VERSION ""

NS_ :

BS_:

BU_: Shelf7 Shelf6 Shelf5 Shelf4 Shelf3 DebugLaptop RackController Shelf2 Shelf1
VAL_TABLE_ ShelfThermal_FanState_Table 3 "Fan Locked Rotor" 2 "Fan Speed Slow" 1 "Fan Unplugged" 0 "Fan Nominal" ;
VAL_TABLE_ ModuleMultiplexor_Table 31 "Module 7, Max" 30 "Module 7, Avg" 29 "Module 7, Min" 27 "Module 6, Max" 26 "Module 6, Avg" 25 "Module 6, Min" 23 "Module 5, Max" 22 "Module 5, Avg" 21 "Module 5, Min" 19 "Module 4, Max" 18 "Module 4, Avg" 17 "Module 4, Min" 15 "Module 3, Max" 14 "Module 3, Avg" 13 "Module 3, Min" 11 "Module 2, Max" 10 "Module 2, Avg" 9 "Module 2, Min" 7 "Module 1, Max" 6 "Module 1, Avg" 5 "Module 1, Min" ;

BO_ 3221225472 VECTOR__INDEPENDENT_SIG_MSG: 0 Vector__XXX
 SG_ RackElectrical_24VPower : 0|8@1+ (1,0) [0|255] "W" Vector__XXX
 SG_ RackThermal_AvgCellTemp : 0|8@1+ (0.5,-40) [-40|87.5] "degC" Vector__XXX
 SG_ RackThermal_MinCellTemp : 0|8@1+ (0.5,-40) [-40|87.5] "degC" Vector__XXX
 SG_ RackThermal_MaxCellTemp : 0|8@1+ (0.5,-40) [-40|87.5] "degC" Vector__XXX
 SG_ RackThermal_AmbientTemp : 0|8@1+ (0.5,-40) [-40|87.5] "degC" Vector__XXX
 SG_ RackElectrical_StateOfCharge : 0|8@1+ (0.5,0) [0|100] "%" Vector__XXX
 SG_ RackElectrical_Current : 0|12@1+ (0.05,-102.4) [-100|100] "A" Vector__XXX
 SG_ RackElectrical_BusVoltage : 0|16@1+ (0.02,0) [0|830] "V" Vector__XXX
 SG_ RackElectrical_BatteryVoltage : 0|16@1+ (0.02,0) [0|830] "V" Vector__XXX
 SG_ SetBalanceFet_S1M3C18 : 0|1@1+ (1,0) [0|0] "" Vector__XXX
 SG_ SetBalanceFet_S1M3C17 : 0|1@1+ (1,0) [0|0] "" Vector__XXX
 SG_ SetBalanceFet_S1M3C16 : 0|1@1+ (1,0) [0|0] "" Vector__XXX
 SG_ SetBalanceFet_S1M3C15 : 0|1@1+ (1,0) [0|0] "" Vector__XXX
 SG_ SetBalanceFet_S1M3C14 : 0|1@1+ (1,0) [0|0] "" Vector__XXX
 SG_ SetBalanceFet_S1M3C13 : 0|1@1+ (1,0) [0|0] "" Vector__XXX
 SG_ SetBalanceFet_S1M3C12 : 0|1@1+ (1,0) [0|0] "" Vector__XXX
 SG_ SetBalanceFet_S1M3C11 : 0|1@1+ (1,0) [0|0] "" Vector__XXX
 SG_ SetBalanceFet_S1M3C10 : 0|1@1+ (1,0) [0|0] "" Vector__XXX
 SG_ SetBalanceFet_S1M3C09 : 0|1@1+ (1,0) [0|0] "" Vector__XXX
 SG_ SetBalanceFet_S1M3C08 : 0|1@1+ (1,0) [0|0] "" Vector__XXX
 SG_ SetBalanceFet_S1M3C07 : 0|1@1+ (1,0) [0|0] "" Vector__XXX
 SG_ SetBalanceFet_S1M3C06 : 0|1@1+ (1,0) [0|0] "" Vector__XXX
 SG_ SetBalanceFet_S1M3C05 : 0|1@1+ (1,0) [0|0] "" Vector__XXX
 SG_ SetBalanceFet_S1M3C04 : 0|1@1+ (1,0) [0|0] "" Vector__XXX
 SG_ SetBalanceFet_S1M3C03 : 0|1@1+ (1,0) [0|0] "" Vector__XXX
 SG_ SetBalanceFet_S1M3C02 : 0|1@1+ (1,0) [0|0] "" Vector__XXX
 SG_ SetBalanceFet_S1M3C01 : 0|1@1+ (1,0) [0|0] "" Vector__XXX
 SG_ SetBalanceFet_S1M2C18 : 0|1@1+ (1,0) [0|0] "" Vector__XXX
 SG_ SetBalanceFet_S1M2C17 : 0|1@1+ (1,0) [0|0] "" Vector__XXX
 SG_ SetBalanceFet_S1M2C16 : 0|1@1+ (1,0) [0|0] "" Vector__XXX
 SG_ SetBalanceFet_S1M2C15 : 0|1@1+ (1,0) [0|0] "" Vector__XXX
 SG_ SetBalanceFet_S1M2C14 : 0|1@1+ (1,0) [0|0] "" Vector__XXX
 SG_ SetBalanceFet_S1M2C13 : 0|1@1+ (1,0) [0|0] "" Vector__XXX
 SG_ SetBalanceFet_S1M2C12 : 0|1@1+ (1,0) [0|0] "" Vector__XXX
 SG_ SetBalanceFet_S1M2C11 : 0|1@1+ (1,0) [0|0] "" Vector__XXX
 SG_ SetBalanceFet_S1M2C10 : 0|1@1+ (1,0) [0|0] "" Vector__XXX
 SG_ SetBalanceFet_S1M2C09 : 0|1@1+ (1,0) [0|0] "" Vector__XXX
 SG_ SetBalanceFet_S1M2C08 : 0|1@1+ (1,0) [0|0] "" Vector__XXX
 SG_ SetBalanceFet_S1M2C07 : 0|1@1+ (1,0) [0|0] "" Vector__XXX
 SG_ SetBalanceFet_S1M2C06 : 0|1@1+ (1,0) [0|0] "" Vector__XXX
 SG_ SetBalanceFet_S1M2C05 : 0|1@1+ (1,0) [0|0] "" Vector__XXX
 SG_ SetBalanceFet_S1M2C04 : 0|1@1+ (1,0) [0|0] "" Vector__XXX
 SG_ SetBalanceFet_S1M2C03 : 0|1@1+ (1,0) [0|0] "" Vector__XXX
 SG_ SetBalanceFet_S1M2C02 : 0|1@1+ (1,0) [0|0] "" Vector__XXX
 SG_ SetBalanceFet_S1M2C01 : 0|1@1+ (1,0) [0|0] "" Vector__XXX
 SG_ SetBalanceFet_S1M1C18 : 0|1@1+ (1,0) [0|0] "" Vector__XXX
 SG_ SetBalanceFet_S1M1C17 : 0|1@1+ (1,0) [0|0] "" Vector__XXX
 SG_ SetBalanceFet_S1M1C16 : 0|1@1+ (1,0) [0|0] "" Vector__XXX
 SG_ SetBalanceFet_S1M1C15 : 0|1@1+ (1,0) [0|0] "" Vector__XXX
 SG_ SetBalanceFet_S1M1C14 : 0|1@1+ (1,0) [0|0] "" Vector__XXX
 SG_ SetBalanceFet_S1M1C13 : 0|1@1+ (1,0) [0|0] "" Vector__XXX
 SG_ SetBalanceFet_S1M1C12 : 0|1@1+ (1,0) [0|0] "" Vector__XXX
 SG_ SetBalanceFet_S1M1C11 : 0|1@1+ (1,0) [0|0] "" Vector__XXX
 SG_ SetBalanceFet_S1M1C10 : 0|1@1+ (1,0) [0|0] "" Vector__XXX
 SG_ SetBalanceFet_S1M1C09 : 0|1@1+ (1,0) [0|0] "" Vector__XXX
 SG_ SetBalanceFet_S1M1C08 : 0|1@1+ (1,0) [0|0] "" Vector__XXX
 SG_ SetBalanceFet_S1M1C07 : 0|1@1+ (1,0) [0|0] "" Vector__XXX
 SG_ SetBalanceFet_S1M1C06 : 0|1@1+ (1,0) [0|0] "" Vector__XXX
 SG_ SetBalanceFet_S1M1C05 : 0|1@1+ (1,0) [0|0] "" Vector__XXX
 SG_ SetBalanceFet_S1M1C04 : 0|1@1+ (1,0) [0|0] "" Vector__XXX
 SG_ SetBalanceFet_S1M1C03 : 0|1@1+ (1,0) [0|0] "" Vector__XXX
 SG_ SetBalanceFet_S1M1C02 : 0|1@1+ (1,0) [0|0] "" Vector__XXX
 SG_ SetBalanceFet_S1M1C01 : 0|1@1+ (1,0) [0|0] "" Vector__XXX
 SG_ BalanceModuleMultiplexor : 0|6@1+ (1,0) [0|0] "" Vector__XXX
 SG_ SetpointLimit_WhichShelves : 0|8@1+ (1,0) [0|255] "" Vector__XXX
 SG_ SetpointLimit_UndervoltageLevel : 0|13@1+ (0.000610426077402027,0) [0|5] "V" Vector__XXX
 SG_ SetpointLimit_OvervoltageLevel : 0|13@1+ (0.000610426077402027,0) [0|5] "V" Vector__XXX
 SG_ SetpointLimit_Overtemp : 0|8@1+ (0.5,-40) [-40|87.5] "degC" Vector__XXX
 SG_ SetpointLimit_24VPowerLimit : 0|8@1+ (0.25,0) [0|63.75] "W" Vector__XXX
 SG_ ShelfParamMultiplexor_S1 : 0|1@1+ (1,0) [0|1] "" Vector__XXX
 SG_ ShelfParam_TopBalanceVolt_S1 : 0|13@1+ (0.000610426077402027,0) [0|5] "V" Vector__XXX
 SG_ ShelfParam_TargetBalanceVolt_S1 : 0|13@1+ (0.000610426077402027,0) [0|5] "V" Vector__XXX
 SG_ ShelfParam_DeltaBalanceVolt_S1 : 0|11@1+ (0.000610426077402027,0) [0|1.24954218044195] "V" Vector__XXX
 SG_ ShelfParam_BottomBalanceVolt_S1 : 0|13@1+ (0.000610426077402027,0) [0|5] "V" Vector__XXX
 SG_ ShelfParam_BalanceTurnOnVolt_S1 : 0|13@1+ (0.000610426077402027,0) [0|5] "V" Vector__XXX
 SG_ ShelfParam_BalanceTurnOffVolt_S1 : 0|13@1+ (0.000610426077402027,0) [0|5] "V" Vector__XXX
 SG_ SetpointThermal_MinTurnOn : 0|8@1+ (0.5,0) [0|0] "%" Vector__XXX
 SG_ SetpointThermal_LoopGain : 0|8@1+ (1,0) [0|0] "" Vector__XXX
 SG_ SetpointThermal_WhichShelves : 0|8@1+ (1,0) [0|255] "" Vector__XXX
 SG_ SetpointThermal_MinCell : 0|8@1+ (0.5,-40) [-40|87.5] "degC" Vector__XXX
 SG_ SetpointThermal_MaxChip : 0|8@1+ (0.5,-40) [-40|87.5] "degC" Vector__XXX
 SG_ SetpointThermal_MaxCell : 0|8@1+ (0.5,-40) [-40|87.5] "degC" Vector__XXX
 SG_ SetpointThermal_Delta_Shelf : 0|8@1+ (0.1,0) [0|25.5] "degC" Vector__XXX
 SG_ SetpointThermal_Delta_Module : 0|8@1+ (0.1,0) [0|25.5] "degC" Vector__XXX
 SG_ SetpointElec_External_WhichShelv : 0|8@1+ (1,0) [0|255] "" Vector__XXX
 SG_ SetpointElec_External_TargetBala : 0|13@1+ (0.000610426077402027,0) [0|5] "V" Vector__XXX
 SG_ SetpointElec_External_DeltaBalan : 0|11@1+ (0.000610426077402027,0) [0|1.24954218044195] "V" Vector__XXX
 SG_ SetpointElec_External_BottomBala : 0|13@1+ (0.000610426077402027,0) [0|5] "V" Vector__XXX
 SG_ ShelfThermal_LoopGain_S1 : 0|8@1+ (1,0) [0|0] "" Vector__XXX
 SG_ ShelfThermal_FanStateSummary_S1 : 0|2@1+ (1,0) [0|3] "" Vector__XXX
 SG_ ShelfThermal_FanSpeedAvg_S1 : 0|9@1+ (10,0) [0|5110] "RPM" Vector__XXX
 SG_ ShelfThermal_FanCommandAvg_S1 : 0|7@1+ (1,0) [0|100] "%" Vector__XXX
 SG_ ShelfThermal_FanState_S1FR : 0|2@1+ (1,0) [0|3] "" Vector__XXX
 SG_ ShelfThermal_FanState_S1FM : 0|2@1+ (1,0) [0|3] "" Vector__XXX
 SG_ ShelfThermal_FanState_S1FL : 0|2@1+ (1,0) [0|3] "" Vector__XXX
 SG_ ShelfThermalMultiplexor_S1 : 0|2@1+ (1,0) [0|3] "" Vector__XXX
 SG_ ShelfThermal_FanCommand_S1FR : 0|7@1+ (1,0) [0|100] "%" Vector__XXX
 SG_ ShelfThermal_FanCommand_S1FM : 0|7@1+ (1,0) [0|100] "%" Vector__XXX
 SG_ ShelfThermal_ActualTempDelta_S1 : 0|6@1+ (0.5,0) [0|31.5] "degC" Vector__XXX
 SG_ ShelfThermal_ActuallTempMax_S1 : 0|8@1+ (0.5,-40) [-40|87.5] "degC" Vector__XXX
 SG_ ShelfThermal_TargetTempMax_S1 : 0|8@1+ (0.5,-40) [-40|87.5] "degC" Vector__XXX
 SG_ ShelfThermal_TargetTempDelta_S1 : 0|6@1+ (0.5,0) [0|31.5] "degC" Vector__XXX
 SG_ ShelfThermal_FanSpeed_S1FR : 0|9@1+ (10,0) [0|5110] "RPM" Vector__XXX
 SG_ ShelfThermal_FanSpeed_S1FM : 0|9@1+ (10,0) [0|5110] "RPM" Vector__XXX
 SG_ ShelfThermal_FanSpeed_S1FL : 0|9@1+ (10,0) [0|5110] "RPM" Vector__XXX
 SG_ ShelfThermal_FanCommand_S1FL : 0|7@1+ (1,0) [0|100] "%" Vector__XXX
 SG_ ShelfThermal_AmbientTemp_S1 : 0|8@1+ (0.5,-40) [-40|87.5] "degC" Vector__XXX
 SG_ ChipSummaryVoltage_Min_S1 : 0|12@1+ (0.00732511292882432,0) [0|16] "V" Vector__XXX
 SG_ ChipSummaryVoltage_Max_S1 : 0|12@1+ (0.00732511292882432,0) [0|16] "V" Vector__XXX
 SG_ ChipSummaryVoltage_Avg_S1 : 0|12@1+ (0.00732511292882432,0) [0|16] "V" Vector__XXX
 SG_ ChipSummaryTemp_Min_S1 : 0|8@1+ (0.5,-40) [-40|87.5] "degC" Vector__XXX
 SG_ ChipSummaryTemp_Max_S1 : 0|8@1+ (0.5,-40) [-40|87.5] "degC" Vector__XXX
 SG_ ChipSummaryTemp_Avg_S1 : 0|8@1+ (0.5,-40) [-40|87.5] "degC" Vector__XXX
 SG_ ChipSummaryNumberOfChips : 0|4@1+ (1,0) [0|14] "" Vector__XXX
 SG_ ChipSummaryMultiplexor : 0|2@1+ (1,0) [0|3] "" Vector__XXX
 SG_ ChipSummaryFault_Watchdog_S1 : 0|1@1+ (1,0) [0|0] "" Vector__XXX
 SG_ ChipSummaryFault_VssOpen_S1 : 0|1@1+ (1,0) [0|0] "" Vector__XXX
 SG_ ChipSummaryFault_Vreg_S1 : 0|1@1+ (1,0) [0|0] "" Vector__XXX
 SG_ ChipSummaryFault_Vref_S1 : 0|1@1+ (1,0) [0|0] "" Vector__XXX
 SG_ ChipSummaryFault_VbatOpen_S1 : 0|1@1+ (1,0) [0|0] "" Vector__XXX
 SG_ ChipSummaryFault_UnderVolt_S1 : 0|1@1+ (1,0) [0|0] "" Vector__XXX
 SG_ ChipSummaryFault_OverVolt_S1 : 0|1@1+ (1,0) [0|0] "" Vector__XXX
 SG_ ChipSummaryFault_OverTemp_S1 : 0|1@1+ (1,0) [0|0] "" Vector__XXX
 SG_ ChipSummaryFault_Oscillator_S1 : 0|1@1+ (1,0) [0|0] "" Vector__XXX
 SG_ ChipSummaryFault_OpenWire_S1 : 0|1@1+ (1,0) [0|0] "" Vector__XXX
 SG_ ChipSummaryFault_Mux_S1 : 0|1@1+ (1,0) [0|0] "" Vector__XXX
 SG_ ChipSummaryFault_Checksum_S1 : 0|1@1+ (1,0) [0|0] "" Vector__XXX
 SG_ ChipSummaryCommSpeed : 0|2@1+ (1,0) [0|3] "" Vector__XXX
 SG_ ChipVoltage_S1M1Low : 0|12@1+ (0.00732511292882432,0) [0|16] "V" Vector__XXX
 SG_ ChipVoltage_S1M1High : 0|12@1+ (0.00732511292882432,0) [0|16] "V" Vector__XXX
 SG_ ChipVoltage_S1M2Low : 0|12@1+ (0.00732511292882432,0) [0|16] "V" Vector__XXX
 SG_ ChipVoltage_S1M2High : 0|12@1+ (0.00732511292882432,0) [0|16] "V" Vector__XXX
 SG_ ChipVoltage_S1M3Low : 0|12@1+ (0.00732511292882432,0) [0|16] "V" Vector__XXX
 SG_ ChipVoltage_S1M3High : 0|12@1+ (0.00732511292882432,0) [0|16] "V" Vector__XXX
 SG_ ChipVoltage_S1M4Low : 0|12@1+ (0.00732511292882432,0) [0|16] "V" Vector__XXX
 SG_ ChipVoltage_S1M4High : 0|12@1+ (0.00732511292882432,0) [0|16] "V" Vector__XXX
 SG_ ChipVoltage_S1M5Low : 0|12@1+ (0.00732511292882432,0) [0|16] "V" Vector__XXX
 SG_ ChipVoltage_S1M5High : 0|12@1+ (0.00732511292882432,0) [0|16] "V" Vector__XXX
 SG_ ChipTemp_S1M1Low : 0|8@1+ (0.5,-40) [-40|87.5] "degC" Vector__XXX
 SG_ ChipTemp_S1M1High : 0|8@1+ (0.5,-40) [-40|87.5] "degC" Vector__XXX
 SG_ ChipTemp_S1M2Low : 0|8@1+ (0.5,-40) [-40|87.5] "degC" Vector__XXX
 SG_ ChipTemp_S1M2High : 0|8@1+ (0.5,-40) [-40|87.5] "degC" Vector__XXX
 SG_ ChipTemp_S1M3Low : 0|8@1+ (0.5,-40) [-40|87.5] "degC" Vector__XXX
 SG_ ChipTemp_S1M3High : 0|8@1+ (0.5,-40) [-40|87.5] "degC" Vector__XXX
 SG_ ChipTemp_S1M4Low : 0|8@1+ (0.5,-40) [-40|87.5] "degC" Vector__XXX
 SG_ ChipTemp_S1M4High : 0|8@1+ (0.5,-40) [-40|87.5] "degC" Vector__XXX
 SG_ ChipTemp_S1M5Low : 0|8@1+ (0.5,-40) [-40|87.5] "degC" Vector__XXX
 SG_ ChipTemp_S1M5High : 0|8@1+ (0.5,-40) [-40|87.5] "degC" Vector__XXX
 SG_ ChipSerialNumber_S1M1Low : 0|28@1+ (1,0) [0|0] "" Vector__XXX
 SG_ ChipSerialNumber_S1M1High : 0|28@1+ (1,0) [0|0] "" Vector__XXX
 SG_ ChipSerialNumber_S1M2Low : 0|28@1+ (1,0) [0|0] "" Vector__XXX
 SG_ ChipSerialNumber_S1M2High : 0|28@1+ (1,0) [0|0] "" Vector__XXX
 SG_ ChipSerialNumber_S1M3Low : 0|28@1+ (1,0) [0|0] "" Vector__XXX
 SG_ ChipSerialNumber_S1M3High : 0|28@1+ (1,0) [0|0] "" Vector__XXX
 SG_ ChipSerialNumber_S1M4Low : 0|28@1+ (1,0) [0|0] "" Vector__XXX
 SG_ ChipSerialNumber_S1M4High : 0|28@1+ (1,0) [0|0] "" Vector__XXX
 SG_ ChipSerialNumber_S1M5Low : 0|28@1+ (1,0) [0|0] "" Vector__XXX
 SG_ ChipSerialNumber_S1M5High : 0|28@1+ (1,0) [0|0] "" Vector__XXX
 SG_ ChipFault_Watchdog_S1M1Low : 0|1@1+ (1,0) [0|0] "" Vector__XXX
 SG_ ChipFault_Watchdog_S1M1High : 0|1@1+ (1,0) [0|0] "" Vector__XXX
 SG_ ChipFault_Watchdog_S1M2Low : 0|1@1+ (1,0) [0|0] "" Vector__XXX
 SG_ ChipFault_Watchdog_S1M2High : 0|1@1+ (1,0) [0|0] "" Vector__XXX
 SG_ ChipFault_Watchdog_S1M3Low : 0|1@1+ (1,0) [0|0] "" Vector__XXX
 SG_ ChipFault_Watchdog_S1M3High : 0|1@1+ (1,0) [0|0] "" Vector__XXX
 SG_ ChipFault_Watchdog_S1M4Low : 0|1@1+ (1,0) [0|0] "" Vector__XXX
 SG_ ChipFault_Watchdog_S1M4High : 0|1@1+ (1,0) [0|0] "" Vector__XXX
 SG_ ChipFault_Watchdog_S1M5Low : 0|1@1+ (1,0) [0|0] "" Vector__XXX
 SG_ ChipFault_Watchdog_S1M5High : 0|1@1+ (1,0) [0|0] "" Vector__XXX
 SG_ ChipFault_VssOpen_S1M1Low : 0|1@1+ (1,0) [0|0] "" Vector__XXX
 SG_ ChipFault_VssOpen_S1M1High : 0|1@1+ (1,0) [0|0] "" Vector__XXX
 SG_ ChipFault_VssOpen_S1M2Low : 0|1@1+ (1,0) [0|0] "" Vector__XXX
 SG_ ChipFault_VssOpen_S1M2High : 0|1@1+ (1,0) [0|0] "" Vector__XXX
 SG_ ChipFault_VssOpen_S1M3Low : 0|1@1+ (1,0) [0|0] "" Vector__XXX
 SG_ ChipFault_VssOpen_S1M3High : 0|1@1+ (1,0) [0|0] "" Vector__XXX
 SG_ ChipFault_VssOpen_S1M4Low : 0|1@1+ (1,0) [0|0] "" Vector__XXX
 SG_ ChipFault_VssOpen_S1M41High : 0|1@1+ (1,0) [0|0] "" Vector__XXX
 SG_ ChipFault_VssOpen_S1M5Low : 0|1@1+ (1,0) [0|0] "" Vector__XXX
 SG_ ChipFault_VssOpen_S1M5High : 0|1@1+ (1,0) [0|0] "" Vector__XXX
 SG_ ChipFault_Vreg_S1M1Low : 0|1@1+ (1,0) [0|0] "" Vector__XXX
 SG_ ChipFault_Vreg_S1M1High : 0|1@1+ (1,0) [0|0] "" Vector__XXX
 SG_ ChipFault_Vreg_S1M2Low : 0|1@1+ (1,0) [0|0] "" Vector__XXX
 SG_ ChipFault_Vreg_S1M2High : 0|1@1+ (1,0) [0|0] "" Vector__XXX
 SG_ ChipFault_Vreg_S1M3Low : 0|1@1+ (1,0) [0|0] "" Vector__XXX
 SG_ ChipFault_Vreg_S1M3High : 0|1@1+ (1,0) [0|0] "" Vector__XXX
 SG_ ChipFault_Vreg_S1M4Low : 0|1@1+ (1,0) [0|0] "" Vector__XXX
 SG_ ChipFault_Vreg_S1M4High : 0|1@1+ (1,0) [0|0] "" Vector__XXX
 SG_ ChipFault_Vreg_S1M5Low : 0|1@1+ (1,0) [0|0] "" Vector__XXX
 SG_ ChipFault_Vreg_S1M5High : 0|1@1+ (1,0) [0|0] "" Vector__XXX
 SG_ ChipFault_Vref_S1M1Low : 0|1@1+ (1,0) [0|0] "" Vector__XXX
 SG_ ChipFault_Vref_S1M1High : 0|1@1+ (1,0) [0|0] "" Vector__XXX
 SG_ ChipFault_VbatOpen_S1M1Low : 0|1@1+ (1,0) [0|0] "" Vector__XXX
 SG_ ChipFault_VbatOpen_S1M1High : 0|1@1+ (1,0) [0|0] "" Vector__XXX
 SG_ ChipFault_VbatOpen_S1M2Low : 0|1@1+ (1,0) [0|0] "" Vector__XXX
 SG_ ChipFault_VbatOpen_S1M2High : 0|1@1+ (1,0) [0|0] "" Vector__XXX
 SG_ ChipFault_VbatOpen_S1M3Low : 0|1@1+ (1,0) [0|0] "" Vector__XXX
 SG_ ChipFault_VbatOpen_S1M3High : 0|1@1+ (1,0) [0|0] "" Vector__XXX
 SG_ ChipFault_VbatOpen_S1M4Low : 0|1@1+ (1,0) [0|0] "" Vector__XXX
 SG_ ChipFault_VbatOpen_S1M4High : 0|1@1+ (1,0) [0|0] "" Vector__XXX
 SG_ ChipFault_VbatOpen_S1M5Low : 0|1@1+ (1,0) [0|0] "" Vector__XXX
 SG_ ChipFault_VbatOpen_S1M5High : 0|1@1+ (1,0) [0|0] "" Vector__XXX
 SG_ ChipFault_UnderVolt_S1M1Low : 0|1@1+ (1,0) [0|0] "" Vector__XXX
 SG_ ChipFault_UnderVolt_S1M1High : 0|1@1+ (1,0) [0|0] "" Vector__XXX
 SG_ ChipFault_UnderVolt_S1M2Low : 0|1@1+ (1,0) [0|0] "" Vector__XXX
 SG_ ChipFault_UnderVolt_S1M2High : 0|1@1+ (1,0) [0|0] "" Vector__XXX
 SG_ ChipFault_UnderVolt_S1M3Low : 0|1@1+ (1,0) [0|0] "" Vector__XXX
 SG_ ChipFault_UnderVolt_S1M3High : 0|1@1+ (1,0) [0|0] "" Vector__XXX
 SG_ ChipFault_UnderVolt_S1M4Low : 0|1@1+ (1,0) [0|0] "" Vector__XXX
 SG_ ChipFault_UnderVolt_S1M4High : 0|1@1+ (1,0) [0|0] "" Vector__XXX
 SG_ ChipFault_UnderVolt_S1M5Low : 0|1@1+ (1,0) [0|0] "" Vector__XXX
 SG_ ChipFault_UnderVolt_S1M5High : 0|1@1+ (1,0) [0|0] "" Vector__XXX
 SG_ ChipFault_OverVolt_S1M1Low : 0|1@1+ (1,0) [0|0] "" Vector__XXX
 SG_ ChipFault_OverVolt_S1M1High : 0|1@1+ (1,0) [0|0] "" Vector__XXX
 SG_ ChipFault_OverVolt_S1M2Low : 0|1@1+ (1,0) [0|0] "" Vector__XXX
 SG_ ChipFault_OverVolt_S1M2High : 0|1@1+ (1,0) [0|0] "" Vector__XXX
 SG_ ChipFault_OverVolt_S1M3Low : 0|1@1+ (1,0) [0|0] "" Vector__XXX
 SG_ ChipFault_OverVolt_S1M3High : 0|1@1+ (1,0) [0|0] "" Vector__XXX
 SG_ ChipFault_OverVolt_S1M4Low : 0|1@1+ (1,0) [0|0] "" Vector__XXX
 SG_ ChipFault_OverVolt_S1M4High : 0|1@1+ (1,0) [0|0] "" Vector__XXX
 SG_ ChipFault_OverVolt_S1M5Low : 0|1@1+ (1,0) [0|0] "" Vector__XXX
 SG_ ChipFault_OverVolt_S1M5High : 0|1@1+ (1,0) [0|0] "" Vector__XXX
 SG_ ChipFault_OverTemp_S1M1Low : 0|1@1+ (1,0) [0|0] "" Vector__XXX
 SG_ ChipFault_OverTemp_S1M1High : 0|1@1+ (1,0) [0|0] "" Vector__XXX
 SG_ ChipFault_Oscillator_S1M1Low : 0|1@1+ (1,0) [0|0] "" Vector__XXX
 SG_ ChipFault_Oscillator_S1M1High : 0|1@1+ (1,0) [0|0] "" Vector__XXX
 SG_ ChipFault_Oscillator_S1M2Low : 0|1@1+ (1,0) [0|0] "" Vector__XXX
 SG_ ChipFault_Oscillator_S1M2High : 0|1@1+ (1,0) [0|0] "" Vector__XXX
 SG_ ChipFault_Oscillator_S1M3Low : 0|1@1+ (1,0) [0|0] "" Vector__XXX
 SG_ ChipFault_Oscillator_S1M3High : 0|1@1+ (1,0) [0|0] "" Vector__XXX
 SG_ ChipFault_Oscillator_S1M4Low : 0|1@1+ (1,0) [0|0] "" Vector__XXX
 SG_ ChipFault_Oscillator_S1M4High : 0|1@1+ (1,0) [0|0] "" Vector__XXX
 SG_ ChipFault_Oscillator_S1M5Low : 0|1@1+ (1,0) [0|0] "" Vector__XXX
 SG_ ChipFault_Oscillator_S1M5High : 0|1@1+ (1,0) [0|0] "" Vector__XXX
 SG_ ChipFault_OpenWire_S1M1Low : 0|1@1+ (1,0) [0|0] "" Vector__XXX
 SG_ ChipFault_OpenWire_S1M1High : 0|1@1+ (1,0) [0|0] "" Vector__XXX
 SG_ ChipFault_OpenWire_S1M2Low : 0|1@1+ (1,0) [0|0] "" Vector__XXX
 SG_ ChipFault_OpenWire_S1M2High : 0|1@1+ (1,0) [0|0] "" Vector__XXX
 SG_ ChipFault_OpenWire_S1M3Low : 0|1@1+ (1,0) [0|0] "" Vector__XXX
 SG_ ChipFault_OpenWire_S1M3High : 0|1@1+ (1,0) [0|0] "" Vector__XXX
 SG_ ChipFault_OpenWire_S1M4Low : 0|1@1+ (1,0) [0|0] "" Vector__XXX
 SG_ ChipFault_OpenWire_S1M4High : 0|1@1+ (1,0) [0|0] "" Vector__XXX
 SG_ ChipFault_OpenWire_S1M5Low : 0|1@1+ (1,0) [0|0] "" Vector__XXX
 SG_ ChipFault_OpenWire_S1M5High : 0|1@1+ (1,0) [0|0] "" Vector__XXX
 SG_ ChipFault_Mux_S1M1Low : 0|1@1+ (1,0) [0|0] "" Vector__XXX
 SG_ ChipFault_Mux_S1M1High : 0|1@1+ (1,0) [0|0] "" Vector__XXX
 SG_ ChipFault_Mux_S1M2Low : 0|1@1+ (1,0) [0|0] "" Vector__XXX
 SG_ ChipFault_Mux_S1M2High : 0|1@1+ (1,0) [0|0] "" Vector__XXX
 SG_ ChipFault_Mux_S1M3Low : 0|1@1+ (1,0) [0|0] "" Vector__XXX
 SG_ ChipFault_Mux_S1M3High : 0|1@1+ (1,0) [0|0] "" Vector__XXX
 SG_ ChipFault_Mux_S1M4Low : 0|1@1+ (1,0) [0|0] "" Vector__XXX
 SG_ ChipFault_Mux_S1M4High : 0|1@1+ (1,0) [0|0] "" Vector__XXX
 SG_ ChipFault_Mux_S1M5Low : 0|1@1+ (1,0) [0|0] "" Vector__XXX
 SG_ ChipFault_Mux_S1M5High : 0|1@1+ (1,0) [0|0] "" Vector__XXX
 SG_ ChipFault_Checksum_S1M1Low : 0|1@1+ (1,0) [0|0] "" Vector__XXX
 SG_ ChipFault_Checksum_S1M1High : 0|1@1+ (1,0) [0|0] "" Vector__XXX
 SG_ ChipFault_Checksum_S1M2Low : 0|1@1+ (1,0) [0|0] "" Vector__XXX
 SG_ ChipFault_Checksum_S1M2High : 0|1@1+ (1,0) [0|0] "" Vector__XXX
 SG_ ChipFault_Checksum_S1M3Low : 0|1@1+ (1,0) [0|0] "" Vector__XXX
 SG_ ChipFault_Checksum_S1M3High : 0|1@1+ (1,0) [0|0] "" Vector__XXX
 SG_ ChipFault_Checksum_S1M4Low : 0|1@1+ (1,0) [0|0] "" Vector__XXX
 SG_ ChipFault_Checksum_S1M4High : 0|1@1+ (1,0) [0|0] "" Vector__XXX
 SG_ ChipFault_Checksum_S1M5Low : 0|1@1+ (1,0) [0|0] "" Vector__XXX
 SG_ ChipFault_Checksum_S1M5High : 0|1@1+ (1,0) [0|0] "" Vector__XXX
 SG_ ChipMultiplexor : 0|4@1+ (1,0) [0|14] "" Vector__XXX
 SG_ PEC_Shelf_Avg_Cell_Voltage : 0|13@1- (0.000610426077402027,0) [0|0] "v" Vector__XXX
 SG_ Debug2_Shelf1_M9 : 0|16@1+ (1,0) [0|0] "" Vector__XXX
 SG_ Debug2_Shelf1_M8 : 0|16@1+ (1,0) [0|0] "" Vector__XXX
 SG_ Debug2_Shelf1_M7 : 0|16@1+ (1,0) [0|0] "" Vector__XXX
 SG_ Debug2_Shelf1_M6 : 0|16@1+ (1,0) [0|0] "" Vector__XXX
 SG_ Debug2_Shelf1_M5 : 0|16@1+ (1,0) [0|0] "" Vector__XXX
 SG_ Debug2_Shelf1_M15 : 0|16@1+ (1,0) [0|0] "" Vector__XXX
 SG_ Debug2_Shelf1_M14 : 0|16@1+ (1,0) [0|0] "" Vector__XXX
 SG_ Debug2_Shelf1_M13 : 0|16@1+ (1,0) [0|0] "" Vector__XXX
 SG_ Debug2_Shelf1_M12 : 0|16@1+ (1,0) [0|0] "" Vector__XXX
 SG_ Debug2_Shelf1_M11 : 0|16@1+ (1,0) [0|0] "" Vector__XXX
 SG_ Debug2_Shelf1_M10 : 0|16@1+ (1,0) [0|0] "" Vector__XXX
 SG_ Debug2_Shelf1_M4 : 0|16@1+ (1,0) [0|0] "" Vector__XXX
 SG_ Debug2_Shelf1_M3 : 0|16@1+ (1,0) [0|0] "" Vector__XXX
 SG_ Debug2_Shelf1_M2 : 0|16@1+ (1,0) [0|0] "" Vector__XXX
 SG_ Debug2_Shelf1_Multiplexor : 0|5@1+ (1,0) [0|0] "" Vector__XXX
 SG_ Debug2_Shelf1_M1 : 0|16@1+ (1,0) [0|0] "" Vector__XXX

BO_ 903 Shelf_Summary_Shelf7: 8 Shelf7
 SG_ Shelf_IDJumpers_S1 : 52|4@1+ (1,0) [0|15] "" Vector__XXX
 SG_ Shelf_NumTempSensorsPerModule_S1 m2 : 35|3@1+ (1,0) [0|7] "" Vector__XXX
 SG_ Shelf_NumModulesPerShelf_S1 m2 : 16|3@1+ (1,0) [0|7] "" Vector__XXX
 SG_ Shelf_NumCellsPerModule_S1 m2 : 19|5@1+ (1,0) [0|18] "" Vector__XXX
 SG_ Shelf_NumCellsInTotal_S1 m2 : 56|7@1+ (1,0) [0|126] "" Vector__XXX
 SG_ Shelf_NumCellsInFault_S1 m1 : 56|7@1+ (1,0) [0|126] "" Vector__XXX
 SG_ Shelf_CellFault_UnderTemp_S1 m1 : 38|1@1+ (1,0) [0|0] "" Vector__XXX
 SG_ Shelf_CellFault_TempSensor_S1 m2 : 38|1@1+ (1,0) [0|0] "" Vector__XXX
 SG_ Shelf_CellFault_UnderVoltage_S1 m1 : 15|1@1+ (1,0) [0|0] "" Vector__XXX
 SG_ Shelf_CellFault_OverVoltage_S1 m3 : 15|1@1+ (1,0) [0|0] "" Vector__XXX
 SG_ Shelf_CellFault_OverTemp_S1 m3 : 38|1@1+ (1,0) [0|0] "" Vector__XXX
 SG_ Shelf_CellFault_OpenWire_S1 m2 : 15|1@1+ (1,0) [0|0] "" Vector__XXX
 SG_ Shelf_BalanceMode_Top_S1 m3 : 63|1@1+ (1,0) [0|0] "" Vector__XXX
 SG_ Shelf_BalanceMode_Target_S1 : 39|1@1+ (1,0) [0|0] "" Vector__XXX
 SG_ Shelf_BalanceMode_Delta_S1 m2 : 63|1@1+ (1,0) [0|0] "" Vector__XXX
 SG_ Shelf_BalanceMode_Bottom_S1 m1 : 63|1@1+ (1,0) [0|0] "" Vector__XXX
 SG_ Shelf_ShelfVoltageNow_S1 m2 : 40|12@1+ (0.1,0) [0|215] "V" Vector__XXX
 SG_ Shelf_ShelfVoltageMin_S1 m1 : 40|12@1+ (0.1,0) [0|215] "V" Vector__XXX
 SG_ Shelf_ShelfVoltageMax_S1 m3 : 40|12@1+ (0.1,0) [0|215] "V" Vector__XXX
 SG_ Shelf_NumCellsInBalance_S1 m3 : 56|7@1+ (1,0) [0|126] "" Vector__XXX
 SG_ Shelf_Multiplexor_S1 M : 0|2@1+ (1,0) [0|3] "" Vector__XXX
 SG_ Shelf_CellVoltageMinModule_S1 m1 : 16|3@1+ (1,0) [0|7] "" Vector__XXX
 SG_ Shelf_CellVoltageMinCell_S1 m1 : 19|5@1+ (1,0) [0|18] "" Vector__XXX
 SG_ Shelf_CellVoltageMin_S1 m1 : 2|13@1+ (0.000610426077402027,0) [0|5] "V" Vector__XXX
 SG_ Shelf_CellVoltageMaxModule_S1 m3 : 16|3@1+ (1,0) [0|7] "" Vector__XXX
 SG_ Shelf_CellVoltageMaxCell_S1 m3 : 19|5@1+ (1,0) [0|18] "" Vector__XXX
 SG_ Shelf_CellVoltageMax_S1 m3 : 2|13@1+ (0.000610426077402027,0) [0|5] "V" Vector__XXX
 SG_ Shelf_CellVoltageAvg_S1 m2 : 2|13@1+ (0.000610426077402027,0) [0|5] "V" Vector__XXX
 SG_ Shelf_CellTempMinModule_S1 m1 : 32|3@1+ (1,0) [0|7] "" Vector__XXX
 SG_ Shelf_CellTempMinSensor_S1 m1 : 35|3@1+ (1,0) [0|7] "" Vector__XXX
 SG_ Shelf_CellTempMin_S1 m1 : 24|8@1+ (0.5,-40) [-40|87.5] "degC" Vector__XXX
 SG_ Shelf_CellTempMaxModule_S1 m3 : 32|3@1+ (1,0) [0|7] "" Vector__XXX
 SG_ Shelf_CellTempMaxSensor_S1 m3 : 35|3@1+ (1,0) [0|7] "" Vector__XXX
 SG_ Shelf_CellTempMax_S1 m3 : 24|8@1+ (0.5,-40) [-40|87.5] "degC" Vector__XXX
 SG_ Shelf_CellTempAvg_S1 m2 : 24|8@1+ (0.5,-40) [-40|87.5] "degC" Vector__XXX

BO_ 902 Shelf_Summary_Shelf6: 8 Shelf6
 SG_ Shelf_IDJumpers_S1 : 52|4@1+ (1,0) [0|15] "" Vector__XXX
 SG_ Shelf_NumTempSensorsPerModule_S1 m2 : 35|3@1+ (1,0) [0|7] "" Vector__XXX
 SG_ Shelf_NumModulesPerShelf_S1 m2 : 16|3@1+ (1,0) [0|7] "" Vector__XXX
 SG_ Shelf_NumCellsPerModule_S1 m2 : 19|5@1+ (1,0) [0|18] "" Vector__XXX
 SG_ Shelf_NumCellsInTotal_S1 m2 : 56|7@1+ (1,0) [0|126] "" Vector__XXX
 SG_ Shelf_NumCellsInFault_S1 m1 : 56|7@1+ (1,0) [0|126] "" Vector__XXX
 SG_ Shelf_CellFault_UnderTemp_S1 m1 : 38|1@1+ (1,0) [0|0] "" Vector__XXX
 SG_ Shelf_CellFault_TempSensor_S1 m2 : 38|1@1+ (1,0) [0|0] "" Vector__XXX
 SG_ Shelf_CellFault_UnderVoltage_S1 m1 : 15|1@1+ (1,0) [0|0] "" Vector__XXX
 SG_ Shelf_CellFault_OverVoltage_S1 m3 : 15|1@1+ (1,0) [0|0] "" Vector__XXX
 SG_ Shelf_CellFault_OverTemp_S1 m3 : 38|1@1+ (1,0) [0|0] "" Vector__XXX
 SG_ Shelf_CellFault_OpenWire_S1 m2 : 15|1@1+ (1,0) [0|0] "" Vector__XXX
 SG_ Shelf_BalanceMode_Top_S1 m3 : 63|1@1+ (1,0) [0|0] "" Vector__XXX
 SG_ Shelf_BalanceMode_Target_S1 : 39|1@1+ (1,0) [0|0] "" Vector__XXX
 SG_ Shelf_BalanceMode_Delta_S1 m2 : 63|1@1+ (1,0) [0|0] "" Vector__XXX
 SG_ Shelf_BalanceMode_Bottom_S1 m1 : 63|1@1+ (1,0) [0|0] "" Vector__XXX
 SG_ Shelf_ShelfVoltageNow_S1 m2 : 40|12@1+ (0.1,0) [0|215] "V" Vector__XXX
 SG_ Shelf_ShelfVoltageMin_S1 m1 : 40|12@1+ (0.1,0) [0|215] "V" Vector__XXX
 SG_ Shelf_ShelfVoltageMax_S1 m3 : 40|12@1+ (0.1,0) [0|215] "V" Vector__XXX
 SG_ Shelf_NumCellsInBalance_S1 m3 : 56|7@1+ (1,0) [0|126] "" Vector__XXX
 SG_ Shelf_Multiplexor_S1 M : 0|2@1+ (1,0) [0|3] "" Vector__XXX
 SG_ Shelf_CellVoltageMinModule_S1 m1 : 16|3@1+ (1,0) [0|7] "" Vector__XXX
 SG_ Shelf_CellVoltageMinCell_S1 m1 : 19|5@1+ (1,0) [0|18] "" Vector__XXX
 SG_ Shelf_CellVoltageMin_S1 m1 : 2|13@1+ (0.000610426077402027,0) [0|5] "V" Vector__XXX
 SG_ Shelf_CellVoltageMaxModule_S1 m3 : 16|3@1+ (1,0) [0|7] "" Vector__XXX
 SG_ Shelf_CellVoltageMaxCell_S1 m3 : 19|5@1+ (1,0) [0|18] "" Vector__XXX
 SG_ Shelf_CellVoltageMax_S1 m3 : 2|13@1+ (0.000610426077402027,0) [0|5] "V" Vector__XXX
 SG_ Shelf_CellVoltageAvg_S1 m2 : 2|13@1+ (0.000610426077402027,0) [0|5] "V" Vector__XXX
 SG_ Shelf_CellTempMinModule_S1 m1 : 32|3@1+ (1,0) [0|7] "" Vector__XXX
 SG_ Shelf_CellTempMinSensor_S1 m1 : 35|3@1+ (1,0) [0|7] "" Vector__XXX
 SG_ Shelf_CellTempMin_S1 m1 : 24|8@1+ (0.5,-40) [-40|87.5] "degC" Vector__XXX
 SG_ Shelf_CellTempMaxModule_S1 m3 : 32|3@1+ (1,0) [0|7] "" Vector__XXX
 SG_ Shelf_CellTempMaxSensor_S1 m3 : 35|3@1+ (1,0) [0|7] "" Vector__XXX
 SG_ Shelf_CellTempMax_S1 m3 : 24|8@1+ (0.5,-40) [-40|87.5] "degC" Vector__XXX
 SG_ Shelf_CellTempAvg_S1 m2 : 24|8@1+ (0.5,-40) [-40|87.5] "degC" Vector__XXX

BO_ 901 Shelf_Summary_Shelf5: 8 Shelf5
 SG_ Shelf_IDJumpers_S1 : 52|4@1+ (1,0) [0|15] "" Vector__XXX
 SG_ Shelf_NumTempSensorsPerModule_S1 m2 : 35|3@1+ (1,0) [0|7] "" Vector__XXX
 SG_ Shelf_NumModulesPerShelf_S1 m2 : 16|3@1+ (1,0) [0|7] "" Vector__XXX
 SG_ Shelf_NumCellsPerModule_S1 m2 : 19|5@1+ (1,0) [0|18] "" Vector__XXX
 SG_ Shelf_NumCellsInTotal_S1 m2 : 56|7@1+ (1,0) [0|126] "" Vector__XXX
 SG_ Shelf_NumCellsInFault_S1 m1 : 56|7@1+ (1,0) [0|126] "" Vector__XXX
 SG_ Shelf_CellFault_UnderTemp_S1 m1 : 38|1@1+ (1,0) [0|0] "" Vector__XXX
 SG_ Shelf_CellFault_TempSensor_S1 m2 : 38|1@1+ (1,0) [0|0] "" Vector__XXX
 SG_ Shelf_CellFault_UnderVoltage_S1 m1 : 15|1@1+ (1,0) [0|0] "" Vector__XXX
 SG_ Shelf_CellFault_OverVoltage_S1 m3 : 15|1@1+ (1,0) [0|0] "" Vector__XXX
 SG_ Shelf_CellFault_OverTemp_S1 m3 : 38|1@1+ (1,0) [0|0] "" Vector__XXX
 SG_ Shelf_CellFault_OpenWire_S1 m2 : 15|1@1+ (1,0) [0|0] "" Vector__XXX
 SG_ Shelf_BalanceMode_Top_S1 m3 : 63|1@1+ (1,0) [0|0] "" Vector__XXX
 SG_ Shelf_BalanceMode_Target_S1 : 39|1@1+ (1,0) [0|0] "" Vector__XXX
 SG_ Shelf_BalanceMode_Delta_S1 m2 : 63|1@1+ (1,0) [0|0] "" Vector__XXX
 SG_ Shelf_BalanceMode_Bottom_S1 m1 : 63|1@1+ (1,0) [0|0] "" Vector__XXX
 SG_ Shelf_ShelfVoltageNow_S1 m2 : 40|12@1+ (0.1,0) [0|215] "V" Vector__XXX
 SG_ Shelf_ShelfVoltageMin_S1 m1 : 40|12@1+ (0.1,0) [0|215] "V" Vector__XXX
 SG_ Shelf_ShelfVoltageMax_S1 m3 : 40|12@1+ (0.1,0) [0|215] "V" Vector__XXX
 SG_ Shelf_NumCellsInBalance_S1 m3 : 56|7@1+ (1,0) [0|126] "" Vector__XXX
 SG_ Shelf_Multiplexor_S1 M : 0|2@1+ (1,0) [0|3] "" Vector__XXX
 SG_ Shelf_CellVoltageMinModule_S1 m1 : 16|3@1+ (1,0) [0|7] "" Vector__XXX
 SG_ Shelf_CellVoltageMinCell_S1 m1 : 19|5@1+ (1,0) [0|18] "" Vector__XXX
 SG_ Shelf_CellVoltageMin_S1 m1 : 2|13@1+ (0.000610426077402027,0) [0|5] "V" Vector__XXX
 SG_ Shelf_CellVoltageMaxModule_S1 m3 : 16|3@1+ (1,0) [0|7] "" Vector__XXX
 SG_ Shelf_CellVoltageMaxCell_S1 m3 : 19|5@1+ (1,0) [0|18] "" Vector__XXX
 SG_ Shelf_CellVoltageMax_S1 m3 : 2|13@1+ (0.000610426077402027,0) [0|5] "V" Vector__XXX
 SG_ Shelf_CellVoltageAvg_S1 m2 : 2|13@1+ (0.000610426077402027,0) [0|5] "V" Vector__XXX
 SG_ Shelf_CellTempMinModule_S1 m1 : 32|3@1+ (1,0) [0|7] "" Vector__XXX
 SG_ Shelf_CellTempMinSensor_S1 m1 : 35|3@1+ (1,0) [0|7] "" Vector__XXX
 SG_ Shelf_CellTempMin_S1 m1 : 24|8@1+ (0.5,-40) [-40|87.5] "degC" Vector__XXX
 SG_ Shelf_CellTempMaxModule_S1 m3 : 32|3@1+ (1,0) [0|7] "" Vector__XXX
 SG_ Shelf_CellTempMaxSensor_S1 m3 : 35|3@1+ (1,0) [0|7] "" Vector__XXX
 SG_ Shelf_CellTempMax_S1 m3 : 24|8@1+ (0.5,-40) [-40|87.5] "degC" Vector__XXX
 SG_ Shelf_CellTempAvg_S1 m2 : 24|8@1+ (0.5,-40) [-40|87.5] "degC" Vector__XXX

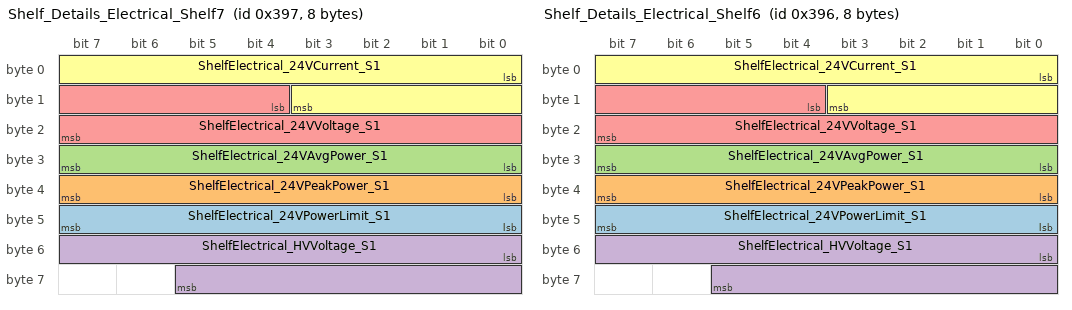
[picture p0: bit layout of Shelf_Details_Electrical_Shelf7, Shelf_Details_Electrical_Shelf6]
BO_ 919 Shelf_Details_Electrical_Shelf7: 8 Shelf7
 SG_ ShelfElectrical_24VPowerLimit_S1 : 40|8@1+ (0.25,0) [0|63.75] "W" Vector__XXX
 SG_ ShelfElectrical_24VPeakPower_S1 : 32|8@1+ (0.25,0) [0|63.75] "W" Vector__XXX
 SG_ ShelfElectrical_24VAvgPower_S1 : 24|8@1+ (0.25,0) [0|63.75] "W" Vector__XXX
 SG_ ShelfElectrical_HVVoltage_S1 : 48|14@1+ (0.02,0) [0|210] "V" Vector__XXX
 SG_ ShelfElectrical_24VVoltage_S1 : 12|12@1+ (0.00862,0) [0|36.3] "V" Vector__XXX
 SG_ ShelfElectrical_24VCurrent_S1 : 0|12@1+ (0.0008,0) [0|0] "A" Vector__XXX

BO_ 918 Shelf_Details_Electrical_Shelf6: 8 Shelf6
 SG_ ShelfElectrical_24VPowerLimit_S1 : 40|8@1+ (0.25,0) [0|63.75] "W" Vector__XXX
 SG_ ShelfElectrical_24VPeakPower_S1 : 32|8@1+ (0.25,0) [0|63.75] "W" Vector__XXX
 SG_ ShelfElectrical_24VAvgPower_S1 : 24|8@1+ (0.25,0) [0|63.75] "W" Vector__XXX
 SG_ ShelfElectrical_HVVoltage_S1 : 48|14@1+ (0.02,0) [0|210] "V" Vector__XXX
 SG_ ShelfElectrical_24VVoltage_S1 : 12|12@1+ (0.00862,0) [0|36.3] "V" Vector__XXX
 SG_ ShelfElectrical_24VCurrent_S1 : 0|12@1+ (0.0008,0) [0|0] "A" Vector__XXX

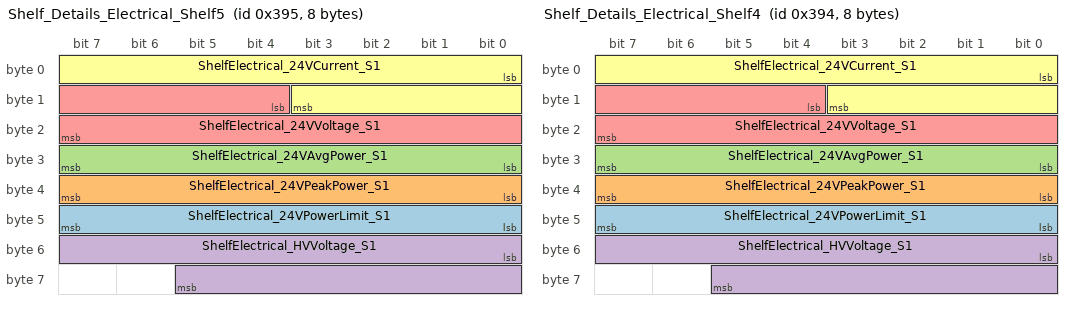
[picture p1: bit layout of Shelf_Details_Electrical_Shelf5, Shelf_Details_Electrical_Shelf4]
BO_ 917 Shelf_Details_Electrical_Shelf5: 8 Shelf5
 SG_ ShelfElectrical_24VPowerLimit_S1 : 40|8@1+ (0.25,0) [0|63.75] "W" Vector__XXX
 SG_ ShelfElectrical_24VPeakPower_S1 : 32|8@1+ (0.25,0) [0|63.75] "W" Vector__XXX
 SG_ ShelfElectrical_24VAvgPower_S1 : 24|8@1+ (0.25,0) [0|63.75] "W" Vector__XXX
 SG_ ShelfElectrical_HVVoltage_S1 : 48|14@1+ (0.02,0) [0|210] "V" Vector__XXX
 SG_ ShelfElectrical_24VVoltage_S1 : 12|12@1+ (0.00862,0) [0|36.3] "V" Vector__XXX
 SG_ ShelfElectrical_24VCurrent_S1 : 0|12@1+ (0.0008,0) [0|0] "A" Vector__XXX

BO_ 967 Module_Summary_Shelf7: 8 Shelf7
 SG_ Shelf_Hysteresis_S1 m5 : 24|8@1+ (0.000610426077402027,0) [0|0.155658649737517] "V" Vector__XXX
 SG_ Shelf_Threshold_S1 m5 : 8|14@1+ (0.000610426077402027,0) [0|10.0006104260774] "V" Vector__XXX
 SG_ ModuleVoltage_S1M5 m22 : 8|14@1+ (0.002,0) [0|32.766] "V" Vector__XXX
 SG_ ModuleVoltage_S1M4 m18 : 8|14@1+ (0.002,0) [0|32.766] "V" Vector__XXX
 SG_ ModuleVoltage_S1M3 m14 : 8|14@1+ (0.002,0) [0|32.766] "V" Vector__XXX
 SG_ ModuleVoltage_S1M2 m10 : 8|14@1+ (0.002,0) [0|32.766] "V" Vector__XXX
 SG_ ModuleVoltage_S1M1 m6 : 8|14@1+ (0.002,0) [0|32.766] "V" Vector__XXX
 SG_ ModuleVoltage_CellMinLoc_S1M5 m21 : 43|5@1+ (1,0) [0|18] "" Vector__XXX
 SG_ ModuleVoltage_CellMinLoc_S1M4 m17 : 43|5@1+ (1,0) [0|18] "" Vector__XXX
 SG_ ModuleVoltage_CellMinLoc_S1M3 m13 : 43|5@1+ (1,0) [0|18] "" Vector__XXX
 SG_ ModuleVoltage_CellMinLoc_S1M2 m9 : 43|5@1+ (1,0) [0|18] "" Vector__XXX
 SG_ ModuleVoltage_CellMinLoc_S1M1 m5 : 43|5@1+ (1,0) [0|18] "" Vector__XXX
 SG_ ModuleVoltage_CellMin_S1M5 m21 : 48|13@1+ (0.000610426077402027,0) [0|2] "V" Vector__XXX
 SG_ ModuleVoltage_CellMin_S1M4 m17 : 48|13@1+ (0.000610426077402027,0) [0|2] "V" Vector__XXX
 SG_ ModuleVoltage_CellMin_S1M3 m13 : 48|13@1+ (0.000610426077402027,0) [0|2] "V" Vector__XXX
 SG_ ModuleVoltage_CellMin_S1M2 m9 : 48|13@1+ (0.000610426077402027,0) [0|2] "V" Vector__XXX
 SG_ ModuleVoltage_CellMin_S1M1 m5 : 48|13@1+ (0.000610426077402027,0) [0|2] "V" Vector__XXX
 SG_ ModuleVoltage_CellMaxLoc_S1M5 m23 : 43|5@1+ (1,0) [0|18] "" Vector__XXX
 SG_ ModuleVoltage_CellMaxLoc_S1M4 m19 : 43|5@1+ (1,0) [0|18] "" Vector__XXX
 SG_ ModuleVoltage_CellMaxLoc_S1M3 m15 : 43|5@1+ (1,0) [0|18] "" Vector__XXX
 SG_ ModuleVoltage_CellMaxLoc_S1M2 m11 : 43|5@1+ (1,0) [0|18] "" Vector__XXX
 SG_ ModuleVoltage_CellMaxLoc_S1M1 m7 : 43|5@1+ (1,0) [0|18] "" Vector__XXX
 SG_ ModuleVoltage_CellMax_S1M5 m23 : 48|13@1+ (0.000610426077402027,0) [0|2] "V" Vector__XXX
 SG_ ModuleVoltage_CellMax_S1M4 m19 : 48|13@1+ (0.000610426077402027,0) [0|2] "V" Vector__XXX
 SG_ ModuleVoltage_CellMax_S1M3 m15 : 48|13@1+ (0.000610426077402027,0) [0|2] "V" Vector__XXX
 SG_ ModuleVoltage_CellMax_S1M2 m11 : 48|13@1+ (0.000610426077402027,0) [0|2] "V" Vector__XXX
 SG_ ModuleVoltage_CellMax_S1M1 m7 : 48|13@1+ (0.000610426077402027,0) [0|2] "V" Vector__XXX
 SG_ ModuleVoltage_CellAvg_S1M5 m22 : 48|13@1+ (0.000610426077402027,0) [0|2] "V" Vector__XXX
 SG_ ModuleVoltage_CellAvg_S1M4 m18 : 48|13@1+ (0.000610426077402027,0) [0|2] "V" Vector__XXX
 SG_ ModuleVoltage_CellAvg_S1M3 m14 : 48|13@1+ (0.000610426077402027,0) [0|2] "V" Vector__XXX
 SG_ ModuleVoltage_CellAvg_S1M2 m10 : 48|13@1+ (0.000610426077402027,0) [0|2] "V" Vector__XXX
 SG_ ModuleVoltage_CellAvg_S1M1 m6 : 48|13@1+ (0.000610426077402027,0) [0|2] "V" Vector__XXX
 SG_ ModuleTemp_PCB_S1M5 m22 : 24|8@1+ (0.5,-40) [-40|87.5] "degC" Vector__XXX
 SG_ ModuleTemp_PCB_S1M4 m18 : 24|8@1+ (0.5,-40) [-40|87.5] "degC" Vector__XXX
 SG_ ModuleTemp_PCB_S1M3 m14 : 24|8@1+ (0.5,-40) [-40|87.5] "degC" Vector__XXX
 SG_ ModuleTemp_PCB_S1M2 m10 : 24|8@1+ (0.5,-40) [-40|87.5] "degC" Vector__XXX
 SG_ ModuleTemp_PCB_S1M1 m6 : 24|8@1+ (0.5,-40) [-40|87.5] "degC" Vector__XXX
 SG_ ModuleTemp_CellMinLoc_S1M5 m21 : 40|3@1+ (1,0) [0|5] "" Vector__XXX
 SG_ ModuleTemp_CellMinLoc_S1M4 m17 : 40|3@1+ (1,0) [0|5] "" Vector__XXX
 SG_ ModuleTemp_CellMinLoc_S1M3 m13 : 40|3@1+ (1,0) [0|5] "" Vector__XXX
 SG_ ModuleTemp_CellMinLoc_S1M2 m9 : 40|3@1+ (1,0) [0|5] "" Vector__XXX
 SG_ ModuleTemp_CellMinLoc_S1M1 m5 : 40|3@1+ (1,0) [0|5] "" Vector__XXX
 SG_ ModuleTemp_CellMin_S1M5 m21 : 32|8@1+ (0.5,-40) [-40|87.5] "degC" Vector__XXX
 SG_ ModuleTemp_CellMin_S1M4 m17 : 32|8@1+ (0.5,-40) [-40|87.5] "degC" Vector__XXX
 SG_ ModuleTemp_CellMin_S1M3 m13 : 32|8@1+ (0.5,-40) [-40|87.5] "degC" Vector__XXX
 SG_ ModuleTemp_CellMin_S1M2 m9 : 32|8@1+ (0.5,-40) [-40|87.5] "degC" Vector__XXX
 SG_ ModuleTemp_CellMin_S1M1 m5 : 32|8@1+ (0.5,-40) [-40|87.5] "degC" Vector__XXX
 SG_ ModuleTemp_CellMaxLoc_S1M5 m23 : 40|3@1+ (1,0) [0|5] "" Vector__XXX
 SG_ ModuleTemp_CellMaxLoc_S1M4 m19 : 40|3@1+ (1,0) [0|5] "" Vector__XXX
 SG_ ModuleTemp_CellMaxLoc_S1M3 m15 : 40|3@1+ (1,0) [0|5] "" Vector__XXX
 SG_ ModuleTemp_CellMaxLoc_S1M2 m11 : 40|3@1+ (1,0) [0|5] "" Vector__XXX
 SG_ ModuleTemp_CellMaxLoc_S1M1 m7 : 40|3@1+ (1,0) [0|5] "" Vector__XXX
 SG_ ModuleTemp_CellMax_S1M5 m23 : 32|8@1+ (0.5,-40) [-40|87.5] "degC" Vector__XXX
 SG_ ModuleTemp_CellMax_S1M4 m19 : 32|8@1+ (0.5,-40) [-40|87.5] "degC" Vector__XXX
 SG_ ModuleTemp_CellMax_S1M3 m15 : 32|8@1+ (0.5,-40) [-40|87.5] "degC" Vector__XXX
 SG_ ModuleTemp_CellMax_S1M2 m11 : 32|8@1+ (0.5,-40) [-40|87.5] "degC" Vector__XXX
 SG_ ModuleTemp_CellMax_S1M1 m7 : 32|8@1+ (0.5,-40) [-40|87.5] "degC" Vector__XXX
 SG_ ModuleTemp_CellAvg_S1M5 m22 : 32|8@1+ (0.5,-40) [-40|87.5] "degC" Vector__XXX
 SG_ ModuleTemp_CellAvg_S1M4 m18 : 32|8@1+ (0.5,-40) [-40|87.5] "degC" Vector__XXX
 SG_ ModuleTemp_CellAvg_S1M3 m14 : 32|8@1+ (0.5,-40) [-40|87.5] "degC" Vector__XXX
 SG_ ModuleTemp_CellAvg_S1M2 m10 : 32|8@1+ (0.5,-40) [-40|87.5] "degC" Vector__XXX
 SG_ ModuleTemp_CellAvg_S1M1 m6 : 32|8@1+ (0.5,-40) [-40|87.5] "degC" Vector__XXX
 SG_ ModuleMultiplexor M : 0|5@1+ (1,0) [0|21] "" Vector__XXX

BO_ 966 Module_Summary_Shelf6: 8 Shelf6
 SG_ Shelf_Hysteresis_S1 m5 : 24|8@1+ (0.000610426077402027,0) [0|0.155658649737517] "V" Vector__XXX
 SG_ Shelf_Threshold_S1 m5 : 8|14@1+ (0.000610426077402027,0) [0|10.0006104260774] "V" Vector__XXX
 SG_ ModuleVoltage_S1M5 m22 : 8|14@1+ (0.002,0) [0|32.766] "V" Vector__XXX
 SG_ ModuleVoltage_S1M4 m18 : 8|14@1+ (0.002,0) [0|32.766] "V" Vector__XXX
 SG_ ModuleVoltage_S1M3 m14 : 8|14@1+ (0.002,0) [0|32.766] "V" Vector__XXX
 SG_ ModuleVoltage_S1M2 m10 : 8|14@1+ (0.002,0) [0|32.766] "V" Vector__XXX
 SG_ ModuleVoltage_S1M1 m6 : 8|14@1+ (0.002,0) [0|32.766] "V" Vector__XXX
 SG_ ModuleVoltage_CellMinLoc_S1M5 m21 : 43|5@1+ (1,0) [0|18] "" Vector__XXX
 SG_ ModuleVoltage_CellMinLoc_S1M4 m17 : 43|5@1+ (1,0) [0|18] "" Vector__XXX
 SG_ ModuleVoltage_CellMinLoc_S1M3 m13 : 43|5@1+ (1,0) [0|18] "" Vector__XXX
 SG_ ModuleVoltage_CellMinLoc_S1M2 m9 : 43|5@1+ (1,0) [0|18] "" Vector__XXX
 SG_ ModuleVoltage_CellMinLoc_S1M1 m5 : 43|5@1+ (1,0) [0|18] "" Vector__XXX
 SG_ ModuleVoltage_CellMin_S1M5 m21 : 48|13@1+ (0.000610426077402027,0) [0|2] "V" Vector__XXX
 SG_ ModuleVoltage_CellMin_S1M4 m17 : 48|13@1+ (0.000610426077402027,0) [0|2] "V" Vector__XXX
 SG_ ModuleVoltage_CellMin_S1M3 m13 : 48|13@1+ (0.000610426077402027,0) [0|2] "V" Vector__XXX
 SG_ ModuleVoltage_CellMin_S1M2 m9 : 48|13@1+ (0.000610426077402027,0) [0|2] "V" Vector__XXX
 SG_ ModuleVoltage_CellMin_S1M1 m5 : 48|13@1+ (0.000610426077402027,0) [0|2] "V" Vector__XXX
 SG_ ModuleVoltage_CellMaxLoc_S1M5 m23 : 43|5@1+ (1,0) [0|18] "" Vector__XXX
 SG_ ModuleVoltage_CellMaxLoc_S1M4 m19 : 43|5@1+ (1,0) [0|18] "" Vector__XXX
 SG_ ModuleVoltage_CellMaxLoc_S1M3 m15 : 43|5@1+ (1,0) [0|18] "" Vector__XXX
 SG_ ModuleVoltage_CellMaxLoc_S1M2 m11 : 43|5@1+ (1,0) [0|18] "" Vector__XXX
 SG_ ModuleVoltage_CellMaxLoc_S1M1 m7 : 43|5@1+ (1,0) [0|18] "" Vector__XXX
 SG_ ModuleVoltage_CellMax_S1M5 m23 : 48|13@1+ (0.000610426077402027,0) [0|2] "V" Vector__XXX
 SG_ ModuleVoltage_CellMax_S1M4 m19 : 48|13@1+ (0.000610426077402027,0) [0|2] "V" Vector__XXX
 SG_ ModuleVoltage_CellMax_S1M3 m15 : 48|13@1+ (0.000610426077402027,0) [0|2] "V" Vector__XXX
 SG_ ModuleVoltage_CellMax_S1M2 m11 : 48|13@1+ (0.000610426077402027,0) [0|2] "V" Vector__XXX
 SG_ ModuleVoltage_CellMax_S1M1 m7 : 48|13@1+ (0.000610426077402027,0) [0|2] "V" Vector__XXX
 SG_ ModuleVoltage_CellAvg_S1M5 m22 : 48|13@1+ (0.000610426077402027,0) [0|2] "V" Vector__XXX
 SG_ ModuleVoltage_CellAvg_S1M4 m18 : 48|13@1+ (0.000610426077402027,0) [0|2] "V" Vector__XXX
 SG_ ModuleVoltage_CellAvg_S1M3 m14 : 48|13@1+ (0.000610426077402027,0) [0|2] "V" Vector__XXX
 SG_ ModuleVoltage_CellAvg_S1M2 m10 : 48|13@1+ (0.000610426077402027,0) [0|2] "V" Vector__XXX
 SG_ ModuleVoltage_CellAvg_S1M1 m6 : 48|13@1+ (0.000610426077402027,0) [0|2] "V" Vector__XXX
 SG_ ModuleTemp_PCB_S1M5 m22 : 24|8@1+ (0.5,-40) [-40|87.5] "degC" Vector__XXX
 SG_ ModuleTemp_PCB_S1M4 m18 : 24|8@1+ (0.5,-40) [-40|87.5] "degC" Vector__XXX
 SG_ ModuleTemp_PCB_S1M3 m14 : 24|8@1+ (0.5,-40) [-40|87.5] "degC" Vector__XXX
 SG_ ModuleTemp_PCB_S1M2 m10 : 24|8@1+ (0.5,-40) [-40|87.5] "degC" Vector__XXX
 SG_ ModuleTemp_PCB_S1M1 m6 : 24|8@1+ (0.5,-40) [-40|87.5] "degC" Vector__XXX
 SG_ ModuleTemp_CellMinLoc_S1M5 m21 : 40|3@1+ (1,0) [0|5] "" Vector__XXX
 SG_ ModuleTemp_CellMinLoc_S1M4 m17 : 40|3@1+ (1,0) [0|5] "" Vector__XXX
 SG_ ModuleTemp_CellMinLoc_S1M3 m13 : 40|3@1+ (1,0) [0|5] "" Vector__XXX
 SG_ ModuleTemp_CellMinLoc_S1M2 m9 : 40|3@1+ (1,0) [0|5] "" Vector__XXX
 SG_ ModuleTemp_CellMinLoc_S1M1 m5 : 40|3@1+ (1,0) [0|5] "" Vector__XXX
 SG_ ModuleTemp_CellMin_S1M5 m21 : 32|8@1+ (0.5,-40) [-40|87.5] "degC" Vector__XXX
 SG_ ModuleTemp_CellMin_S1M4 m17 : 32|8@1+ (0.5,-40) [-40|87.5] "degC" Vector__XXX
 SG_ ModuleTemp_CellMin_S1M3 m13 : 32|8@1+ (0.5,-40) [-40|87.5] "degC" Vector__XXX
 SG_ ModuleTemp_CellMin_S1M2 m9 : 32|8@1+ (0.5,-40) [-40|87.5] "degC" Vector__XXX
 SG_ ModuleTemp_CellMin_S1M1 m5 : 32|8@1+ (0.5,-40) [-40|87.5] "degC" Vector__XXX
 SG_ ModuleTemp_CellMaxLoc_S1M5 m23 : 40|3@1+ (1,0) [0|5] "" Vector__XXX
 SG_ ModuleTemp_CellMaxLoc_S1M4 m19 : 40|3@1+ (1,0) [0|5] "" Vector__XXX
 SG_ ModuleTemp_CellMaxLoc_S1M3 m15 : 40|3@1+ (1,0) [0|5] "" Vector__XXX
 SG_ ModuleTemp_CellMaxLoc_S1M2 m11 : 40|3@1+ (1,0) [0|5] "" Vector__XXX
 SG_ ModuleTemp_CellMaxLoc_S1M1 m7 : 40|3@1+ (1,0) [0|5] "" Vector__XXX
 SG_ ModuleTemp_CellMax_S1M5 m23 : 32|8@1+ (0.5,-40) [-40|87.5] "degC" Vector__XXX
 SG_ ModuleTemp_CellMax_S1M4 m19 : 32|8@1+ (0.5,-40) [-40|87.5] "degC" Vector__XXX
 SG_ ModuleTemp_CellMax_S1M3 m15 : 32|8@1+ (0.5,-40) [-40|87.5] "degC" Vector__XXX
 SG_ ModuleTemp_CellMax_S1M2 m11 : 32|8@1+ (0.5,-40) [-40|87.5] "degC" Vector__XXX
 SG_ ModuleTemp_CellMax_S1M1 m7 : 32|8@1+ (0.5,-40) [-40|87.5] "degC" Vector__XXX
 SG_ ModuleTemp_CellAvg_S1M5 m22 : 32|8@1+ (0.5,-40) [-40|87.5] "degC" Vector__XXX
 SG_ ModuleTemp_CellAvg_S1M4 m18 : 32|8@1+ (0.5,-40) [-40|87.5] "degC" Vector__XXX
 SG_ ModuleTemp_CellAvg_S1M3 m14 : 32|8@1+ (0.5,-40) [-40|87.5] "degC" Vector__XXX
 SG_ ModuleTemp_CellAvg_S1M2 m10 : 32|8@1+ (0.5,-40) [-40|87.5] "degC" Vector__XXX
 SG_ ModuleTemp_CellAvg_S1M1 m6 : 32|8@1+ (0.5,-40) [-40|87.5] "degC" Vector__XXX
 SG_ ModuleMultiplexor M : 0|5@1+ (1,0) [0|21] "" Vector__XXX

BO_ 965 Module_Summary_Shelf5: 8 Shelf5
 SG_ Shelf_Hysteresis_S1 m5 : 24|8@1+ (0.000610426077402027,0) [0|0.155658649737517] "V" Vector__XXX
 SG_ Shelf_Threshold_S1 m5 : 8|14@1+ (0.000610426077402027,0) [0|10.0006104260774] "V" Vector__XXX
 SG_ ModuleVoltage_S1M5 m22 : 8|14@1+ (0.002,0) [0|32.766] "V" Vector__XXX
 SG_ ModuleVoltage_S1M4 m18 : 8|14@1+ (0.002,0) [0|32.766] "V" Vector__XXX
 SG_ ModuleVoltage_S1M3 m14 : 8|14@1+ (0.002,0) [0|32.766] "V" Vector__XXX
 SG_ ModuleVoltage_S1M2 m10 : 8|14@1+ (0.002,0) [0|32.766] "V" Vector__XXX
 SG_ ModuleVoltage_S1M1 m6 : 8|14@1+ (0.002,0) [0|32.766] "V" Vector__XXX
 SG_ ModuleVoltage_CellMinLoc_S1M5 m21 : 43|5@1+ (1,0) [0|18] "" Vector__XXX
 SG_ ModuleVoltage_CellMinLoc_S1M4 m17 : 43|5@1+ (1,0) [0|18] "" Vector__XXX
 SG_ ModuleVoltage_CellMinLoc_S1M3 m13 : 43|5@1+ (1,0) [0|18] "" Vector__XXX
 SG_ ModuleVoltage_CellMinLoc_S1M2 m9 : 43|5@1+ (1,0) [0|18] "" Vector__XXX
 SG_ ModuleVoltage_CellMinLoc_S1M1 m5 : 43|5@1+ (1,0) [0|18] "" Vector__XXX
 SG_ ModuleVoltage_CellMin_S1M5 m21 : 48|13@1+ (0.000610426077402027,0) [0|2] "V" Vector__XXX
 SG_ ModuleVoltage_CellMin_S1M4 m17 : 48|13@1+ (0.000610426077402027,0) [0|2] "V" Vector__XXX
 SG_ ModuleVoltage_CellMin_S1M3 m13 : 48|13@1+ (0.000610426077402027,0) [0|2] "V" Vector__XXX
 SG_ ModuleVoltage_CellMin_S1M2 m9 : 48|13@1+ (0.000610426077402027,0) [0|2] "V" Vector__XXX
 SG_ ModuleVoltage_CellMin_S1M1 m5 : 48|13@1+ (0.000610426077402027,0) [0|2] "V" Vector__XXX
 SG_ ModuleVoltage_CellMaxLoc_S1M5 m23 : 43|5@1+ (1,0) [0|18] "" Vector__XXX
 SG_ ModuleVoltage_CellMaxLoc_S1M4 m19 : 43|5@1+ (1,0) [0|18] "" Vector__XXX
 SG_ ModuleVoltage_CellMaxLoc_S1M3 m15 : 43|5@1+ (1,0) [0|18] "" Vector__XXX
 SG_ ModuleVoltage_CellMaxLoc_S1M2 m11 : 43|5@1+ (1,0) [0|18] "" Vector__XXX
 SG_ ModuleVoltage_CellMaxLoc_S1M1 m7 : 43|5@1+ (1,0) [0|18] "" Vector__XXX
 SG_ ModuleVoltage_CellMax_S1M5 m23 : 48|13@1+ (0.000610426077402027,0) [0|2] "V" Vector__XXX
 SG_ ModuleVoltage_CellMax_S1M4 m19 : 48|13@1+ (0.000610426077402027,0) [0|2] "V" Vector__XXX
 SG_ ModuleVoltage_CellMax_S1M3 m15 : 48|13@1+ (0.000610426077402027,0) [0|2] "V" Vector__XXX
 SG_ ModuleVoltage_CellMax_S1M2 m11 : 48|13@1+ (0.000610426077402027,0) [0|2] "V" Vector__XXX
 SG_ ModuleVoltage_CellMax_S1M1 m7 : 48|13@1+ (0.000610426077402027,0) [0|2] "V" Vector__XXX
 SG_ ModuleVoltage_CellAvg_S1M5 m22 : 48|13@1+ (0.000610426077402027,0) [0|2] "V" Vector__XXX
 SG_ ModuleVoltage_CellAvg_S1M4 m18 : 48|13@1+ (0.000610426077402027,0) [0|2] "V" Vector__XXX
 SG_ ModuleVoltage_CellAvg_S1M3 m14 : 48|13@1+ (0.000610426077402027,0) [0|2] "V" Vector__XXX
 SG_ ModuleVoltage_CellAvg_S1M2 m10 : 48|13@1+ (0.000610426077402027,0) [0|2] "V" Vector__XXX
 SG_ ModuleVoltage_CellAvg_S1M1 m6 : 48|13@1+ (0.000610426077402027,0) [0|2] "V" Vector__XXX
 SG_ ModuleTemp_PCB_S1M5 m22 : 24|8@1+ (0.5,-40) [-40|87.5] "degC" Vector__XXX
 SG_ ModuleTemp_PCB_S1M4 m18 : 24|8@1+ (0.5,-40) [-40|87.5] "degC" Vector__XXX
 SG_ ModuleTemp_PCB_S1M3 m14 : 24|8@1+ (0.5,-40) [-40|87.5] "degC" Vector__XXX
 SG_ ModuleTemp_PCB_S1M2 m10 : 24|8@1+ (0.5,-40) [-40|87.5] "degC" Vector__XXX
 SG_ ModuleTemp_PCB_S1M1 m6 : 24|8@1+ (0.5,-40) [-40|87.5] "degC" Vector__XXX
 SG_ ModuleTemp_CellMinLoc_S1M5 m21 : 40|3@1+ (1,0) [0|5] "" Vector__XXX
 SG_ ModuleTemp_CellMinLoc_S1M4 m17 : 40|3@1+ (1,0) [0|5] "" Vector__XXX
 SG_ ModuleTemp_CellMinLoc_S1M3 m13 : 40|3@1+ (1,0) [0|5] "" Vector__XXX
 SG_ ModuleTemp_CellMinLoc_S1M2 m9 : 40|3@1+ (1,0) [0|5] "" Vector__XXX
 SG_ ModuleTemp_CellMinLoc_S1M1 m5 : 40|3@1+ (1,0) [0|5] "" Vector__XXX
 SG_ ModuleTemp_CellMin_S1M5 m21 : 32|8@1+ (0.5,-40) [-40|87.5] "degC" Vector__XXX
 SG_ ModuleTemp_CellMin_S1M4 m17 : 32|8@1+ (0.5,-40) [-40|87.5] "degC" Vector__XXX
 SG_ ModuleTemp_CellMin_S1M3 m13 : 32|8@1+ (0.5,-40) [-40|87.5] "degC" Vector__XXX
 SG_ ModuleTemp_CellMin_S1M2 m9 : 32|8@1+ (0.5,-40) [-40|87.5] "degC" Vector__XXX
 SG_ ModuleTemp_CellMin_S1M1 m5 : 32|8@1+ (0.5,-40) [-40|87.5] "degC" Vector__XXX
 SG_ ModuleTemp_CellMaxLoc_S1M5 m23 : 40|3@1+ (1,0) [0|5] "" Vector__XXX
 SG_ ModuleTemp_CellMaxLoc_S1M4 m19 : 40|3@1+ (1,0) [0|5] "" Vector__XXX
 SG_ ModuleTemp_CellMaxLoc_S1M3 m15 : 40|3@1+ (1,0) [0|5] "" Vector__XXX
 SG_ ModuleTemp_CellMaxLoc_S1M2 m11 : 40|3@1+ (1,0) [0|5] "" Vector__XXX
 SG_ ModuleTemp_CellMaxLoc_S1M1 m7 : 40|3@1+ (1,0) [0|5] "" Vector__XXX
 SG_ ModuleTemp_CellMax_S1M5 m23 : 32|8@1+ (0.5,-40) [-40|87.5] "degC" Vector__XXX
 SG_ ModuleTemp_CellMax_S1M4 m19 : 32|8@1+ (0.5,-40) [-40|87.5] "degC" Vector__XXX
 SG_ ModuleTemp_CellMax_S1M3 m15 : 32|8@1+ (0.5,-40) [-40|87.5] "degC" Vector__XXX
 SG_ ModuleTemp_CellMax_S1M2 m11 : 32|8@1+ (0.5,-40) [-40|87.5] "degC" Vector__XXX
 SG_ ModuleTemp_CellMax_S1M1 m7 : 32|8@1+ (0.5,-40) [-40|87.5] "degC" Vector__XXX
 SG_ ModuleTemp_CellAvg_S1M5 m22 : 32|8@1+ (0.5,-40) [-40|87.5] "degC" Vector__XXX
 SG_ ModuleTemp_CellAvg_S1M4 m18 : 32|8@1+ (0.5,-40) [-40|87.5] "degC" Vector__XXX
 SG_ ModuleTemp_CellAvg_S1M3 m14 : 32|8@1+ (0.5,-40) [-40|87.5] "degC" Vector__XXX
 SG_ ModuleTemp_CellAvg_S1M2 m10 : 32|8@1+ (0.5,-40) [-40|87.5] "degC" Vector__XXX
 SG_ ModuleTemp_CellAvg_S1M1 m6 : 32|8@1+ (0.5,-40) [-40|87.5] "degC" Vector__XXX
 SG_ ModuleMultiplexor M : 0|5@1+ (1,0) [0|21] "" Vector__XXX

BO_ 327 Debug1_Shelf7: 6 Vector__XXX
 SG_ D_Shelf_num_ISL_resets m0 : 16|8@1+ (1,0) [0|0] "" Vector__XXX
 SG_ D_Shelf_MaxMinusMin m0 : 32|16@1+ (0.000610426077402027,0) [0|0] "" Vector__XXX
 SG_ D_Shelf_Thermal_Autobal_Bypass m0 : 13|1@1+ (1,0) [0|1] "" Vector__XXX
 SG_ D_Shelf_Acutal_OCV_Autobal m0 : 10|1@1+ (1,0) [0|1] "" Vector__XXX
 SG_ D_Shelf_Acutal_Charge_Autobal m0 : 12|1@1+ (1,0) [0|1] "" Vector__XXX
 SG_ D_Shelf_Acutal_Discharge_Autobal m0 : 11|1@1+ (1,0) [0|1] "" Vector__XXX
 SG_ D_Shelf_CMD_Charge_Autobal m0 : 9|1@1+ (1,0) [0|1] "" Vector__XXX
 SG_ D_Multiplexor M : 0|5@1+ (1,0) [0|0] "" Vector__XXX
 SG_ D_Shelf_CMD_Discharge_Autobal m0 : 8|1@1+ (1,0) [0|1] "" Vector__XXX

BO_ 326 Debug1_Shelf6: 6 Vector__XXX
 SG_ D_Shelf_num_ISL_resets m0 : 16|8@1+ (1,0) [0|0] "" Vector__XXX
 SG_ D_Shelf_MaxMinusMin m0 : 32|16@1+ (0.000610426077402027,0) [0|0] "" Vector__XXX
 SG_ D_Shelf_Thermal_Autobal_Bypass m0 : 13|1@1+ (1,0) [0|1] "" Vector__XXX
 SG_ D_Shelf_Acutal_OCV_Autobal m0 : 10|1@1+ (1,0) [0|1] "" Vector__XXX
 SG_ D_Shelf_Acutal_Charge_Autobal m0 : 12|1@1+ (1,0) [0|1] "" Vector__XXX
 SG_ D_Shelf_Acutal_Discharge_Autobal m0 : 11|1@1+ (1,0) [0|1] "" Vector__XXX
 SG_ D_Shelf_CMD_Charge_Autobal m0 : 9|1@1+ (1,0) [0|1] "" Vector__XXX
 SG_ D_Multiplexor M : 0|5@1+ (1,0) [0|0] "" Vector__XXX
 SG_ D_Shelf_CMD_Discharge_Autobal m0 : 8|1@1+ (1,0) [0|1] "" Vector__XXX

BO_ 325 Debug1_Shelf5: 6 Vector__XXX
 SG_ D_Shelf_num_ISL_resets m0 : 16|8@1+ (1,0) [0|0] "" Vector__XXX
 SG_ D_Shelf_MaxMinusMin m0 : 32|16@1+ (0.000610426077402027,0) [0|0] "" Vector__XXX
 SG_ D_Shelf_Thermal_Autobal_Bypass m0 : 13|1@1+ (1,0) [0|1] "" Vector__XXX
 SG_ D_Shelf_Acutal_OCV_Autobal m0 : 10|1@1+ (1,0) [0|1] "" Vector__XXX
 SG_ D_Shelf_Acutal_Charge_Autobal m0 : 12|1@1+ (1,0) [0|1] "" Vector__XXX
 SG_ D_Shelf_Acutal_Discharge_Autobal m0 : 11|1@1+ (1,0) [0|1] "" Vector__XXX
 SG_ D_Shelf_CMD_Charge_Autobal m0 : 9|1@1+ (1,0) [0|1] "" Vector__XXX
 SG_ D_Multiplexor M : 0|5@1+ (1,0) [0|0] "" Vector__XXX
 SG_ D_Shelf_CMD_Discharge_Autobal m0 : 8|1@1+ (1,0) [0|1] "" Vector__XXX

BO_ 1015 Cell_Details_Shelf7: 8 Shelf7
 SG_ CellFault_OverTemp_S1M5TE m29 : 7|1@1+ (1,0) [0|0] "" Vector__XXX
 SG_ CellFault_OverTemp_S1M5TD m28 : 7|1@1+ (1,0) [0|0] "" Vector__XXX
 SG_ CellFault_OverTemp_S1M5TC m27 : 7|1@1+ (1,0) [0|0] "" Vector__XXX
 SG_ CellFault_OverTemp_S1M5TB m26 : 7|1@1+ (1,0) [0|0] "" Vector__XXX
 SG_ CellFault_OverTemp_S1M5TA m25 : 7|1@1+ (1,0) [0|0] "" Vector__XXX
 SG_ CellFault_OverTemp_S1M4TE m23 : 7|1@1+ (1,0) [0|0] "" Vector__XXX
 SG_ CellFault_OverTemp_S1M4TD m22 : 7|1@1+ (1,0) [0|0] "" Vector__XXX
 SG_ CellFault_OverTemp_S1M4TC m21 : 7|1@1+ (1,0) [0|0] "" Vector__XXX
 SG_ CellFault_OverTemp_S1M4TB m20 : 7|1@1+ (1,0) [0|0] "" Vector__XXX
 SG_ CellFault_OverTemp_S1M4TA m19 : 7|1@1+ (1,0) [0|0] "" Vector__XXX
 SG_ CellFault_OverTemp_S1M3TE m17 : 7|1@1+ (1,0) [0|0] "" Vector__XXX
 SG_ CellFault_OverTemp_S1M3TD m16 : 7|1@1+ (1,0) [0|0] "" Vector__XXX
 SG_ CellFault_OverTemp_S1M3TC m15 : 7|1@1+ (1,0) [0|0] "" Vector__XXX
 SG_ CellFault_OverTemp_S1M3TB m14 : 7|1@1+ (1,0) [0|0] "" Vector__XXX
 SG_ CellFault_OverTemp_S1M3TA m13 : 7|1@1+ (1,0) [0|0] "" Vector__XXX
 SG_ CellFault_OverTemp_S1M2TE m11 : 7|1@1+ (1,0) [0|0] "" Vector__XXX
 SG_ CellFault_OverTemp_S1M2TD m10 : 7|1@1+ (1,0) [0|0] "" Vector__XXX
 SG_ CellFault_OverTemp_S1M2TC m9 : 7|1@1+ (1,0) [0|0] "" Vector__XXX
 SG_ CellFault_OverTemp_S1M2TB m8 : 7|1@1+ (1,0) [0|0] "" Vector__XXX
 SG_ CellFault_OverTemp_S1M2TA m7 : 7|1@1+ (1,0) [0|0] "" Vector__XXX
 SG_ CellFault_OverTemp_S1M1TE m6 : 7|1@1+ (1,0) [0|0] "" Vector__XXX
 SG_ CellFault_OverTemp_S1M1TD m5 : 7|1@1+ (1,0) [0|0] "" Vector__XXX
 SG_ CellFault_OverTemp_S1M1TC m4 : 7|1@1+ (1,0) [0|0] "" Vector__XXX
 SG_ CellFault_OverTemp_S1M1TB m2 : 7|1@1+ (1,0) [0|0] "" Vector__XXX
 SG_ CellFault_OverTemp_S1M1TA m1 : 7|1@1+ (1,0) [0|0] "" Vector__XXX
 SG_ CellFault_Wire_S1M5C18 m30 : 62|1@1+ (1,0) [0|0] "" Vector__XXX
 SG_ CellFault_Wire_S1M5C17 m30 : 46|1@1+ (1,0) [0|0] "" Vector__XXX
 SG_ CellFault_Wire_S1M5C16 m30 : 30|1@1+ (1,0) [0|0] "" Vector__XXX
 SG_ CellFault_Wire_S1M5C15 m29 : 62|1@1+ (1,0) [0|0] "" Vector__XXX
 SG_ CellFault_Wire_S1M5C14 m29 : 46|1@1+ (1,0) [0|0] "" Vector__XXX
 SG_ CellFault_Wire_S1M5C13 m29 : 30|1@1+ (1,0) [0|0] "" Vector__XXX
 SG_ CellFault_Wire_S1M5C12 m28 : 62|1@1+ (1,0) [0|0] "" Vector__XXX
 SG_ CellFault_Wire_S1M5C11 m28 : 46|1@1+ (1,0) [0|0] "" Vector__XXX
 SG_ CellFault_Wire_S1M5C10 m28 : 30|1@1+ (1,0) [0|0] "" Vector__XXX
 SG_ CellFault_Wire_S1M5C09 m27 : 62|1@1+ (1,0) [0|0] "" Vector__XXX
 SG_ CellFault_Wire_S1M5C08 m27 : 46|1@1+ (1,0) [0|0] "" Vector__XXX
 SG_ CellFault_Wire_S1M5C07 m27 : 30|1@1+ (1,0) [0|0] "" Vector__XXX
 SG_ CellFault_Wire_S1M5C06 m26 : 62|1@1+ (1,0) [0|0] "" Vector__XXX
 SG_ CellFault_Wire_S1M5C05 m26 : 46|1@1+ (1,0) [0|0] "" Vector__XXX
 SG_ CellFault_Wire_S1M5C04 m26 : 30|1@1+ (1,0) [0|0] "" Vector__XXX
 SG_ CellFault_Wire_S1M5C03 m25 : 62|1@1+ (1,0) [0|0] "" Vector__XXX
 SG_ CellFault_Wire_S1M5C02 m25 : 46|1@1+ (1,0) [0|0] "" Vector__XXX
 SG_ CellFault_Wire_S1M5C01 m25 : 30|1@1+ (1,0) [0|0] "" Vector__XXX
 SG_ CellFault_Wire_S1M4C18 m24 : 62|1@1+ (1,0) [0|0] "" Vector__XXX
 SG_ CellFault_Wire_S1M4C17 m24 : 46|1@1+ (1,0) [0|0] "" Vector__XXX
 SG_ CellFault_Wire_S1M4C16 m24 : 30|1@1+ (1,0) [0|0] "" Vector__XXX
 SG_ CellFault_Wire_S1M4C15 m23 : 62|1@1+ (1,0) [0|0] "" Vector__XXX
 SG_ CellFault_Wire_S1M4C14 m23 : 46|1@1+ (1,0) [0|0] "" Vector__XXX
 SG_ CellFault_Wire_S1M4C13 m23 : 30|1@1+ (1,0) [0|0] "" Vector__XXX
 SG_ CellFault_Wire_S1M4C12 m22 : 62|1@1+ (1,0) [0|0] "" Vector__XXX
 SG_ CellFault_Wire_S1M4C11 m22 : 46|1@1+ (1,0) [0|0] "" Vector__XXX
 SG_ CellFault_Wire_S1M4C10 m22 : 30|1@1+ (1,0) [0|0] "" Vector__XXX
 SG_ CellFault_Wire_S1M4C09 m21 : 62|1@1+ (1,0) [0|0] "" Vector__XXX
 SG_ CellFault_Wire_S1M4C08 m21 : 46|1@1+ (1,0) [0|0] "" Vector__XXX
 SG_ CellFault_Wire_S1M4C07 m21 : 30|1@1+ (1,0) [0|0] "" Vector__XXX
 SG_ CellFault_Wire_S1M4C06 m20 : 62|1@1+ (1,0) [0|0] "" Vector__XXX
 SG_ CellFault_Wire_S1M4C05 m20 : 46|1@1+ (1,0) [0|0] "" Vector__XXX
 SG_ CellFault_Wire_S1M4C04 m20 : 30|1@1+ (1,0) [0|0] "" Vector__XXX
 SG_ CellFault_Wire_S1M4C03 m19 : 62|1@1+ (1,0) [0|0] "" Vector__XXX
 SG_ CellFault_Wire_S1M4C02 m19 : 46|1@1+ (1,0) [0|0] "" Vector__XXX
 SG_ CellFault_Wire_S1M4C01 m19 : 30|1@1+ (1,0) [0|0] "" Vector__XXX
 SG_ CellFault_Wire_S1M3C18 m18 : 62|1@1+ (1,0) [0|0] "" Vector__XXX
 SG_ CellFault_Wire_S1M3C17 m18 : 46|1@1+ (1,0) [0|0] "" Vector__XXX
 SG_ CellFault_Wire_S1M3C16 m18 : 30|1@1+ (1,0) [0|0] "" Vector__XXX
 SG_ CellFault_Wire_S1M3C15 m17 : 62|1@1+ (1,0) [0|0] "" Vector__XXX
 SG_ CellFault_Wire_S1M3C14 m17 : 46|1@1+ (1,0) [0|0] "" Vector__XXX
 SG_ CellFault_Wire_S1M3C13 m17 : 30|1@1+ (1,0) [0|0] "" Vector__XXX
 SG_ CellFault_Wire_S1M3C12 m16 : 62|1@1+ (1,0) [0|0] "" Vector__XXX
 SG_ CellFault_Wire_S1M3C11 m16 : 46|1@1+ (1,0) [0|0] "" Vector__XXX
 SG_ CellFault_Wire_S1M3C10 m16 : 30|1@1+ (1,0) [0|0] "" Vector__XXX
 SG_ CellFault_Wire_S1M3C09 m15 : 62|1@1+ (1,0) [0|0] "" Vector__XXX
 SG_ CellFault_Wire_S1M3C08 m15 : 46|1@1+ (1,0) [0|0] "" Vector__XXX
 SG_ CellFault_Wire_S1M3C07 m15 : 30|1@1+ (1,0) [0|0] "" Vector__XXX
 SG_ CellFault_Wire_S1M3C06 m14 : 62|1@1+ (1,0) [0|0] "" Vector__XXX
 SG_ CellFault_Wire_S1M3C05 m14 : 46|1@1+ (1,0) [0|0] "" Vector__XXX
 SG_ CellFault_Wire_S1M3C04 m14 : 30|1@1+ (1,0) [0|0] "" Vector__XXX
 SG_ CellFault_Wire_S1M3C03 m13 : 62|1@1+ (1,0) [0|0] "" Vector__XXX
 SG_ CellFault_Wire_S1M3C02 m13 : 46|1@1+ (1,0) [0|0] "" Vector__XXX
 SG_ CellFault_Wire_S1M3C01 m13 : 30|1@1+ (1,0) [0|0] "" Vector__XXX
 SG_ CellFault_Wire_S1M2C18 m12 : 62|1@1+ (1,0) [0|0] "" Vector__XXX
 SG_ CellFault_Wire_S1M2C17 m12 : 46|1@1+ (1,0) [0|0] "" Vector__XXX
 SG_ CellFault_Wire_S1M2C16 m12 : 30|1@1+ (1,0) [0|0] "" Vector__XXX
 SG_ CellFault_Wire_S1M2C15 m11 : 62|1@1+ (1,0) [0|0] "" Vector__XXX
 SG_ CellFault_Wire_S1M2C14 m11 : 46|1@1+ (1,0) [0|0] "" Vector__XXX
 SG_ CellFault_Wire_S1M2C13 m11 : 30|1@1+ (1,0) [0|0] "" Vector__XXX
 SG_ CellFault_Wire_S1M2C12 m10 : 62|1@1+ (1,0) [0|0] "" Vector__XXX
 SG_ CellFault_Wire_S1M2C11 m10 : 46|1@1+ (1,0) [0|0] "" Vector__XXX
 SG_ CellFault_Wire_S1M2C10 m10 : 30|1@1+ (1,0) [0|0] "" Vector__XXX
 SG_ CellFault_Wire_S1M2C09 m9 : 62|1@1+ (1,0) [0|0] "" Vector__XXX
 SG_ CellFault_Wire_S1M2C08 m9 : 46|1@1+ (1,0) [0|0] "" Vector__XXX
 SG_ CellFault_Wire_S1M2C07 m9 : 30|1@1+ (1,0) [0|0] "" Vector__XXX
 SG_ CellFault_Wire_S1M2C06 m8 : 62|1@1+ (1,0) [0|0] "" Vector__XXX
 SG_ CellFault_Wire_S1M2C05 m8 : 46|1@1+ (1,0) [0|0] "" Vector__XXX
 SG_ CellFault_Wire_S1M2C04 m8 : 30|1@1+ (1,0) [0|0] "" Vector__XXX
 SG_ CellFault_Wire_S1M2C03 m7 : 62|1@1+ (1,0) [0|0] "" Vector__XXX
 SG_ CellFault_Wire_S1M2C02 m7 : 46|1@1+ (1,0) [0|0] "" Vector__XXX
 SG_ CellFault_Wire_S1M2C01 m7 : 30|1@1+ (1,0) [0|0] "" Vector__XXX
 SG_ CellFault_Wire_S1M1C18 m6 : 62|1@1+ (1,0) [0|0] "" Vector__XXX
 SG_ CellFault_Wire_S1M1C17 m6 : 46|1@1+ (1,0) [0|0] "" Vector__XXX
 SG_ CellFault_Wire_S1M1C16 m6 : 30|1@1+ (1,0) [0|0] "" Vector__XXX
 SG_ CellFault_Wire_S1M1C15 m5 : 62|1@1+ (1,0) [0|0] "" Vector__XXX
 SG_ CellFault_Wire_S1M1C14 m5 : 46|1@1+ (1,0) [0|0] "" Vector__XXX
 SG_ CellFault_Wire_S1M1C13 m5 : 30|1@1+ (1,0) [0|0] "" Vector__XXX
 SG_ CellFault_Wire_S1M1C12 m4 : 62|1@1+ (1,0) [0|0] "" Vector__XXX
 SG_ CellFault_Wire_S1M1C11 m4 : 46|1@1+ (1,0) [0|0] "" Vector__XXX
 SG_ CellFault_Wire_S1M1C10 m4 : 30|1@1+ (1,0) [0|0] "" Vector__XXX
 SG_ CellFault_Wire_S1M1C09 m3 : 62|1@1+ (1,0) [0|0] "" Vector__XXX
 SG_ CellFault_Wire_S1M1C08 m3 : 46|1@1+ (1,0) [0|0] "" Vector__XXX
 SG_ CellFault_Wire_S1M1C07 m3 : 30|1@1+ (1,0) [0|0] "" Vector__XXX
 SG_ CellFault_Wire_S1M1C06 m2 : 62|1@1+ (1,0) [0|0] "" Vector__XXX
 SG_ CellFault_Wire_S1M1C05 m2 : 46|1@1+ (1,0) [0|0] "" Vector__XXX
 SG_ CellFault_Wire_S1M1C04 m2 : 30|1@1+ (1,0) [0|0] "" Vector__XXX
 SG_ CellFault_Wire_S1M1C03 m1 : 62|1@1+ (1,0) [0|0] "" Vector__XXX
 SG_ CellFault_Wire_S1M1C02 m1 : 46|1@1+ (1,0) [0|0] "" Vector__XXX
 SG_ CellFault_Wire_S1M1C01 m1 : 30|1@1+ (1,0) [0|0] "" Vector__XXX
 SG_ CellFault_Voltage_S1M5C18 m30 : 63|1@1+ (1,0) [0|0] "" Vector__XXX
 SG_ CellFault_Voltage_S1M5C17 m30 : 47|1@1+ (1,0) [0|0] "" Vector__XXX
 SG_ CellFault_Voltage_S1M5C16 m30 : 31|1@1+ (1,0) [0|0] "" Vector__XXX
 SG_ CellFault_Voltage_S1M5C15 m29 : 63|1@1+ (1,0) [0|0] "" Vector__XXX
 SG_ CellFault_Voltage_S1M5C14 m29 : 47|1@1+ (1,0) [0|0] "" Vector__XXX
 SG_ CellFault_Voltage_S1M5C13 m29 : 31|1@1+ (1,0) [0|0] "" Vector__XXX
 SG_ CellFault_Voltage_S1M5C12 m28 : 63|1@1+ (1,0) [0|0] "" Vector__XXX
 SG_ CellFault_Voltage_S1M5C11 m28 : 47|1@1+ (1,0) [0|0] "" Vector__XXX
 SG_ CellFault_Voltage_S1M5C10 m28 : 31|1@1+ (1,0) [0|0] "" Vector__XXX
 SG_ CellFault_Voltage_S1M5C09 m27 : 63|1@1+ (1,0) [0|0] "" Vector__XXX
 SG_ CellFault_Voltage_S1M5C08 m27 : 47|1@1+ (1,0) [0|0] "" Vector__XXX
 SG_ CellFault_Voltage_S1M5C07 m27 : 31|1@1+ (1,0) [0|0] "" Vector__XXX
 SG_ CellFault_Voltage_S1M5C06 m26 : 63|1@1+ (1,0) [0|0] "" Vector__XXX
 SG_ CellFault_Voltage_S1M5C05 m26 : 47|1@1+ (1,0) [0|0] "" Vector__XXX
 SG_ CellFault_Voltage_S1M5C04 m26 : 31|1@1+ (1,0) [0|0] "" Vector__XXX
 SG_ CellFault_Voltage_S1M5C03 m25 : 63|1@1+ (1,0) [0|0] "" Vector__XXX
 SG_ CellFault_Voltage_S1M5C02 m25 : 47|1@1+ (1,0) [0|0] "" Vector__XXX
 SG_ CellFault_Voltage_S1M5C01 m25 : 31|1@1+ (1,0) [0|0] "" Vector__XXX
 SG_ CellFault_Voltage_S1M4C18 m24 : 63|1@1+ (1,0) [0|0] "" Vector__XXX
 SG_ CellFault_Voltage_S1M4C17 m24 : 47|1@1+ (1,0) [0|0] "" Vector__XXX
 SG_ CellFault_Voltage_S1M4C16 m24 : 31|1@1+ (1,0) [0|0] "" Vector__XXX
 SG_ CellFault_Voltage_S1M4C15 m23 : 63|1@1+ (1,0) [0|0] "" Vector__XXX
 SG_ CellFault_Voltage_S1M4C14 m23 : 47|1@1+ (1,0) [0|0] "" Vector__XXX
 SG_ CellFault_Voltage_S1M4C13 m23 : 31|1@1+ (1,0) [0|0] "" Vector__XXX
 SG_ CellFault_Voltage_S1M4C12 m22 : 63|1@1+ (1,0) [0|0] "" Vector__XXX
 SG_ CellFault_Voltage_S1M4C11 m22 : 47|1@1+ (1,0) [0|0] "" Vector__XXX
 SG_ CellFault_Voltage_S1M4C10 m22 : 31|1@1+ (1,0) [0|0] "" Vector__XXX
 SG_ CellFault_Voltage_S1M4C09 m21 : 63|1@1+ (1,0) [0|0] "" Vector__XXX
 SG_ CellFault_Voltage_S1M4C08 m21 : 47|1@1+ (1,0) [0|0] "" Vector__XXX
 SG_ CellFault_Voltage_S1M4C07 m21 : 31|1@1+ (1,0) [0|0] "" Vector__XXX
 SG_ CellFault_Voltage_S1M4C06 m20 : 63|1@1+ (1,0) [0|0] "" Vector__XXX
 SG_ CellFault_Voltage_S1M4C05 m20 : 47|1@1+ (1,0) [0|0] "" Vector__XXX
 SG_ CellFault_Voltage_S1M4C04 m20 : 31|1@1+ (1,0) [0|0] "" Vector__XXX
 SG_ CellFault_Voltage_S1M4C03 m19 : 63|1@1+ (1,0) [0|0] "" Vector__XXX
 SG_ CellFault_Voltage_S1M4C02 m19 : 47|1@1+ (1,0) [0|0] "" Vector__XXX
 SG_ CellFault_Voltage_S1M4C01 m19 : 31|1@1+ (1,0) [0|0] "" Vector__XXX
 SG_ CellFault_Voltage_S1M3C18 m18 : 63|1@1+ (1,0) [0|0] "" Vector__XXX
 SG_ CellFault_Voltage_S1M3C17 m18 : 47|1@1+ (1,0) [0|0] "" Vector__XXX
 SG_ CellFault_Voltage_S1M3C16 m18 : 31|1@1+ (1,0) [0|0] "" Vector__XXX
 SG_ CellFault_Voltage_S1M3C15 m17 : 63|1@1+ (1,0) [0|0] "" Vector__XXX
 SG_ CellFault_Voltage_S1M3C14 m17 : 47|1@1+ (1,0) [0|0] "" Vector__XXX
 SG_ CellFault_Voltage_S1M3C13 m17 : 31|1@1+ (1,0) [0|0] "" Vector__XXX
 SG_ CellFault_Voltage_S1M3C12 m16 : 63|1@1+ (1,0) [0|0] "" Vector__XXX
 SG_ CellFault_Voltage_S1M3C11 m16 : 47|1@1+ (1,0) [0|0] "" Vector__XXX
 SG_ CellFault_Voltage_S1M3C10 m16 : 31|1@1+ (1,0) [0|0] "" Vector__XXX
 SG_ CellFault_Voltage_S1M3C09 m15 : 63|1@1+ (1,0) [0|0] "" Vector__XXX
 SG_ CellFault_Voltage_S1M3C08 m15 : 47|1@1+ (1,0) [0|0] "" Vector__XXX
 SG_ CellFault_Voltage_S1M3C07 m15 : 31|1@1+ (1,0) [0|0] "" Vector__XXX
 SG_ CellFault_Voltage_S1M3C06 m14 : 63|1@1+ (1,0) [0|0] "" Vector__XXX
 SG_ CellFault_Voltage_S1M3C05 m14 : 47|1@1+ (1,0) [0|0] "" Vector__XXX
 SG_ CellFault_Voltage_S1M3C04 m14 : 31|1@1+ (1,0) [0|0] "" Vector__XXX
 SG_ CellFault_Voltage_S1M3C03 m13 : 63|1@1+ (1,0) [0|0] "" Vector__XXX
 SG_ CellFault_Voltage_S1M3C02 m13 : 47|1@1+ (1,0) [0|0] "" Vector__XXX
 SG_ CellFault_Voltage_S1M3C01 m13 : 31|1@1+ (1,0) [0|0] "" Vector__XXX
 SG_ CellFault_Voltage_S1M2C18 m12 : 63|1@1+ (1,0) [0|0] "" Vector__XXX
 SG_ CellFault_Voltage_S1M2C17 m12 : 47|1@1+ (1,0) [0|0] "" Vector__XXX
 SG_ CellFault_Voltage_S1M2C16 m12 : 31|1@1+ (1,0) [0|0] "" Vector__XXX
 SG_ CellFault_Voltage_S1M2C15 m11 : 63|1@1+ (1,0) [0|0] "" Vector__XXX
 SG_ CellFault_Voltage_S1M2C14 m11 : 47|1@1+ (1,0) [0|0] "" Vector__XXX
 SG_ CellFault_Voltage_S1M2C13 m11 : 31|1@1+ (1,0) [0|0] "" Vector__XXX
 SG_ CellFault_Voltage_S1M2C12 m10 : 63|1@1+ (1,0) [0|0] "" Vector__XXX
 SG_ CellFault_Voltage_S1M2C11 m10 : 47|1@1+ (1,0) [0|0] "" Vector__XXX
 SG_ CellFault_Voltage_S1M2C10 m10 : 31|1@1+ (1,0) [0|0] "" Vector__XXX
 SG_ CellFault_Voltage_S1M2C09 m9 : 63|1@1+ (1,0) [0|0] "" Vector__XXX
 SG_ CellFault_Voltage_S1M2C08 m9 : 47|1@1+ (1,0) [0|0] "" Vector__XXX
 SG_ CellFault_Voltage_S1M2C07 m9 : 31|1@1+ (1,0) [0|0] "" Vector__XXX
 SG_ CellFault_Voltage_S1M2C06 m8 : 63|1@1+ (1,0) [0|0] "" Vector__XXX
 SG_ CellFault_Voltage_S1M2C05 m8 : 47|1@1+ (1,0) [0|0] "" Vector__XXX
 SG_ CellFault_Voltage_S1M2C04 m8 : 31|1@1+ (1,0) [0|0] "" Vector__XXX
 SG_ CellFault_Voltage_S1M2C03 m7 : 63|1@1+ (1,0) [0|0] "" Vector__XXX
 SG_ CellFault_Voltage_S1M2C02 m7 : 47|1@1+ (1,0) [0|0] "" Vector__XXX
 SG_ CellFault_Voltage_S1M2C01 m7 : 31|1@1+ (1,0) [0|0] "" Vector__XXX
 SG_ CellFault_Voltage_S1M1C18 m6 : 63|1@1+ (1,0) [0|0] "" Vector__XXX
 SG_ CellFault_Voltage_S1M1C17 m6 : 47|1@1+ (1,0) [0|0] "" Vector__XXX
 SG_ CellFault_Voltage_S1M1C16 m6 : 31|1@1+ (1,0) [0|0] "" Vector__XXX
 SG_ CellFault_Voltage_S1M1C15 m5 : 63|1@1+ (1,0) [0|0] "" Vector__XXX
 SG_ CellFault_Voltage_S1M1C14 m5 : 47|1@1+ (1,0) [0|0] "" Vector__XXX
 SG_ CellFault_Voltage_S1M1C13 m5 : 31|1@1+ (1,0) [0|0] "" Vector__XXX
 SG_ CellFault_Voltage_S1M1C12 m4 : 63|1@1+ (1,0) [0|0] "" Vector__XXX
 SG_ CellFault_Voltage_S1M1C11 m4 : 47|1@1+ (1,0) [0|0] "" Vector__XXX
 SG_ CellFault_Voltage_S1M1C10 m4 : 31|1@1+ (1,0) [0|0] "" Vector__XXX
 SG_ CellFault_Voltage_S1M1C09 m3 : 63|1@1+ (1,0) [0|0] "" Vector__XXX
 SG_ CellFault_Voltage_S1M1C08 m3 : 47|1@1+ (1,0) [0|0] "" Vector__XXX
 SG_ CellFault_Voltage_S1M1C07 m3 : 31|1@1+ (1,0) [0|0] "" Vector__XXX
 SG_ CellFault_Voltage_S1M1C06 m2 : 63|1@1+ (1,0) [0|0] "" Vector__XXX
 SG_ CellFault_Voltage_S1M1C05 m2 : 47|1@1+ (1,0) [0|0] "" Vector__XXX
 SG_ CellFault_Voltage_S1M1C04 m2 : 31|1@1+ (1,0) [0|0] "" Vector__XXX
 SG_ CellFault_Voltage_S1M1C03 m1 : 63|1@1+ (1,0) [0|0] "" Vector__XXX
 SG_ CellFault_Voltage_S1M1C02 m1 : 47|1@1+ (1,0) [0|0] "" Vector__XXX
 SG_ CellFault_Voltage_S1M1C01 m1 : 31|1@1+ (1,0) [0|0] "" Vector__XXX
 SG_ CellBalanceFET_S1M5C18 m30 : 61|1@1+ (1,0) [0|0] "" Vector__XXX
 SG_ CellBalanceFET_S1M5C17 m30 : 45|1@1+ (1,0) [0|0] "" Vector__XXX
 SG_ CellBalanceFET_S1M5C16 m30 : 29|1@1+ (1,0) [0|0] "" Vector__XXX
 SG_ CellBalanceFET_S1M5C15 m29 : 61|1@1+ (1,0) [0|0] "" Vector__XXX
 SG_ CellBalanceFET_S1M5C14 m29 : 45|1@1+ (1,0) [0|0] "" Vector__XXX
 SG_ CellBalanceFET_S1M5C13 m29 : 29|1@1+ (1,0) [0|0] "" Vector__XXX
 SG_ CellBalanceFET_S1M5C12 m28 : 61|1@1+ (1,0) [0|0] "" Vector__XXX
 SG_ CellBalanceFET_S1M5C11 m28 : 45|1@1+ (1,0) [0|0] "" Vector__XXX
 SG_ CellBalanceFET_S1M5C10 m28 : 29|1@1+ (1,0) [0|0] "" Vector__XXX
 SG_ CellBalanceFET_S1M5C09 m27 : 61|1@1+ (1,0) [0|0] "" Vector__XXX
 SG_ CellBalanceFET_S1M5C08 m27 : 45|1@1+ (1,0) [0|0] "" Vector__XXX
 SG_ CellBalanceFET_S1M5C07 m27 : 29|1@1+ (1,0) [0|0] "" Vector__XXX
 SG_ CellBalanceFET_S1M5C06 m26 : 61|1@1+ (1,0) [0|0] "" Vector__XXX
 SG_ CellBalanceFET_S1M5C05 m26 : 45|1@1+ (1,0) [0|0] "" Vector__XXX
 SG_ CellBalanceFET_S1M5C04 m26 : 29|1@1+ (1,0) [0|0] "" Vector__XXX
 SG_ CellBalanceFET_S1M5C03 m25 : 61|1@1+ (1,0) [0|0] "" Vector__XXX
 SG_ CellBalanceFET_S1M5C02 m25 : 45|1@1+ (1,0) [0|0] "" Vector__XXX
 SG_ CellBalanceFET_S1M5C01 m25 : 29|1@1+ (1,0) [0|0] "" Vector__XXX
 SG_ CellBalanceFET_S1M4C18 m24 : 61|1@1+ (1,0) [0|0] "" Vector__XXX
 SG_ CellBalanceFET_S1M4C17 m24 : 45|1@1+ (1,0) [0|0] "" Vector__XXX
 SG_ CellBalanceFET_S1M4C16 m24 : 29|1@1+ (1,0) [0|0] "" Vector__XXX
 SG_ CellBalanceFET_S1M4C15 m23 : 61|1@1+ (1,0) [0|0] "" Vector__XXX
 SG_ CellBalanceFET_S1M4C14 m23 : 45|1@1+ (1,0) [0|0] "" Vector__XXX
 SG_ CellBalanceFET_S1M4C13 m23 : 29|1@1+ (1,0) [0|0] "" Vector__XXX
 SG_ CellBalanceFET_S1M4C12 m22 : 61|1@1+ (1,0) [0|0] "" Vector__XXX
 SG_ CellBalanceFET_S1M4C11 m22 : 45|1@1+ (1,0) [0|0] "" Vector__XXX
 SG_ CellBalanceFET_S1M4C10 m22 : 29|1@1+ (1,0) [0|0] "" Vector__XXX
 SG_ CellBalanceFET_S1M4C09 m21 : 61|1@1+ (1,0) [0|0] "" Vector__XXX
 SG_ CellBalanceFET_S1M4C08 m21 : 45|1@1+ (1,0) [0|0] "" Vector__XXX
 SG_ CellBalanceFET_S1M4C07 m21 : 29|1@1+ (1,0) [0|0] "" Vector__XXX
 SG_ CellBalanceFET_S1M4C06 m20 : 61|1@1+ (1,0) [0|0] "" Vector__XXX
 SG_ CellBalanceFET_S1M4C05 m20 : 45|1@1+ (1,0) [0|0] "" Vector__XXX
 SG_ CellBalanceFET_S1M4C04 m20 : 29|1@1+ (1,0) [0|0] "" Vector__XXX
 SG_ CellBalanceFET_S1M4C03 m19 : 61|1@1+ (1,0) [0|0] "" Vector__XXX
 SG_ CellBalanceFET_S1M4C02 m19 : 45|1@1+ (1,0) [0|0] "" Vector__XXX
 SG_ CellBalanceFET_S1M4C01 m19 : 29|1@1+ (1,0) [0|0] "" Vector__XXX
 SG_ CellBalanceFET_S1M3C18 m18 : 61|1@1+ (1,0) [0|0] "" Vector__XXX
 SG_ CellBalanceFET_S1M3C17 m18 : 45|1@1+ (1,0) [0|0] "" Vector__XXX
 SG_ CellBalanceFET_S1M3C16 m18 : 29|1@1+ (1,0) [0|0] "" Vector__XXX
 SG_ CellBalanceFET_S1M3C15 m17 : 61|1@1+ (1,0) [0|0] "" Vector__XXX
 SG_ CellBalanceFET_S1M3C14 m17 : 45|1@1+ (1,0) [0|0] "" Vector__XXX
 SG_ CellBalanceFET_S1M3C13 m17 : 29|1@1+ (1,0) [0|0] "" Vector__XXX
 SG_ CellBalanceFET_S1M3C12 m16 : 61|1@1+ (1,0) [0|0] "" Vector__XXX
 SG_ CellBalanceFET_S1M3C11 m16 : 45|1@1+ (1,0) [0|0] "" Vector__XXX
 SG_ CellBalanceFET_S1M3C10 m16 : 29|1@1+ (1,0) [0|0] "" Vector__XXX
 SG_ CellBalanceFET_S1M3C09 m15 : 61|1@1+ (1,0) [0|0] "" Vector__XXX
 SG_ CellBalanceFET_S1M3C08 m15 : 45|1@1+ (1,0) [0|0] "" Vector__XXX
 SG_ CellBalanceFET_S1M3C07 m15 : 29|1@1+ (1,0) [0|0] "" Vector__XXX
 SG_ CellBalanceFET_S1M3C06 m14 : 61|1@1+ (1,0) [0|0] "" Vector__XXX
 SG_ CellBalanceFET_S1M3C05 m14 : 45|1@1+ (1,0) [0|0] "" Vector__XXX
 SG_ CellBalanceFET_S1M3C04 m14 : 29|1@1+ (1,0) [0|0] "" Vector__XXX
 SG_ CellBalanceFET_S1M3C03 m13 : 61|1@1+ (1,0) [0|0] "" Vector__XXX
 SG_ CellBalanceFET_S1M3C02 m13 : 45|1@1+ (1,0) [0|0] "" Vector__XXX
 SG_ CellBalanceFET_S1M3C01 m13 : 29|1@1+ (1,0) [0|0] "" Vector__XXX
 SG_ CellBalanceFET_S1M2C18 m12 : 61|1@1+ (1,0) [0|0] "" Vector__XXX
 SG_ CellBalanceFET_S1M2C17 m12 : 45|1@1+ (1,0) [0|0] "" Vector__XXX
 SG_ CellBalanceFET_S1M2C16 m12 : 29|1@1+ (1,0) [0|0] "" Vector__XXX
 SG_ CellBalanceFET_S1M2C15 m11 : 61|1@1+ (1,0) [0|0] "" Vector__XXX
 SG_ CellBalanceFET_S1M2C14 m11 : 45|1@1+ (1,0) [0|0] "" Vector__XXX
 SG_ CellBalanceFET_S1M2C13 m11 : 29|1@1+ (1,0) [0|0] "" Vector__XXX
 SG_ CellBalanceFET_S1M2C12 m10 : 61|1@1+ (1,0) [0|0] "" Vector__XXX
 SG_ CellBalanceFET_S1M2C11 m10 : 45|1@1+ (1,0) [0|0] "" Vector__XXX
 SG_ CellBalanceFET_S1M2C10 m10 : 29|1@1+ (1,0) [0|0] "" Vector__XXX
 SG_ CellBalanceFET_S1M2C09 m9 : 61|1@1+ (1,0) [0|0] "" Vector__XXX
 SG_ CellBalanceFET_S1M2C08 m9 : 45|1@1+ (1,0) [0|0] "" Vector__XXX
 SG_ CellBalanceFET_S1M2C07 m9 : 29|1@1+ (1,0) [0|0] "" Vector__XXX
 SG_ CellBalanceFET_S1M2C06 m8 : 61|1@1+ (1,0) [0|0] "" Vector__XXX
 SG_ CellBalanceFET_S1M2C05 m8 : 45|1@1+ (1,0) [0|0] "" Vector__XXX
 SG_ CellBalanceFET_S1M2C04 m8 : 29|1@1+ (1,0) [0|0] "" Vector__XXX
 SG_ CellBalanceFET_S1M2C03 m7 : 61|1@1+ (1,0) [0|0] "" Vector__XXX
 SG_ CellBalanceFET_S1M2C02 m7 : 45|1@1+ (1,0) [0|0] "" Vector__XXX
 SG_ CellBalanceFET_S1M2C01 m7 : 29|1@1+ (1,0) [0|0] "" Vector__XXX
 SG_ CellBalanceFET_S1M1C18 m6 : 61|1@1+ (1,0) [0|0] "" Vector__XXX
 SG_ CellBalanceFET_S1M1C17 m6 : 45|1@1+ (1,0) [0|0] "" Vector__XXX
 SG_ CellBalanceFET_S1M1C16 m6 : 29|1@1+ (1,0) [0|0] "" Vector__XXX
 SG_ CellBalanceFET_S1M1C15 m5 : 61|1@1+ (1,0) [0|0] "" Vector__XXX
 SG_ CellBalanceFET_S1M1C14 m5 : 45|1@1+ (1,0) [0|0] "" Vector__XXX
 SG_ CellBalanceFET_S1M1C13 m5 : 29|1@1+ (1,0) [0|0] "" Vector__XXX
 SG_ CellBalanceFET_S1M1C12 m4 : 61|1@1+ (1,0) [0|0] "" Vector__XXX
 SG_ CellBalanceFET_S1M1C11 m4 : 45|1@1+ (1,0) [0|0] "" Vector__XXX
 SG_ CellBalanceFET_S1M1C10 m4 : 29|1@1+ (1,0) [0|0] "" Vector__XXX
 SG_ CellBalanceFET_S1M1C09 m3 : 61|1@1+ (1,0) [0|0] "" Vector__XXX
 SG_ CellBalanceFET_S1M1C08 m3 : 45|1@1+ (1,0) [0|0] "" Vector__XXX
 SG_ CellBalanceFET_S1M1C07 m3 : 29|1@1+ (1,0) [0|0] "" Vector__XXX
 SG_ CellBalanceFET_S1M1C06 m2 : 61|1@1+ (1,0) [0|0] "" Vector__XXX
 SG_ CellBalanceFET_S1M1C05 m2 : 45|1@1+ (1,0) [0|0] "" Vector__XXX
 SG_ CellBalanceFET_S1M1C04 m2 : 29|1@1+ (1,0) [0|0] "" Vector__XXX
 SG_ CellBalanceFET_S1M1C03 m1 : 61|1@1+ (1,0) [0|0] "" Vector__XXX
 SG_ CellBalanceFET_S1M1C02 m1 : 45|1@1+ (1,0) [0|0] "" Vector__XXX
 SG_ CellBalanceFET_S1M1C01 m1 : 29|1@1+ (1,0) [0|0] "" Vector__XXX
 SG_ CellVoltage_S1M5C18 m30 : 48|13@1+ (0.000610426077402027,0) [0|2] "V" Vector__XXX
 SG_ CellVoltage_S1M5C17 m30 : 32|13@1+ (0.000610426077402027,0) [0|2] "V" Vector__XXX
 SG_ CellVoltage_S1M5C16 m30 : 16|13@1+ (0.000610426077402027,0) [0|2] "V" Vector__XXX
 SG_ CellVoltage_S1M5C15 m29 : 48|13@1+ (0.000610426077402027,0) [0|2] "V" Vector__XXX
 SG_ CellVoltage_S1M5C14 m29 : 32|13@1+ (0.000610426077402027,0) [0|2] "V" Vector__XXX
 SG_ CellVoltage_S1M5C13 m29 : 16|13@1+ (0.000610426077402027,0) [0|2] "V" Vector__XXX
 SG_ CellVoltage_S1M5C12 m28 : 48|13@1+ (0.000610426077402027,0) [0|2] "V" Vector__XXX
 SG_ CellVoltage_S1M5C11 m28 : 32|13@1+ (0.000610426077402027,0) [0|2] "V" Vector__XXX
 SG_ CellVoltage_S1M5C10 m28 : 16|13@1+ (0.000610426077402027,0) [0|2] "V" Vector__XXX
 SG_ CellVoltage_S1M5C09 m27 : 48|13@1+ (0.000610426077402027,0) [0|2] "V" Vector__XXX
 SG_ CellVoltage_S1M5C08 m27 : 32|13@1+ (0.000610426077402027,0) [0|2] "V" Vector__XXX
 SG_ CellVoltage_S1M5C07 m27 : 16|13@1+ (0.000610426077402027,0) [0|2] "V" Vector__XXX
 SG_ CellVoltage_S1M5C06 m26 : 48|13@1+ (0.000610426077402027,0) [0|2] "V" Vector__XXX
 SG_ CellVoltage_S1M5C05 m26 : 32|13@1+ (0.000610426077402027,0) [0|2] "V" Vector__XXX
 SG_ CellVoltage_S1M5C04 m26 : 16|13@1+ (0.000610426077402027,0) [0|2] "V" Vector__XXX
 SG_ CellVoltage_S1M5C03 m25 : 48|13@1+ (0.000610426077402027,0) [0|2] "V" Vector__XXX
 SG_ CellVoltage_S1M5C02 m25 : 32|13@1+ (0.000610426077402027,0) [0|2] "V" Vector__XXX
 SG_ CellVoltage_S1M5C01 m25 : 16|13@1+ (0.000610426077402027,0) [0|2] "V" Vector__XXX
 SG_ CellVoltage_S1M4C18 m24 : 48|13@1+ (0.000610426077402027,0) [0|2] "V" Vector__XXX
 SG_ CellVoltage_S1M4C17 m24 : 32|13@1+ (0.000610426077402027,0) [0|2] "V" Vector__XXX
 SG_ CellVoltage_S1M4C16 m24 : 16|13@1+ (0.000610426077402027,0) [0|2] "V" Vector__XXX
 SG_ CellVoltage_S1M4C15 m23 : 48|13@1+ (0.000610426077402027,0) [0|2] "V" Vector__XXX
 SG_ CellVoltage_S1M4C14 m23 : 32|13@1+ (0.000610426077402027,0) [0|2] "V" Vector__XXX
 SG_ CellVoltage_S1M4C13 m23 : 16|13@1+ (0.000610426077402027,0) [0|2] "V" Vector__XXX
 SG_ CellVoltage_S1M4C12 m22 : 48|13@1+ (0.000610426077402027,0) [0|2] "V" Vector__XXX
 SG_ CellVoltage_S1M4C11 m22 : 32|13@1+ (0.000610426077402027,0) [0|2] "V" Vector__XXX
 SG_ CellVoltage_S1M4C10 m22 : 16|13@1+ (0.000610426077402027,0) [0|2] "V" Vector__XXX
 SG_ CellVoltage_S1M4C09 m21 : 48|13@1+ (0.000610426077402027,0) [0|2] "V" Vector__XXX
 SG_ CellVoltage_S1M4C08 m21 : 32|13@1+ (0.000610426077402027,0) [0|2] "V" Vector__XXX
 SG_ CellVoltage_S1M4C07 m21 : 16|13@1+ (0.000610426077402027,0) [0|2] "V" Vector__XXX
 SG_ CellVoltage_S1M4C06 m20 : 48|13@1+ (0.000610426077402027,0) [0|2] "V" Vector__XXX
 SG_ CellVoltage_S1M4C05 m20 : 32|13@1+ (0.000610426077402027,0) [0|2] "V" Vector__XXX
 SG_ CellVoltage_S1M4C04 m20 : 16|13@1+ (0.000610426077402027,0) [0|2] "V" Vector__XXX
 SG_ CellVoltage_S1M4C03 m19 : 48|13@1+ (0.000610426077402027,0) [0|2] "V" Vector__XXX
 SG_ CellVoltage_S1M4C02 m19 : 32|13@1+ (0.000610426077402027,0) [0|2] "V" Vector__XXX
 SG_ CellVoltage_S1M4C01 m19 : 16|13@1+ (0.000610426077402027,0) [0|2] "V" Vector__XXX
 SG_ CellVoltage_S1M3C18 m18 : 48|13@1+ (0.000610426077402027,0) [0|2] "V" Vector__XXX
 SG_ CellVoltage_S1M3C17 m18 : 32|13@1+ (0.000610426077402027,0) [0|2] "V" Vector__XXX
 SG_ CellVoltage_S1M3C16 m18 : 16|13@1+ (0.000610426077402027,0) [0|2] "V" Vector__XXX
 SG_ CellVoltage_S1M3C15 m17 : 48|13@1+ (0.000610426077402027,0) [0|2] "V" Vector__XXX
 SG_ CellVoltage_S1M3C14 m17 : 32|13@1+ (0.000610426077402027,0) [0|2] "V" Vector__XXX
 SG_ CellVoltage_S1M3C13 m17 : 16|13@1+ (0.000610426077402027,0) [0|2] "V" Vector__XXX
 SG_ CellVoltage_S1M3C12 m16 : 48|13@1+ (0.000610426077402027,0) [0|2] "V" Vector__XXX
 SG_ CellVoltage_S1M3C11 m16 : 32|13@1+ (0.000610426077402027,0) [0|2] "V" Vector__XXX
 SG_ CellVoltage_S1M3C10 m16 : 16|13@1+ (0.000610426077402027,0) [0|2] "V" Vector__XXX
 SG_ CellVoltage_S1M3C09 m15 : 48|13@1+ (0.000610426077402027,0) [0|2] "V" Vector__XXX
 SG_ CellVoltage_S1M3C08 m15 : 32|13@1+ (0.000610426077402027,0) [0|2] "V" Vector__XXX
 SG_ CellVoltage_S1M3C07 m15 : 16|13@1+ (0.000610426077402027,0) [0|2] "V" Vector__XXX
 SG_ CellVoltage_S1M3C06 m14 : 48|13@1+ (0.000610426077402027,0) [0|2] "V" Vector__XXX
 SG_ CellVoltage_S1M3C05 m14 : 32|13@1+ (0.000610426077402027,0) [0|2] "V" Vector__XXX
 SG_ CellVoltage_S1M3C04 m14 : 16|13@1+ (0.000610426077402027,0) [0|2] "V" Vector__XXX
 SG_ CellVoltage_S1M3C03 m13 : 48|13@1+ (0.000610426077402027,0) [0|2] "V" Vector__XXX
 SG_ CellVoltage_S1M3C02 m13 : 32|13@1+ (0.000610426077402027,0) [0|2] "V" Vector__XXX
 SG_ CellVoltage_S1M3C01 m13 : 16|13@1+ (0.000610426077402027,0) [0|2] "V" Vector__XXX
 SG_ CellVoltage_S1M2C18 m12 : 48|13@1+ (0.000610426077402027,0) [0|2] "V" Vector__XXX
 SG_ CellVoltage_S1M2C17 m12 : 32|13@1+ (0.000610426077402027,0) [0|2] "V" Vector__XXX
 SG_ CellVoltage_S1M2C16 m12 : 16|13@1+ (0.000610426077402027,0) [0|2] "V" Vector__XXX
 SG_ CellVoltage_S1M2C15 m11 : 48|13@1+ (0.000610426077402027,0) [0|2] "V" Vector__XXX
 SG_ CellVoltage_S1M2C14 m11 : 32|13@1+ (0.000610426077402027,0) [0|2] "V" Vector__XXX
 SG_ CellVoltage_S1M2C13 m11 : 16|13@1+ (0.000610426077402027,0) [0|2] "V" Vector__XXX
 SG_ CellVoltage_S1M2C12 m10 : 48|13@1+ (0.000610426077402027,0) [0|2] "V" Vector__XXX
 SG_ CellVoltage_S1M2C11 m10 : 32|13@1+ (0.000610426077402027,0) [0|2] "V" Vector__XXX
 SG_ CellVoltage_S1M2C10 m10 : 16|13@1+ (0.000610426077402027,0) [0|2] "V" Vector__XXX
 SG_ CellVoltage_S1M2C09 m9 : 48|13@1+ (0.000610426077402027,0) [0|2] "V" Vector__XXX
 SG_ CellVoltage_S1M2C08 m9 : 32|13@1+ (0.000610426077402027,0) [0|2] "V" Vector__XXX
 SG_ CellVoltage_S1M2C07 m9 : 16|13@1+ (0.000610426077402027,0) [0|2] "V" Vector__XXX
 SG_ CellVoltage_S1M2C06 m8 : 48|13@1+ (0.000610426077402027,0) [0|2] "V" Vector__XXX
 SG_ CellVoltage_S1M2C05 m8 : 32|13@1+ (0.000610426077402027,0) [0|2] "V" Vector__XXX
 SG_ CellVoltage_S1M2C04 m8 : 16|13@1+ (0.000610426077402027,0) [0|2] "V" Vector__XXX
 SG_ CellVoltage_S1M2C03 m7 : 48|13@1+ (0.000610426077402027,0) [0|2] "V" Vector__XXX
 SG_ CellVoltage_S1M2C02 m7 : 32|13@1+ (0.000610426077402027,0) [0|2] "V" Vector__XXX
 SG_ CellVoltage_S1M2C01 m7 : 16|13@1+ (0.000610426077402027,0) [0|2] "V" Vector__XXX
 SG_ CellVoltage_S1M1C18 m6 : 48|13@1+ (0.000610426077402027,0) [0|2] "V" Vector__XXX
 SG_ CellVoltage_S1M1C17 m6 : 32|13@1+ (0.000610426077402027,0) [0|2] "V" Vector__XXX
 SG_ CellVoltage_S1M1C16 m6 : 16|13@1+ (0.000610426077402027,0) [0|2] "V" Vector__XXX
 SG_ CellVoltage_S1M1C15 m5 : 48|13@1+ (0.000610426077402027,0) [0|2] "V" Vector__XXX
 SG_ CellVoltage_S1M1C14 m5 : 32|13@1+ (0.000610426077402027,0) [0|2] "V" Vector__XXX
 SG_ CellVoltage_S1M1C13 m5 : 16|13@1+ (0.000610426077402027,0) [0|2] "V" Vector__XXX
 SG_ CellVoltage_S1M1C12 m4 : 48|13@1+ (0.000610426077402027,0) [0|2] "V" Vector__XXX
 SG_ CellVoltage_S1M1C11 m4 : 32|13@1+ (0.000610426077402027,0) [0|2] "V" Vector__XXX
 SG_ CellVoltage_S1M1C10 m4 : 16|13@1+ (0.000610426077402027,0) [0|2] "V" Vector__XXX
 SG_ CellVoltage_S1M1C09 m3 : 48|13@1+ (0.000610426077402027,0) [0|2] "V" Vector__XXX
 SG_ CellVoltage_S1M1C08 m3 : 32|13@1+ (0.000610426077402027,0) [0|2] "V" Vector__XXX
 SG_ CellVoltage_S1M1C07 m3 : 16|13@1+ (0.000610426077402027,0) [0|2] "V" Vector__XXX
 SG_ CellVoltage_S1M1C06 m2 : 48|13@1+ (0.000610426077402027,0) [0|2] "V" Vector__XXX
 SG_ CellVoltage_S1M1C05 m2 : 32|13@1+ (0.000610426077402027,0) [0|2] "V" Vector__XXX
 SG_ CellVoltage_S1M1C04 m2 : 16|13@1+ (0.000610426077402027,0) [0|2] "V" Vector__XXX
 SG_ CellVoltage_S1M1C03 m1 : 48|13@1+ (0.000610426077402027,0) [0|2] "V" Vector__XXX
 SG_ CellVoltage_S1M1C02 m1 : 32|13@1+ (0.000610426077402027,0) [0|2] "V" Vector__XXX
 SG_ CellVoltage_S1M1C01 m1 : 16|13@1+ (0.000610426077402027,0) [0|2] "V" Vector__XXX
 SG_ CellTemp_S1M5TE m30 : 8|8@1+ (0.5,-40) [-40|87.5] "degC" Vector__XXX
 SG_ CellTemp_S1M5TD m29 : 8|8@1+ (0.5,-40) [-40|87.5] "degC" Vector__XXX
 SG_ CellTemp_S1M5TC m28 : 8|8@1+ (0.5,-40) [-40|87.5] "degC" Vector__XXX
 SG_ CellTemp_S1M5TB m26 : 8|8@1+ (0.5,-40) [-40|87.5] "degC" Vector__XXX
 SG_ CellTemp_S1M5TA m25 : 8|8@1+ (0.5,-40) [-40|87.5] "degC" Vector__XXX
 SG_ CellTemp_S1M4TE m24 : 8|8@1+ (0.5,-40) [-40|87.5] "degC" Vector__XXX
 SG_ CellTemp_S1M4TD m23 : 8|8@1+ (0.5,-40) [-40|87.5] "degC" Vector__XXX
 SG_ CellTemp_S1M4TC m22 : 8|8@1+ (0.5,-40) [-40|87.5] "degC" Vector__XXX
 SG_ CellTemp_S1M4TB m20 : 8|8@1+ (0.5,-40) [-40|87.5] "degC" Vector__XXX
 SG_ CellTemp_S1M4TA m19 : 8|8@1+ (0.5,-40) [-40|87.5] "degC" Vector__XXX
 SG_ CellTemp_S1M3TE m18 : 8|8@1+ (0.5,-40) [-40|87.5] "degC" Vector__XXX
 SG_ CellTemp_S1M3TD m17 : 8|8@1+ (0.5,-40) [-40|87.5] "degC" Vector__XXX
 SG_ CellTemp_S1M3TC m16 : 8|8@1+ (0.5,-40) [-40|87.5] "degC" Vector__XXX
 SG_ CellTemp_S1M3TB m14 : 8|8@1+ (0.5,-40) [-40|87.5] "degC" Vector__XXX
 SG_ CellTemp_S1M3TA m13 : 8|8@1+ (0.5,-40) [-40|87.5] "degC" Vector__XXX
 SG_ CellTemp_S1M2TE m12 : 8|8@1+ (0.5,-40) [-40|87.5] "degC" Vector__XXX
 SG_ CellTemp_S1M2TD m11 : 8|8@1+ (0.5,-40) [-40|87.5] "degC" Vector__XXX
 SG_ CellTemp_S1M2TC m10 : 8|8@1+ (0.5,-40) [-40|87.5] "degC" Vector__XXX
 SG_ CellTemp_S1M2TB m8 : 8|8@1+ (0.5,-40) [-40|87.5] "degC" Vector__XXX
 SG_ CellTemp_S1M2TA m7 : 8|8@1+ (0.5,-40) [-40|87.5] "degC" Vector__XXX
 SG_ CellTemp_S1M1TE m6 : 8|8@1+ (0.5,-40) [-40|87.5] "degC" Vector__XXX
 SG_ CellTemp_S1M1TD m5 : 8|8@1+ (0.5,-40) [-40|87.5] "degC" Vector__XXX
 SG_ CellTemp_S1M1TC m4 : 8|8@1+ (0.5,-40) [-40|87.5] "degC" Vector__XXX
 SG_ CellTemp_S1M1TB m2 : 8|8@1+ (0.5,-40) [-40|87.5] "degC" Vector__XXX
 SG_ CellTemp_S1M1TA m1 : 8|8@1+ (0.5,-40) [-40|87.5] "degC" Vector__XXX
 SG_ CellMultiplexor M : 0|6@1+ (1,0) [0|42] "" Vector__XXX

BO_ 1014 Cell_Details_Shelf6: 8 Shelf6
 SG_ CellFault_OverTemp_S1M5TE m29 : 7|1@1+ (1,0) [0|0] "" Vector__XXX
 SG_ CellFault_OverTemp_S1M5TD m28 : 7|1@1+ (1,0) [0|0] "" Vector__XXX
 SG_ CellFault_OverTemp_S1M5TC m27 : 7|1@1+ (1,0) [0|0] "" Vector__XXX
 SG_ CellFault_OverTemp_S1M5TB m26 : 7|1@1+ (1,0) [0|0] "" Vector__XXX
 SG_ CellFault_OverTemp_S1M5TA m25 : 7|1@1+ (1,0) [0|0] "" Vector__XXX
 SG_ CellFault_OverTemp_S1M4TE m23 : 7|1@1+ (1,0) [0|0] "" Vector__XXX
 SG_ CellFault_OverTemp_S1M4TD m22 : 7|1@1+ (1,0) [0|0] "" Vector__XXX
 SG_ CellFault_OverTemp_S1M4TC m21 : 7|1@1+ (1,0) [0|0] "" Vector__XXX
 SG_ CellFault_OverTemp_S1M4TB m20 : 7|1@1+ (1,0) [0|0] "" Vector__XXX
 SG_ CellFault_OverTemp_S1M4TA m19 : 7|1@1+ (1,0) [0|0] "" Vector__XXX
 SG_ CellFault_OverTemp_S1M3TE m17 : 7|1@1+ (1,0) [0|0] "" Vector__XXX
 SG_ CellFault_OverTemp_S1M3TD m16 : 7|1@1+ (1,0) [0|0] "" Vector__XXX
 SG_ CellFault_OverTemp_S1M3TC m15 : 7|1@1+ (1,0) [0|0] "" Vector__XXX
 SG_ CellFault_OverTemp_S1M3TB m14 : 7|1@1+ (1,0) [0|0] "" Vector__XXX
 SG_ CellFault_OverTemp_S1M3TA m13 : 7|1@1+ (1,0) [0|0] "" Vector__XXX
 SG_ CellFault_OverTemp_S1M2TE m11 : 7|1@1+ (1,0) [0|0] "" Vector__XXX
 SG_ CellFault_OverTemp_S1M2TD m10 : 7|1@1+ (1,0) [0|0] "" Vector__XXX
 SG_ CellFault_OverTemp_S1M2TC m9 : 7|1@1+ (1,0) [0|0] "" Vector__XXX
 SG_ CellFault_OverTemp_S1M2TB m8 : 7|1@1+ (1,0) [0|0] "" Vector__XXX
 SG_ CellFault_OverTemp_S1M2TA m7 : 7|1@1+ (1,0) [0|0] "" Vector__XXX
 SG_ CellFault_OverTemp_S1M1TE m6 : 7|1@1+ (1,0) [0|0] "" Vector__XXX
 SG_ CellFault_OverTemp_S1M1TD m5 : 7|1@1+ (1,0) [0|0] "" Vector__XXX
 SG_ CellFault_OverTemp_S1M1TC m4 : 7|1@1+ (1,0) [0|0] "" Vector__XXX
 SG_ CellFault_OverTemp_S1M1TB m2 : 7|1@1+ (1,0) [0|0] "" Vector__XXX
 SG_ CellFault_OverTemp_S1M1TA m1 : 7|1@1+ (1,0) [0|0] "" Vector__XXX
 SG_ CellFault_Wire_S1M5C18 m30 : 62|1@1+ (1,0) [0|0] "" Vector__XXX
 SG_ CellFault_Wire_S1M5C17 m30 : 46|1@1+ (1,0) [0|0] "" Vector__XXX
 SG_ CellFault_Wire_S1M5C16 m30 : 30|1@1+ (1,0) [0|0] "" Vector__XXX
 SG_ CellFault_Wire_S1M5C15 m29 : 62|1@1+ (1,0) [0|0] "" Vector__XXX
 SG_ CellFault_Wire_S1M5C14 m29 : 46|1@1+ (1,0) [0|0] "" Vector__XXX
 SG_ CellFault_Wire_S1M5C13 m29 : 30|1@1+ (1,0) [0|0] "" Vector__XXX
 SG_ CellFault_Wire_S1M5C12 m28 : 62|1@1+ (1,0) [0|0] "" Vector__XXX
 SG_ CellFault_Wire_S1M5C11 m28 : 46|1@1+ (1,0) [0|0] "" Vector__XXX
 SG_ CellFault_Wire_S1M5C10 m28 : 30|1@1+ (1,0) [0|0] "" Vector__XXX
 SG_ CellFault_Wire_S1M5C09 m27 : 62|1@1+ (1,0) [0|0] "" Vector__XXX
 SG_ CellFault_Wire_S1M5C08 m27 : 46|1@1+ (1,0) [0|0] "" Vector__XXX
 SG_ CellFault_Wire_S1M5C07 m27 : 30|1@1+ (1,0) [0|0] "" Vector__XXX
 SG_ CellFault_Wire_S1M5C06 m26 : 62|1@1+ (1,0) [0|0] "" Vector__XXX
 SG_ CellFault_Wire_S1M5C05 m26 : 46|1@1+ (1,0) [0|0] "" Vector__XXX
 SG_ CellFault_Wire_S1M5C04 m26 : 30|1@1+ (1,0) [0|0] "" Vector__XXX
 SG_ CellFault_Wire_S1M5C03 m25 : 62|1@1+ (1,0) [0|0] "" Vector__XXX
 SG_ CellFault_Wire_S1M5C02 m25 : 46|1@1+ (1,0) [0|0] "" Vector__XXX
 SG_ CellFault_Wire_S1M5C01 m25 : 30|1@1+ (1,0) [0|0] "" Vector__XXX
 SG_ CellFault_Wire_S1M4C18 m24 : 62|1@1+ (1,0) [0|0] "" Vector__XXX
 SG_ CellFault_Wire_S1M4C17 m24 : 46|1@1+ (1,0) [0|0] "" Vector__XXX
 SG_ CellFault_Wire_S1M4C16 m24 : 30|1@1+ (1,0) [0|0] "" Vector__XXX
 SG_ CellFault_Wire_S1M4C15 m23 : 62|1@1+ (1,0) [0|0] "" Vector__XXX
 SG_ CellFault_Wire_S1M4C14 m23 : 46|1@1+ (1,0) [0|0] "" Vector__XXX
 SG_ CellFault_Wire_S1M4C13 m23 : 30|1@1+ (1,0) [0|0] "" Vector__XXX
 SG_ CellFault_Wire_S1M4C12 m22 : 62|1@1+ (1,0) [0|0] "" Vector__XXX
 SG_ CellFault_Wire_S1M4C11 m22 : 46|1@1+ (1,0) [0|0] "" Vector__XXX
 SG_ CellFault_Wire_S1M4C10 m22 : 30|1@1+ (1,0) [0|0] "" Vector__XXX
 SG_ CellFault_Wire_S1M4C09 m21 : 62|1@1+ (1,0) [0|0] "" Vector__XXX
 SG_ CellFault_Wire_S1M4C08 m21 : 46|1@1+ (1,0) [0|0] "" Vector__XXX
 SG_ CellFault_Wire_S1M4C07 m21 : 30|1@1+ (1,0) [0|0] "" Vector__XXX
 SG_ CellFault_Wire_S1M4C06 m20 : 62|1@1+ (1,0) [0|0] "" Vector__XXX
 SG_ CellFault_Wire_S1M4C05 m20 : 46|1@1+ (1,0) [0|0] "" Vector__XXX
 SG_ CellFault_Wire_S1M4C04 m20 : 30|1@1+ (1,0) [0|0] "" Vector__XXX
 SG_ CellFault_Wire_S1M4C03 m19 : 62|1@1+ (1,0) [0|0] "" Vector__XXX
 SG_ CellFault_Wire_S1M4C02 m19 : 46|1@1+ (1,0) [0|0] "" Vector__XXX
 SG_ CellFault_Wire_S1M4C01 m19 : 30|1@1+ (1,0) [0|0] "" Vector__XXX
 SG_ CellFault_Wire_S1M3C18 m18 : 62|1@1+ (1,0) [0|0] "" Vector__XXX
 SG_ CellFault_Wire_S1M3C17 m18 : 46|1@1+ (1,0) [0|0] "" Vector__XXX
 SG_ CellFault_Wire_S1M3C16 m18 : 30|1@1+ (1,0) [0|0] "" Vector__XXX
 SG_ CellFault_Wire_S1M3C15 m17 : 62|1@1+ (1,0) [0|0] "" Vector__XXX
 SG_ CellFault_Wire_S1M3C14 m17 : 46|1@1+ (1,0) [0|0] "" Vector__XXX
 SG_ CellFault_Wire_S1M3C13 m17 : 30|1@1+ (1,0) [0|0] "" Vector__XXX
 SG_ CellFault_Wire_S1M3C12 m16 : 62|1@1+ (1,0) [0|0] "" Vector__XXX
 SG_ CellFault_Wire_S1M3C11 m16 : 46|1@1+ (1,0) [0|0] "" Vector__XXX
 SG_ CellFault_Wire_S1M3C10 m16 : 30|1@1+ (1,0) [0|0] "" Vector__XXX
 SG_ CellFault_Wire_S1M3C09 m15 : 62|1@1+ (1,0) [0|0] "" Vector__XXX
 SG_ CellFault_Wire_S1M3C08 m15 : 46|1@1+ (1,0) [0|0] "" Vector__XXX
 SG_ CellFault_Wire_S1M3C07 m15 : 30|1@1+ (1,0) [0|0] "" Vector__XXX
 SG_ CellFault_Wire_S1M3C06 m14 : 62|1@1+ (1,0) [0|0] "" Vector__XXX
 SG_ CellFault_Wire_S1M3C05 m14 : 46|1@1+ (1,0) [0|0] "" Vector__XXX
 SG_ CellFault_Wire_S1M3C04 m14 : 30|1@1+ (1,0) [0|0] "" Vector__XXX
 SG_ CellFault_Wire_S1M3C03 m13 : 62|1@1+ (1,0) [0|0] "" Vector__XXX
 SG_ CellFault_Wire_S1M3C02 m13 : 46|1@1+ (1,0) [0|0] "" Vector__XXX
 SG_ CellFault_Wire_S1M3C01 m13 : 30|1@1+ (1,0) [0|0] "" Vector__XXX
 SG_ CellFault_Wire_S1M2C18 m12 : 62|1@1+ (1,0) [0|0] "" Vector__XXX
 SG_ CellFault_Wire_S1M2C17 m12 : 46|1@1+ (1,0) [0|0] "" Vector__XXX
 SG_ CellFault_Wire_S1M2C16 m12 : 30|1@1+ (1,0) [0|0] "" Vector__XXX
 SG_ CellFault_Wire_S1M2C15 m11 : 62|1@1+ (1,0) [0|0] "" Vector__XXX
 SG_ CellFault_Wire_S1M2C14 m11 : 46|1@1+ (1,0) [0|0] "" Vector__XXX
 SG_ CellFault_Wire_S1M2C13 m11 : 30|1@1+ (1,0) [0|0] "" Vector__XXX
 SG_ CellFault_Wire_S1M2C12 m10 : 62|1@1+ (1,0) [0|0] "" Vector__XXX
 SG_ CellFault_Wire_S1M2C11 m10 : 46|1@1+ (1,0) [0|0] "" Vector__XXX
 SG_ CellFault_Wire_S1M2C10 m10 : 30|1@1+ (1,0) [0|0] "" Vector__XXX
 SG_ CellFault_Wire_S1M2C09 m9 : 62|1@1+ (1,0) [0|0] "" Vector__XXX
 SG_ CellFault_Wire_S1M2C08 m9 : 46|1@1+ (1,0) [0|0] "" Vector__XXX
 SG_ CellFault_Wire_S1M2C07 m9 : 30|1@1+ (1,0) [0|0] "" Vector__XXX
 SG_ CellFault_Wire_S1M2C06 m8 : 62|1@1+ (1,0) [0|0] "" Vector__XXX
 SG_ CellFault_Wire_S1M2C05 m8 : 46|1@1+ (1,0) [0|0] "" Vector__XXX
 SG_ CellFault_Wire_S1M2C04 m8 : 30|1@1+ (1,0) [0|0] "" Vector__XXX
 SG_ CellFault_Wire_S1M2C03 m7 : 62|1@1+ (1,0) [0|0] "" Vector__XXX
 SG_ CellFault_Wire_S1M2C02 m7 : 46|1@1+ (1,0) [0|0] "" Vector__XXX
 SG_ CellFault_Wire_S1M2C01 m7 : 30|1@1+ (1,0) [0|0] "" Vector__XXX
 SG_ CellFault_Wire_S1M1C18 m6 : 62|1@1+ (1,0) [0|0] "" Vector__XXX
 SG_ CellFault_Wire_S1M1C17 m6 : 46|1@1+ (1,0) [0|0] "" Vector__XXX
 SG_ CellFault_Wire_S1M1C16 m6 : 30|1@1+ (1,0) [0|0] "" Vector__XXX
 SG_ CellFault_Wire_S1M1C15 m5 : 62|1@1+ (1,0) [0|0] "" Vector__XXX
 SG_ CellFault_Wire_S1M1C14 m5 : 46|1@1+ (1,0) [0|0] "" Vector__XXX
 SG_ CellFault_Wire_S1M1C13 m5 : 30|1@1+ (1,0) [0|0] "" Vector__XXX
 SG_ CellFault_Wire_S1M1C12 m4 : 62|1@1+ (1,0) [0|0] "" Vector__XXX
 SG_ CellFault_Wire_S1M1C11 m4 : 46|1@1+ (1,0) [0|0] "" Vector__XXX
 SG_ CellFault_Wire_S1M1C10 m4 : 30|1@1+ (1,0) [0|0] "" Vector__XXX
 SG_ CellFault_Wire_S1M1C09 m3 : 62|1@1+ (1,0) [0|0] "" Vector__XXX
 SG_ CellFault_Wire_S1M1C08 m3 : 46|1@1+ (1,0) [0|0] "" Vector__XXX
 SG_ CellFault_Wire_S1M1C07 m3 : 30|1@1+ (1,0) [0|0] "" Vector__XXX
 SG_ CellFault_Wire_S1M1C06 m2 : 62|1@1+ (1,0) [0|0] "" Vector__XXX
 SG_ CellFault_Wire_S1M1C05 m2 : 46|1@1+ (1,0) [0|0] "" Vector__XXX
 SG_ CellFault_Wire_S1M1C04 m2 : 30|1@1+ (1,0) [0|0] "" Vector__XXX
 SG_ CellFault_Wire_S1M1C03 m1 : 62|1@1+ (1,0) [0|0] "" Vector__XXX
 SG_ CellFault_Wire_S1M1C02 m1 : 46|1@1+ (1,0) [0|0] "" Vector__XXX
 SG_ CellFault_Wire_S1M1C01 m1 : 30|1@1+ (1,0) [0|0] "" Vector__XXX
 SG_ CellFault_Voltage_S1M5C18 m30 : 63|1@1+ (1,0) [0|0] "" Vector__XXX
 SG_ CellFault_Voltage_S1M5C17 m30 : 47|1@1+ (1,0) [0|0] "" Vector__XXX
 SG_ CellFault_Voltage_S1M5C16 m30 : 31|1@1+ (1,0) [0|0] "" Vector__XXX
 SG_ CellFault_Voltage_S1M5C15 m29 : 63|1@1+ (1,0) [0|0] "" Vector__XXX
 SG_ CellFault_Voltage_S1M5C14 m29 : 47|1@1+ (1,0) [0|0] "" Vector__XXX
 SG_ CellFault_Voltage_S1M5C13 m29 : 31|1@1+ (1,0) [0|0] "" Vector__XXX
 SG_ CellFault_Voltage_S1M5C12 m28 : 63|1@1+ (1,0) [0|0] "" Vector__XXX
 SG_ CellFault_Voltage_S1M5C11 m28 : 47|1@1+ (1,0) [0|0] "" Vector__XXX
 SG_ CellFault_Voltage_S1M5C10 m28 : 31|1@1+ (1,0) [0|0] "" Vector__XXX
 SG_ CellFault_Voltage_S1M5C09 m27 : 63|1@1+ (1,0) [0|0] "" Vector__XXX
 SG_ CellFault_Voltage_S1M5C08 m27 : 47|1@1+ (1,0) [0|0] "" Vector__XXX
 SG_ CellFault_Voltage_S1M5C07 m27 : 31|1@1+ (1,0) [0|0] "" Vector__XXX
 SG_ CellFault_Voltage_S1M5C06 m26 : 63|1@1+ (1,0) [0|0] "" Vector__XXX
 SG_ CellFault_Voltage_S1M5C05 m26 : 47|1@1+ (1,0) [0|0] "" Vector__XXX
 SG_ CellFault_Voltage_S1M5C04 m26 : 31|1@1+ (1,0) [0|0] "" Vector__XXX
 SG_ CellFault_Voltage_S1M5C03 m25 : 63|1@1+ (1,0) [0|0] "" Vector__XXX
 SG_ CellFault_Voltage_S1M5C02 m25 : 47|1@1+ (1,0) [0|0] "" Vector__XXX
 SG_ CellFault_Voltage_S1M5C01 m25 : 31|1@1+ (1,0) [0|0] "" Vector__XXX
 SG_ CellFault_Voltage_S1M4C18 m24 : 63|1@1+ (1,0) [0|0] "" Vector__XXX
 SG_ CellFault_Voltage_S1M4C17 m24 : 47|1@1+ (1,0) [0|0] "" Vector__XXX
 SG_ CellFault_Voltage_S1M4C16 m24 : 31|1@1+ (1,0) [0|0] "" Vector__XXX
 SG_ CellFault_Voltage_S1M4C15 m23 : 63|1@1+ (1,0) [0|0] "" Vector__XXX
 SG_ CellFault_Voltage_S1M4C14 m23 : 47|1@1+ (1,0) [0|0] "" Vector__XXX
 SG_ CellFault_Voltage_S1M4C13 m23 : 31|1@1+ (1,0) [0|0] "" Vector__XXX
 SG_ CellFault_Voltage_S1M4C12 m22 : 63|1@1+ (1,0) [0|0] "" Vector__XXX
 SG_ CellFault_Voltage_S1M4C11 m22 : 47|1@1+ (1,0) [0|0] "" Vector__XXX
 SG_ CellFault_Voltage_S1M4C10 m22 : 31|1@1+ (1,0) [0|0] "" Vector__XXX
 SG_ CellFault_Voltage_S1M4C09 m21 : 63|1@1+ (1,0) [0|0] "" Vector__XXX
 SG_ CellFault_Voltage_S1M4C08 m21 : 47|1@1+ (1,0) [0|0] "" Vector__XXX
 SG_ CellFault_Voltage_S1M4C07 m21 : 31|1@1+ (1,0) [0|0] "" Vector__XXX
 SG_ CellFault_Voltage_S1M4C06 m20 : 63|1@1+ (1,0) [0|0] "" Vector__XXX
 SG_ CellFault_Voltage_S1M4C05 m20 : 47|1@1+ (1,0) [0|0] "" Vector__XXX
 SG_ CellFault_Voltage_S1M4C04 m20 : 31|1@1+ (1,0) [0|0] "" Vector__XXX
 SG_ CellFault_Voltage_S1M4C03 m19 : 63|1@1+ (1,0) [0|0] "" Vector__XXX
 SG_ CellFault_Voltage_S1M4C02 m19 : 47|1@1+ (1,0) [0|0] "" Vector__XXX
 SG_ CellFault_Voltage_S1M4C01 m19 : 31|1@1+ (1,0) [0|0] "" Vector__XXX
 SG_ CellFault_Voltage_S1M3C18 m18 : 63|1@1+ (1,0) [0|0] "" Vector__XXX
 SG_ CellFault_Voltage_S1M3C17 m18 : 47|1@1+ (1,0) [0|0] "" Vector__XXX
 SG_ CellFault_Voltage_S1M3C16 m18 : 31|1@1+ (1,0) [0|0] "" Vector__XXX
 SG_ CellFault_Voltage_S1M3C15 m17 : 63|1@1+ (1,0) [0|0] "" Vector__XXX
 SG_ CellFault_Voltage_S1M3C14 m17 : 47|1@1+ (1,0) [0|0] "" Vector__XXX
 SG_ CellFault_Voltage_S1M3C13 m17 : 31|1@1+ (1,0) [0|0] "" Vector__XXX
 SG_ CellFault_Voltage_S1M3C12 m16 : 63|1@1+ (1,0) [0|0] "" Vector__XXX
 SG_ CellFault_Voltage_S1M3C11 m16 : 47|1@1+ (1,0) [0|0] "" Vector__XXX
 SG_ CellFault_Voltage_S1M3C10 m16 : 31|1@1+ (1,0) [0|0] "" Vector__XXX
 SG_ CellFault_Voltage_S1M3C09 m15 : 63|1@1+ (1,0) [0|0] "" Vector__XXX
 SG_ CellFault_Voltage_S1M3C08 m15 : 47|1@1+ (1,0) [0|0] "" Vector__XXX
 SG_ CellFault_Voltage_S1M3C07 m15 : 31|1@1+ (1,0) [0|0] "" Vector__XXX
 SG_ CellFault_Voltage_S1M3C06 m14 : 63|1@1+ (1,0) [0|0] "" Vector__XXX
 SG_ CellFault_Voltage_S1M3C05 m14 : 47|1@1+ (1,0) [0|0] "" Vector__XXX
 SG_ CellFault_Voltage_S1M3C04 m14 : 31|1@1+ (1,0) [0|0] "" Vector__XXX
 SG_ CellFault_Voltage_S1M3C03 m13 : 63|1@1+ (1,0) [0|0] "" Vector__XXX
 SG_ CellFault_Voltage_S1M3C02 m13 : 47|1@1+ (1,0) [0|0] "" Vector__XXX
 SG_ CellFault_Voltage_S1M3C01 m13 : 31|1@1+ (1,0) [0|0] "" Vector__XXX
 SG_ CellFault_Voltage_S1M2C18 m12 : 63|1@1+ (1,0) [0|0] "" Vector__XXX
 SG_ CellFault_Voltage_S1M2C17 m12 : 47|1@1+ (1,0) [0|0] "" Vector__XXX
 SG_ CellFault_Voltage_S1M2C16 m12 : 31|1@1+ (1,0) [0|0] "" Vector__XXX
 SG_ CellFault_Voltage_S1M2C15 m11 : 63|1@1+ (1,0) [0|0] "" Vector__XXX
 SG_ CellFault_Voltage_S1M2C14 m11 : 47|1@1+ (1,0) [0|0] "" Vector__XXX
 SG_ CellFault_Voltage_S1M2C13 m11 : 31|1@1+ (1,0) [0|0] "" Vector__XXX
 SG_ CellFault_Voltage_S1M2C12 m10 : 63|1@1+ (1,0) [0|0] "" Vector__XXX
 SG_ CellFault_Voltage_S1M2C11 m10 : 47|1@1+ (1,0) [0|0] "" Vector__XXX
 SG_ CellFault_Voltage_S1M2C10 m10 : 31|1@1+ (1,0) [0|0] "" Vector__XXX
 SG_ CellFault_Voltage_S1M2C09 m9 : 63|1@1+ (1,0) [0|0] "" Vector__XXX
 SG_ CellFault_Voltage_S1M2C08 m9 : 47|1@1+ (1,0) [0|0] "" Vector__XXX
 SG_ CellFault_Voltage_S1M2C07 m9 : 31|1@1+ (1,0) [0|0] "" Vector__XXX
 SG_ CellFault_Voltage_S1M2C06 m8 : 63|1@1+ (1,0) [0|0] "" Vector__XXX
 SG_ CellFault_Voltage_S1M2C05 m8 : 47|1@1+ (1,0) [0|0] "" Vector__XXX
 SG_ CellFault_Voltage_S1M2C04 m8 : 31|1@1+ (1,0) [0|0] "" Vector__XXX
 SG_ CellFault_Voltage_S1M2C03 m7 : 63|1@1+ (1,0) [0|0] "" Vector__XXX
 SG_ CellFault_Voltage_S1M2C02 m7 : 47|1@1+ (1,0) [0|0] "" Vector__XXX
 SG_ CellFault_Voltage_S1M2C01 m7 : 31|1@1+ (1,0) [0|0] "" Vector__XXX
 SG_ CellFault_Voltage_S1M1C18 m6 : 63|1@1+ (1,0) [0|0] "" Vector__XXX
 SG_ CellFault_Voltage_S1M1C17 m6 : 47|1@1+ (1,0) [0|0] "" Vector__XXX
 SG_ CellFault_Voltage_S1M1C16 m6 : 31|1@1+ (1,0) [0|0] "" Vector__XXX
 SG_ CellFault_Voltage_S1M1C15 m5 : 63|1@1+ (1,0) [0|0] "" Vector__XXX
 SG_ CellFault_Voltage_S1M1C14 m5 : 47|1@1+ (1,0) [0|0] "" Vector__XXX
 SG_ CellFault_Voltage_S1M1C13 m5 : 31|1@1+ (1,0) [0|0] "" Vector__XXX
 SG_ CellFault_Voltage_S1M1C12 m4 : 63|1@1+ (1,0) [0|0] "" Vector__XXX
 SG_ CellFault_Voltage_S1M1C11 m4 : 47|1@1+ (1,0) [0|0] "" Vector__XXX
 SG_ CellFault_Voltage_S1M1C10 m4 : 31|1@1+ (1,0) [0|0] "" Vector__XXX
 SG_ CellFault_Voltage_S1M1C09 m3 : 63|1@1+ (1,0) [0|0] "" Vector__XXX
 SG_ CellFault_Voltage_S1M1C08 m3 : 47|1@1+ (1,0) [0|0] "" Vector__XXX
 SG_ CellFault_Voltage_S1M1C07 m3 : 31|1@1+ (1,0) [0|0] "" Vector__XXX
 SG_ CellFault_Voltage_S1M1C06 m2 : 63|1@1+ (1,0) [0|0] "" Vector__XXX
 SG_ CellFault_Voltage_S1M1C05 m2 : 47|1@1+ (1,0) [0|0] "" Vector__XXX
 SG_ CellFault_Voltage_S1M1C04 m2 : 31|1@1+ (1,0) [0|0] "" Vector__XXX
 SG_ CellFault_Voltage_S1M1C03 m1 : 63|1@1+ (1,0) [0|0] "" Vector__XXX
 SG_ CellFault_Voltage_S1M1C02 m1 : 47|1@1+ (1,0) [0|0] "" Vector__XXX
 SG_ CellFault_Voltage_S1M1C01 m1 : 31|1@1+ (1,0) [0|0] "" Vector__XXX
 SG_ CellBalanceFET_S1M5C18 m30 : 61|1@1+ (1,0) [0|0] "" Vector__XXX
 SG_ CellBalanceFET_S1M5C17 m30 : 45|1@1+ (1,0) [0|0] "" Vector__XXX
 SG_ CellBalanceFET_S1M5C16 m30 : 29|1@1+ (1,0) [0|0] "" Vector__XXX
 SG_ CellBalanceFET_S1M5C15 m29 : 61|1@1+ (1,0) [0|0] "" Vector__XXX
 SG_ CellBalanceFET_S1M5C14 m29 : 45|1@1+ (1,0) [0|0] "" Vector__XXX
 SG_ CellBalanceFET_S1M5C13 m29 : 29|1@1+ (1,0) [0|0] "" Vector__XXX
 SG_ CellBalanceFET_S1M5C12 m28 : 61|1@1+ (1,0) [0|0] "" Vector__XXX
 SG_ CellBalanceFET_S1M5C11 m28 : 45|1@1+ (1,0) [0|0] "" Vector__XXX
 SG_ CellBalanceFET_S1M5C10 m28 : 29|1@1+ (1,0) [0|0] "" Vector__XXX
 SG_ CellBalanceFET_S1M5C09 m27 : 61|1@1+ (1,0) [0|0] "" Vector__XXX
 SG_ CellBalanceFET_S1M5C08 m27 : 45|1@1+ (1,0) [0|0] "" Vector__XXX
 SG_ CellBalanceFET_S1M5C07 m27 : 29|1@1+ (1,0) [0|0] "" Vector__XXX
 SG_ CellBalanceFET_S1M5C06 m26 : 61|1@1+ (1,0) [0|0] "" Vector__XXX
 SG_ CellBalanceFET_S1M5C05 m26 : 45|1@1+ (1,0) [0|0] "" Vector__XXX
 SG_ CellBalanceFET_S1M5C04 m26 : 29|1@1+ (1,0) [0|0] "" Vector__XXX
 SG_ CellBalanceFET_S1M5C03 m25 : 61|1@1+ (1,0) [0|0] "" Vector__XXX
 SG_ CellBalanceFET_S1M5C02 m25 : 45|1@1+ (1,0) [0|0] "" Vector__XXX
 SG_ CellBalanceFET_S1M5C01 m25 : 29|1@1+ (1,0) [0|0] "" Vector__XXX
 SG_ CellBalanceFET_S1M4C18 m24 : 61|1@1+ (1,0) [0|0] "" Vector__XXX
 SG_ CellBalanceFET_S1M4C17 m24 : 45|1@1+ (1,0) [0|0] "" Vector__XXX
 SG_ CellBalanceFET_S1M4C16 m24 : 29|1@1+ (1,0) [0|0] "" Vector__XXX
 SG_ CellBalanceFET_S1M4C15 m23 : 61|1@1+ (1,0) [0|0] "" Vector__XXX
 SG_ CellBalanceFET_S1M4C14 m23 : 45|1@1+ (1,0) [0|0] "" Vector__XXX
 SG_ CellBalanceFET_S1M4C13 m23 : 29|1@1+ (1,0) [0|0] "" Vector__XXX
 SG_ CellBalanceFET_S1M4C12 m22 : 61|1@1+ (1,0) [0|0] "" Vector__XXX
 SG_ CellBalanceFET_S1M4C11 m22 : 45|1@1+ (1,0) [0|0] "" Vector__XXX
 SG_ CellBalanceFET_S1M4C10 m22 : 29|1@1+ (1,0) [0|0] "" Vector__XXX
 SG_ CellBalanceFET_S1M4C09 m21 : 61|1@1+ (1,0) [0|0] "" Vector__XXX
 SG_ CellBalanceFET_S1M4C08 m21 : 45|1@1+ (1,0) [0|0] "" Vector__XXX
 SG_ CellBalanceFET_S1M4C07 m21 : 29|1@1+ (1,0) [0|0] "" Vector__XXX
 SG_ CellBalanceFET_S1M4C06 m20 : 61|1@1+ (1,0) [0|0] "" Vector__XXX
 SG_ CellBalanceFET_S1M4C05 m20 : 45|1@1+ (1,0) [0|0] "" Vector__XXX
 SG_ CellBalanceFET_S1M4C04 m20 : 29|1@1+ (1,0) [0|0] "" Vector__XXX
 SG_ CellBalanceFET_S1M4C03 m19 : 61|1@1+ (1,0) [0|0] "" Vector__XXX
 SG_ CellBalanceFET_S1M4C02 m19 : 45|1@1+ (1,0) [0|0] "" Vector__XXX
 SG_ CellBalanceFET_S1M4C01 m19 : 29|1@1+ (1,0) [0|0] "" Vector__XXX
 SG_ CellBalanceFET_S1M3C18 m18 : 61|1@1+ (1,0) [0|0] "" Vector__XXX
 SG_ CellBalanceFET_S1M3C17 m18 : 45|1@1+ (1,0) [0|0] "" Vector__XXX
 SG_ CellBalanceFET_S1M3C16 m18 : 29|1@1+ (1,0) [0|0] "" Vector__XXX
 SG_ CellBalanceFET_S1M3C15 m17 : 61|1@1+ (1,0) [0|0] "" Vector__XXX
 SG_ CellBalanceFET_S1M3C14 m17 : 45|1@1+ (1,0) [0|0] "" Vector__XXX
 SG_ CellBalanceFET_S1M3C13 m17 : 29|1@1+ (1,0) [0|0] "" Vector__XXX
 SG_ CellBalanceFET_S1M3C12 m16 : 61|1@1+ (1,0) [0|0] "" Vector__XXX
 SG_ CellBalanceFET_S1M3C11 m16 : 45|1@1+ (1,0) [0|0] "" Vector__XXX
 SG_ CellBalanceFET_S1M3C10 m16 : 29|1@1+ (1,0) [0|0] "" Vector__XXX
 SG_ CellBalanceFET_S1M3C09 m15 : 61|1@1+ (1,0) [0|0] "" Vector__XXX
 SG_ CellBalanceFET_S1M3C08 m15 : 45|1@1+ (1,0) [0|0] "" Vector__XXX
 SG_ CellBalanceFET_S1M3C07 m15 : 29|1@1+ (1,0) [0|0] "" Vector__XXX
 SG_ CellBalanceFET_S1M3C06 m14 : 61|1@1+ (1,0) [0|0] "" Vector__XXX
 SG_ CellBalanceFET_S1M3C05 m14 : 45|1@1+ (1,0) [0|0] "" Vector__XXX
 SG_ CellBalanceFET_S1M3C04 m14 : 29|1@1+ (1,0) [0|0] "" Vector__XXX
 SG_ CellBalanceFET_S1M3C03 m13 : 61|1@1+ (1,0) [0|0] "" Vector__XXX
 SG_ CellBalanceFET_S1M3C02 m13 : 45|1@1+ (1,0) [0|0] "" Vector__XXX
 SG_ CellBalanceFET_S1M3C01 m13 : 29|1@1+ (1,0) [0|0] "" Vector__XXX
 SG_ CellBalanceFET_S1M2C18 m12 : 61|1@1+ (1,0) [0|0] "" Vector__XXX
 SG_ CellBalanceFET_S1M2C17 m12 : 45|1@1+ (1,0) [0|0] "" Vector__XXX
 SG_ CellBalanceFET_S1M2C16 m12 : 29|1@1+ (1,0) [0|0] "" Vector__XXX
 SG_ CellBalanceFET_S1M2C15 m11 : 61|1@1+ (1,0) [0|0] "" Vector__XXX
 SG_ CellBalanceFET_S1M2C14 m11 : 45|1@1+ (1,0) [0|0] "" Vector__XXX
 SG_ CellBalanceFET_S1M2C13 m11 : 29|1@1+ (1,0) [0|0] "" Vector__XXX
 SG_ CellBalanceFET_S1M2C12 m10 : 61|1@1+ (1,0) [0|0] "" Vector__XXX
 SG_ CellBalanceFET_S1M2C11 m10 : 45|1@1+ (1,0) [0|0] "" Vector__XXX
 SG_ CellBalanceFET_S1M2C10 m10 : 29|1@1+ (1,0) [0|0] "" Vector__XXX
 SG_ CellBalanceFET_S1M2C09 m9 : 61|1@1+ (1,0) [0|0] "" Vector__XXX
 SG_ CellBalanceFET_S1M2C08 m9 : 45|1@1+ (1,0) [0|0] "" Vector__XXX
 SG_ CellBalanceFET_S1M2C07 m9 : 29|1@1+ (1,0) [0|0] "" Vector__XXX
 SG_ CellBalanceFET_S1M2C06 m8 : 61|1@1+ (1,0) [0|0] "" Vector__XXX
 SG_ CellBalanceFET_S1M2C05 m8 : 45|1@1+ (1,0) [0|0] "" Vector__XXX
 SG_ CellBalanceFET_S1M2C04 m8 : 29|1@1+ (1,0) [0|0] "" Vector__XXX
 SG_ CellBalanceFET_S1M2C03 m7 : 61|1@1+ (1,0) [0|0] "" Vector__XXX
 SG_ CellBalanceFET_S1M2C02 m7 : 45|1@1+ (1,0) [0|0] "" Vector__XXX
 SG_ CellBalanceFET_S1M2C01 m7 : 29|1@1+ (1,0) [0|0] "" Vector__XXX
 SG_ CellBalanceFET_S1M1C18 m6 : 61|1@1+ (1,0) [0|0] "" Vector__XXX
 SG_ CellBalanceFET_S1M1C17 m6 : 45|1@1+ (1,0) [0|0] "" Vector__XXX
 SG_ CellBalanceFET_S1M1C16 m6 : 29|1@1+ (1,0) [0|0] "" Vector__XXX
 SG_ CellBalanceFET_S1M1C15 m5 : 61|1@1+ (1,0) [0|0] "" Vector__XXX
 SG_ CellBalanceFET_S1M1C14 m5 : 45|1@1+ (1,0) [0|0] "" Vector__XXX
 SG_ CellBalanceFET_S1M1C13 m5 : 29|1@1+ (1,0) [0|0] "" Vector__XXX
 SG_ CellBalanceFET_S1M1C12 m4 : 61|1@1+ (1,0) [0|0] "" Vector__XXX
 SG_ CellBalanceFET_S1M1C11 m4 : 45|1@1+ (1,0) [0|0] "" Vector__XXX
 SG_ CellBalanceFET_S1M1C10 m4 : 29|1@1+ (1,0) [0|0] "" Vector__XXX
 SG_ CellBalanceFET_S1M1C09 m3 : 61|1@1+ (1,0) [0|0] "" Vector__XXX
 SG_ CellBalanceFET_S1M1C08 m3 : 45|1@1+ (1,0) [0|0] "" Vector__XXX
 SG_ CellBalanceFET_S1M1C07 m3 : 29|1@1+ (1,0) [0|0] "" Vector__XXX
 SG_ CellBalanceFET_S1M1C06 m2 : 61|1@1+ (1,0) [0|0] "" Vector__XXX
 SG_ CellBalanceFET_S1M1C05 m2 : 45|1@1+ (1,0) [0|0] "" Vector__XXX
 SG_ CellBalanceFET_S1M1C04 m2 : 29|1@1+ (1,0) [0|0] "" Vector__XXX
 SG_ CellBalanceFET_S1M1C03 m1 : 61|1@1+ (1,0) [0|0] "" Vector__XXX
 SG_ CellBalanceFET_S1M1C02 m1 : 45|1@1+ (1,0) [0|0] "" Vector__XXX
 SG_ CellBalanceFET_S1M1C01 m1 : 29|1@1+ (1,0) [0|0] "" Vector__XXX
 SG_ CellVoltage_S1M5C18 m30 : 48|13@1+ (0.000610426077402027,0) [0|2] "V" Vector__XXX
 SG_ CellVoltage_S1M5C17 m30 : 32|13@1+ (0.000610426077402027,0) [0|2] "V" Vector__XXX
 SG_ CellVoltage_S1M5C16 m30 : 16|13@1+ (0.000610426077402027,0) [0|2] "V" Vector__XXX
 SG_ CellVoltage_S1M5C15 m29 : 48|13@1+ (0.000610426077402027,0) [0|2] "V" Vector__XXX
 SG_ CellVoltage_S1M5C14 m29 : 32|13@1+ (0.000610426077402027,0) [0|2] "V" Vector__XXX
 SG_ CellVoltage_S1M5C13 m29 : 16|13@1+ (0.000610426077402027,0) [0|2] "V" Vector__XXX
 SG_ CellVoltage_S1M5C12 m28 : 48|13@1+ (0.000610426077402027,0) [0|2] "V" Vector__XXX
 SG_ CellVoltage_S1M5C11 m28 : 32|13@1+ (0.000610426077402027,0) [0|2] "V" Vector__XXX
 SG_ CellVoltage_S1M5C10 m28 : 16|13@1+ (0.000610426077402027,0) [0|2] "V" Vector__XXX
 SG_ CellVoltage_S1M5C09 m27 : 48|13@1+ (0.000610426077402027,0) [0|2] "V" Vector__XXX
 SG_ CellVoltage_S1M5C08 m27 : 32|13@1+ (0.000610426077402027,0) [0|2] "V" Vector__XXX
 SG_ CellVoltage_S1M5C07 m27 : 16|13@1+ (0.000610426077402027,0) [0|2] "V" Vector__XXX
 SG_ CellVoltage_S1M5C06 m26 : 48|13@1+ (0.000610426077402027,0) [0|2] "V" Vector__XXX
 SG_ CellVoltage_S1M5C05 m26 : 32|13@1+ (0.000610426077402027,0) [0|2] "V" Vector__XXX
 SG_ CellVoltage_S1M5C04 m26 : 16|13@1+ (0.000610426077402027,0) [0|2] "V" Vector__XXX
 SG_ CellVoltage_S1M5C03 m25 : 48|13@1+ (0.000610426077402027,0) [0|2] "V" Vector__XXX
 SG_ CellVoltage_S1M5C02 m25 : 32|13@1+ (0.000610426077402027,0) [0|2] "V" Vector__XXX
 SG_ CellVoltage_S1M5C01 m25 : 16|13@1+ (0.000610426077402027,0) [0|2] "V" Vector__XXX
 SG_ CellVoltage_S1M4C18 m24 : 48|13@1+ (0.000610426077402027,0) [0|2] "V" Vector__XXX
 SG_ CellVoltage_S1M4C17 m24 : 32|13@1+ (0.000610426077402027,0) [0|2] "V" Vector__XXX
 SG_ CellVoltage_S1M4C16 m24 : 16|13@1+ (0.000610426077402027,0) [0|2] "V" Vector__XXX
 SG_ CellVoltage_S1M4C15 m23 : 48|13@1+ (0.000610426077402027,0) [0|2] "V" Vector__XXX
 SG_ CellVoltage_S1M4C14 m23 : 32|13@1+ (0.000610426077402027,0) [0|2] "V" Vector__XXX
 SG_ CellVoltage_S1M4C13 m23 : 16|13@1+ (0.000610426077402027,0) [0|2] "V" Vector__XXX
 SG_ CellVoltage_S1M4C12 m22 : 48|13@1+ (0.000610426077402027,0) [0|2] "V" Vector__XXX
 SG_ CellVoltage_S1M4C11 m22 : 32|13@1+ (0.000610426077402027,0) [0|2] "V" Vector__XXX
 SG_ CellVoltage_S1M4C10 m22 : 16|13@1+ (0.000610426077402027,0) [0|2] "V" Vector__XXX
 SG_ CellVoltage_S1M4C09 m21 : 48|13@1+ (0.000610426077402027,0) [0|2] "V" Vector__XXX
 SG_ CellVoltage_S1M4C08 m21 : 32|13@1+ (0.000610426077402027,0) [0|2] "V" Vector__XXX
 SG_ CellVoltage_S1M4C07 m21 : 16|13@1+ (0.000610426077402027,0) [0|2] "V" Vector__XXX
 SG_ CellVoltage_S1M4C06 m20 : 48|13@1+ (0.000610426077402027,0) [0|2] "V" Vector__XXX
 SG_ CellVoltage_S1M4C05 m20 : 32|13@1+ (0.000610426077402027,0) [0|2] "V" Vector__XXX
 SG_ CellVoltage_S1M4C04 m20 : 16|13@1+ (0.000610426077402027,0) [0|2] "V" Vector__XXX
 SG_ CellVoltage_S1M4C03 m19 : 48|13@1+ (0.000610426077402027,0) [0|2] "V" Vector__XXX
 SG_ CellVoltage_S1M4C02 m19 : 32|13@1+ (0.000610426077402027,0) [0|2] "V" Vector__XXX
 SG_ CellVoltage_S1M4C01 m19 : 16|13@1+ (0.000610426077402027,0) [0|2] "V" Vector__XXX
 SG_ CellVoltage_S1M3C18 m18 : 48|13@1+ (0.000610426077402027,0) [0|2] "V" Vector__XXX
 SG_ CellVoltage_S1M3C17 m18 : 32|13@1+ (0.000610426077402027,0) [0|2] "V" Vector__XXX
 SG_ CellVoltage_S1M3C16 m18 : 16|13@1+ (0.000610426077402027,0) [0|2] "V" Vector__XXX
 SG_ CellVoltage_S1M3C15 m17 : 48|13@1+ (0.000610426077402027,0) [0|2] "V" Vector__XXX
 SG_ CellVoltage_S1M3C14 m17 : 32|13@1+ (0.000610426077402027,0) [0|2] "V" Vector__XXX
 SG_ CellVoltage_S1M3C13 m17 : 16|13@1+ (0.000610426077402027,0) [0|2] "V" Vector__XXX
 SG_ CellVoltage_S1M3C12 m16 : 48|13@1+ (0.000610426077402027,0) [0|2] "V" Vector__XXX
 SG_ CellVoltage_S1M3C11 m16 : 32|13@1+ (0.000610426077402027,0) [0|2] "V" Vector__XXX
 SG_ CellVoltage_S1M3C10 m16 : 16|13@1+ (0.000610426077402027,0) [0|2] "V" Vector__XXX
 SG_ CellVoltage_S1M3C09 m15 : 48|13@1+ (0.000610426077402027,0) [0|2] "V" Vector__XXX
 SG_ CellVoltage_S1M3C08 m15 : 32|13@1+ (0.000610426077402027,0) [0|2] "V" Vector__XXX
 SG_ CellVoltage_S1M3C07 m15 : 16|13@1+ (0.000610426077402027,0) [0|2] "V" Vector__XXX
 SG_ CellVoltage_S1M3C06 m14 : 48|13@1+ (0.000610426077402027,0) [0|2] "V" Vector__XXX
 SG_ CellVoltage_S1M3C05 m14 : 32|13@1+ (0.000610426077402027,0) [0|2] "V" Vector__XXX
 SG_ CellVoltage_S1M3C04 m14 : 16|13@1+ (0.000610426077402027,0) [0|2] "V" Vector__XXX
 SG_ CellVoltage_S1M3C03 m13 : 48|13@1+ (0.000610426077402027,0) [0|2] "V" Vector__XXX
 SG_ CellVoltage_S1M3C02 m13 : 32|13@1+ (0.000610426077402027,0) [0|2] "V" Vector__XXX
 SG_ CellVoltage_S1M3C01 m13 : 16|13@1+ (0.000610426077402027,0) [0|2] "V" Vector__XXX
 SG_ CellVoltage_S1M2C18 m12 : 48|13@1+ (0.000610426077402027,0) [0|2] "V" Vector__XXX
 SG_ CellVoltage_S1M2C17 m12 : 32|13@1+ (0.000610426077402027,0) [0|2] "V" Vector__XXX
 SG_ CellVoltage_S1M2C16 m12 : 16|13@1+ (0.000610426077402027,0) [0|2] "V" Vector__XXX
 SG_ CellVoltage_S1M2C15 m11 : 48|13@1+ (0.000610426077402027,0) [0|2] "V" Vector__XXX
 SG_ CellVoltage_S1M2C14 m11 : 32|13@1+ (0.000610426077402027,0) [0|2] "V" Vector__XXX
 SG_ CellVoltage_S1M2C13 m11 : 16|13@1+ (0.000610426077402027,0) [0|2] "V" Vector__XXX
 SG_ CellVoltage_S1M2C12 m10 : 48|13@1+ (0.000610426077402027,0) [0|2] "V" Vector__XXX
 SG_ CellVoltage_S1M2C11 m10 : 32|13@1+ (0.000610426077402027,0) [0|2] "V" Vector__XXX
 SG_ CellVoltage_S1M2C10 m10 : 16|13@1+ (0.000610426077402027,0) [0|2] "V" Vector__XXX
 SG_ CellVoltage_S1M2C09 m9 : 48|13@1+ (0.000610426077402027,0) [0|2] "V" Vector__XXX
 SG_ CellVoltage_S1M2C08 m9 : 32|13@1+ (0.000610426077402027,0) [0|2] "V" Vector__XXX
 SG_ CellVoltage_S1M2C07 m9 : 16|13@1+ (0.000610426077402027,0) [0|2] "V" Vector__XXX
 SG_ CellVoltage_S1M2C06 m8 : 48|13@1+ (0.000610426077402027,0) [0|2] "V" Vector__XXX
 SG_ CellVoltage_S1M2C05 m8 : 32|13@1+ (0.000610426077402027,0) [0|2] "V" Vector__XXX
 SG_ CellVoltage_S1M2C04 m8 : 16|13@1+ (0.000610426077402027,0) [0|2] "V" Vector__XXX
 SG_ CellVoltage_S1M2C03 m7 : 48|13@1+ (0.000610426077402027,0) [0|2] "V" Vector__XXX
 SG_ CellVoltage_S1M2C02 m7 : 32|13@1+ (0.000610426077402027,0) [0|2] "V" Vector__XXX
 SG_ CellVoltage_S1M2C01 m7 : 16|13@1+ (0.000610426077402027,0) [0|2] "V" Vector__XXX
 SG_ CellVoltage_S1M1C18 m6 : 48|13@1+ (0.000610426077402027,0) [0|2] "V" Vector__XXX
 SG_ CellVoltage_S1M1C17 m6 : 32|13@1+ (0.000610426077402027,0) [0|2] "V" Vector__XXX
 SG_ CellVoltage_S1M1C16 m6 : 16|13@1+ (0.000610426077402027,0) [0|2] "V" Vector__XXX
 SG_ CellVoltage_S1M1C15 m5 : 48|13@1+ (0.000610426077402027,0) [0|2] "V" Vector__XXX
 SG_ CellVoltage_S1M1C14 m5 : 32|13@1+ (0.000610426077402027,0) [0|2] "V" Vector__XXX
 SG_ CellVoltage_S1M1C13 m5 : 16|13@1+ (0.000610426077402027,0) [0|2] "V" Vector__XXX
 SG_ CellVoltage_S1M1C12 m4 : 48|13@1+ (0.000610426077402027,0) [0|2] "V" Vector__XXX
 SG_ CellVoltage_S1M1C11 m4 : 32|13@1+ (0.000610426077402027,0) [0|2] "V" Vector__XXX
 SG_ CellVoltage_S1M1C10 m4 : 16|13@1+ (0.000610426077402027,0) [0|2] "V" Vector__XXX
 SG_ CellVoltage_S1M1C09 m3 : 48|13@1+ (0.000610426077402027,0) [0|2] "V" Vector__XXX
 SG_ CellVoltage_S1M1C08 m3 : 32|13@1+ (0.000610426077402027,0) [0|2] "V" Vector__XXX
 SG_ CellVoltage_S1M1C07 m3 : 16|13@1+ (0.000610426077402027,0) [0|2] "V" Vector__XXX
 SG_ CellVoltage_S1M1C06 m2 : 48|13@1+ (0.000610426077402027,0) [0|2] "V" Vector__XXX
 SG_ CellVoltage_S1M1C05 m2 : 32|13@1+ (0.000610426077402027,0) [0|2] "V" Vector__XXX
 SG_ CellVoltage_S1M1C04 m2 : 16|13@1+ (0.000610426077402027,0) [0|2] "V" Vector__XXX
 SG_ CellVoltage_S1M1C03 m1 : 48|13@1+ (0.000610426077402027,0) [0|2] "V" Vector__XXX
 SG_ CellVoltage_S1M1C02 m1 : 32|13@1+ (0.000610426077402027,0) [0|2] "V" Vector__XXX
 SG_ CellVoltage_S1M1C01 m1 : 16|13@1+ (0.000610426077402027,0) [0|2] "V" Vector__XXX
 SG_ CellTemp_S1M5TE m30 : 8|8@1+ (0.5,-40) [-40|87.5] "degC" Vector__XXX
 SG_ CellTemp_S1M5TD m29 : 8|8@1+ (0.5,-40) [-40|87.5] "degC" Vector__XXX
 SG_ CellTemp_S1M5TC m28 : 8|8@1+ (0.5,-40) [-40|87.5] "degC" Vector__XXX
 SG_ CellTemp_S1M5TB m26 : 8|8@1+ (0.5,-40) [-40|87.5] "degC" Vector__XXX
 SG_ CellTemp_S1M5TA m25 : 8|8@1+ (0.5,-40) [-40|87.5] "degC" Vector__XXX
 SG_ CellTemp_S1M4TE m24 : 8|8@1+ (0.5,-40) [-40|87.5] "degC" Vector__XXX
 SG_ CellTemp_S1M4TD m23 : 8|8@1+ (0.5,-40) [-40|87.5] "degC" Vector__XXX
 SG_ CellTemp_S1M4TC m22 : 8|8@1+ (0.5,-40) [-40|87.5] "degC" Vector__XXX
 SG_ CellTemp_S1M4TB m20 : 8|8@1+ (0.5,-40) [-40|87.5] "degC" Vector__XXX
 SG_ CellTemp_S1M4TA m19 : 8|8@1+ (0.5,-40) [-40|87.5] "degC" Vector__XXX
 SG_ CellTemp_S1M3TE m18 : 8|8@1+ (0.5,-40) [-40|87.5] "degC" Vector__XXX
 SG_ CellTemp_S1M3TD m17 : 8|8@1+ (0.5,-40) [-40|87.5] "degC" Vector__XXX
 SG_ CellTemp_S1M3TC m16 : 8|8@1+ (0.5,-40) [-40|87.5] "degC" Vector__XXX
 SG_ CellTemp_S1M3TB m14 : 8|8@1+ (0.5,-40) [-40|87.5] "degC" Vector__XXX
 SG_ CellTemp_S1M3TA m13 : 8|8@1+ (0.5,-40) [-40|87.5] "degC" Vector__XXX
 SG_ CellTemp_S1M2TE m12 : 8|8@1+ (0.5,-40) [-40|87.5] "degC" Vector__XXX
 SG_ CellTemp_S1M2TD m11 : 8|8@1+ (0.5,-40) [-40|87.5] "degC" Vector__XXX
 SG_ CellTemp_S1M2TC m10 : 8|8@1+ (0.5,-40) [-40|87.5] "degC" Vector__XXX
 SG_ CellTemp_S1M2TB m8 : 8|8@1+ (0.5,-40) [-40|87.5] "degC" Vector__XXX
 SG_ CellTemp_S1M2TA m7 : 8|8@1+ (0.5,-40) [-40|87.5] "degC" Vector__XXX
 SG_ CellTemp_S1M1TE m6 : 8|8@1+ (0.5,-40) [-40|87.5] "degC" Vector__XXX
 SG_ CellTemp_S1M1TD m5 : 8|8@1+ (0.5,-40) [-40|87.5] "degC" Vector__XXX
 SG_ CellTemp_S1M1TC m4 : 8|8@1+ (0.5,-40) [-40|87.5] "degC" Vector__XXX
 SG_ CellTemp_S1M1TB m2 : 8|8@1+ (0.5,-40) [-40|87.5] "degC" Vector__XXX
 SG_ CellTemp_S1M1TA m1 : 8|8@1+ (0.5,-40) [-40|87.5] "degC" Vector__XXX
 SG_ CellMultiplexor M : 0|6@1+ (1,0) [0|42] "" Vector__XXX

BO_ 1013 Cell_Details_Shelf5: 8 Shelf5
 SG_ CellFault_OverTemp_S1M5TE m29 : 7|1@1+ (1,0) [0|0] "" Vector__XXX
 SG_ CellFault_OverTemp_S1M5TD m28 : 7|1@1+ (1,0) [0|0] "" Vector__XXX
 SG_ CellFault_OverTemp_S1M5TC m27 : 7|1@1+ (1,0) [0|0] "" Vector__XXX
 SG_ CellFault_OverTemp_S1M5TB m26 : 7|1@1+ (1,0) [0|0] "" Vector__XXX
 SG_ CellFault_OverTemp_S1M5TA m25 : 7|1@1+ (1,0) [0|0] "" Vector__XXX
 SG_ CellFault_OverTemp_S1M4TE m23 : 7|1@1+ (1,0) [0|0] "" Vector__XXX
 SG_ CellFault_OverTemp_S1M4TD m22 : 7|1@1+ (1,0) [0|0] "" Vector__XXX
 SG_ CellFault_OverTemp_S1M4TC m21 : 7|1@1+ (1,0) [0|0] "" Vector__XXX
 SG_ CellFault_OverTemp_S1M4TB m20 : 7|1@1+ (1,0) [0|0] "" Vector__XXX
 SG_ CellFault_OverTemp_S1M4TA m19 : 7|1@1+ (1,0) [0|0] "" Vector__XXX
 SG_ CellFault_OverTemp_S1M3TE m17 : 7|1@1+ (1,0) [0|0] "" Vector__XXX
 SG_ CellFault_OverTemp_S1M3TD m16 : 7|1@1+ (1,0) [0|0] "" Vector__XXX
 SG_ CellFault_OverTemp_S1M3TC m15 : 7|1@1+ (1,0) [0|0] "" Vector__XXX
 SG_ CellFault_OverTemp_S1M3TB m14 : 7|1@1+ (1,0) [0|0] "" Vector__XXX
 SG_ CellFault_OverTemp_S1M3TA m13 : 7|1@1+ (1,0) [0|0] "" Vector__XXX
 SG_ CellFault_OverTemp_S1M2TE m11 : 7|1@1+ (1,0) [0|0] "" Vector__XXX
 SG_ CellFault_OverTemp_S1M2TD m10 : 7|1@1+ (1,0) [0|0] "" Vector__XXX
 SG_ CellFault_OverTemp_S1M2TC m9 : 7|1@1+ (1,0) [0|0] "" Vector__XXX
 SG_ CellFault_OverTemp_S1M2TB m8 : 7|1@1+ (1,0) [0|0] "" Vector__XXX
 SG_ CellFault_OverTemp_S1M2TA m7 : 7|1@1+ (1,0) [0|0] "" Vector__XXX
 SG_ CellFault_OverTemp_S1M1TE m6 : 7|1@1+ (1,0) [0|0] "" Vector__XXX
 SG_ CellFault_OverTemp_S1M1TD m5 : 7|1@1+ (1,0) [0|0] "" Vector__XXX
 SG_ CellFault_OverTemp_S1M1TC m4 : 7|1@1+ (1,0) [0|0] "" Vector__XXX
 SG_ CellFault_OverTemp_S1M1TB m2 : 7|1@1+ (1,0) [0|0] "" Vector__XXX
 SG_ CellFault_OverTemp_S1M1TA m1 : 7|1@1+ (1,0) [0|0] "" Vector__XXX
 SG_ CellFault_Wire_S1M5C18 m30 : 62|1@1+ (1,0) [0|0] "" Vector__XXX
 SG_ CellFault_Wire_S1M5C17 m30 : 46|1@1+ (1,0) [0|0] "" Vector__XXX
 SG_ CellFault_Wire_S1M5C16 m30 : 30|1@1+ (1,0) [0|0] "" Vector__XXX
 SG_ CellFault_Wire_S1M5C15 m29 : 62|1@1+ (1,0) [0|0] "" Vector__XXX
 SG_ CellFault_Wire_S1M5C14 m29 : 46|1@1+ (1,0) [0|0] "" Vector__XXX
 SG_ CellFault_Wire_S1M5C13 m29 : 30|1@1+ (1,0) [0|0] "" Vector__XXX
 SG_ CellFault_Wire_S1M5C12 m28 : 62|1@1+ (1,0) [0|0] "" Vector__XXX
 SG_ CellFault_Wire_S1M5C11 m28 : 46|1@1+ (1,0) [0|0] "" Vector__XXX
 SG_ CellFault_Wire_S1M5C10 m28 : 30|1@1+ (1,0) [0|0] "" Vector__XXX
 SG_ CellFault_Wire_S1M5C09 m27 : 62|1@1+ (1,0) [0|0] "" Vector__XXX
 SG_ CellFault_Wire_S1M5C08 m27 : 46|1@1+ (1,0) [0|0] "" Vector__XXX
 SG_ CellFault_Wire_S1M5C07 m27 : 30|1@1+ (1,0) [0|0] "" Vector__XXX
 SG_ CellFault_Wire_S1M5C06 m26 : 62|1@1+ (1,0) [0|0] "" Vector__XXX
 SG_ CellFault_Wire_S1M5C05 m26 : 46|1@1+ (1,0) [0|0] "" Vector__XXX
 SG_ CellFault_Wire_S1M5C04 m26 : 30|1@1+ (1,0) [0|0] "" Vector__XXX
 SG_ CellFault_Wire_S1M5C03 m25 : 62|1@1+ (1,0) [0|0] "" Vector__XXX
 SG_ CellFault_Wire_S1M5C02 m25 : 46|1@1+ (1,0) [0|0] "" Vector__XXX
 SG_ CellFault_Wire_S1M5C01 m25 : 30|1@1+ (1,0) [0|0] "" Vector__XXX
 SG_ CellFault_Wire_S1M4C18 m24 : 62|1@1+ (1,0) [0|0] "" Vector__XXX
 SG_ CellFault_Wire_S1M4C17 m24 : 46|1@1+ (1,0) [0|0] "" Vector__XXX
 SG_ CellFault_Wire_S1M4C16 m24 : 30|1@1+ (1,0) [0|0] "" Vector__XXX
 SG_ CellFault_Wire_S1M4C15 m23 : 62|1@1+ (1,0) [0|0] "" Vector__XXX
 SG_ CellFault_Wire_S1M4C14 m23 : 46|1@1+ (1,0) [0|0] "" Vector__XXX
 SG_ CellFault_Wire_S1M4C13 m23 : 30|1@1+ (1,0) [0|0] "" Vector__XXX
 SG_ CellFault_Wire_S1M4C12 m22 : 62|1@1+ (1,0) [0|0] "" Vector__XXX
 SG_ CellFault_Wire_S1M4C11 m22 : 46|1@1+ (1,0) [0|0] "" Vector__XXX
 SG_ CellFault_Wire_S1M4C10 m22 : 30|1@1+ (1,0) [0|0] "" Vector__XXX
 SG_ CellFault_Wire_S1M4C09 m21 : 62|1@1+ (1,0) [0|0] "" Vector__XXX
 SG_ CellFault_Wire_S1M4C08 m21 : 46|1@1+ (1,0) [0|0] "" Vector__XXX
 SG_ CellFault_Wire_S1M4C07 m21 : 30|1@1+ (1,0) [0|0] "" Vector__XXX
 SG_ CellFault_Wire_S1M4C06 m20 : 62|1@1+ (1,0) [0|0] "" Vector__XXX
 SG_ CellFault_Wire_S1M4C05 m20 : 46|1@1+ (1,0) [0|0] "" Vector__XXX
 SG_ CellFault_Wire_S1M4C04 m20 : 30|1@1+ (1,0) [0|0] "" Vector__XXX
 SG_ CellFault_Wire_S1M4C03 m19 : 62|1@1+ (1,0) [0|0] "" Vector__XXX
 SG_ CellFault_Wire_S1M4C02 m19 : 46|1@1+ (1,0) [0|0] "" Vector__XXX
 SG_ CellFault_Wire_S1M4C01 m19 : 30|1@1+ (1,0) [0|0] "" Vector__XXX
 SG_ CellFault_Wire_S1M3C18 m18 : 62|1@1+ (1,0) [0|0] "" Vector__XXX
 SG_ CellFault_Wire_S1M3C17 m18 : 46|1@1+ (1,0) [0|0] "" Vector__XXX
 SG_ CellFault_Wire_S1M3C16 m18 : 30|1@1+ (1,0) [0|0] "" Vector__XXX
 SG_ CellFault_Wire_S1M3C15 m17 : 62|1@1+ (1,0) [0|0] "" Vector__XXX
 SG_ CellFault_Wire_S1M3C14 m17 : 46|1@1+ (1,0) [0|0] "" Vector__XXX
 SG_ CellFault_Wire_S1M3C13 m17 : 30|1@1+ (1,0) [0|0] "" Vector__XXX
 SG_ CellFault_Wire_S1M3C12 m16 : 62|1@1+ (1,0) [0|0] "" Vector__XXX
 SG_ CellFault_Wire_S1M3C11 m16 : 46|1@1+ (1,0) [0|0] "" Vector__XXX
 SG_ CellFault_Wire_S1M3C10 m16 : 30|1@1+ (1,0) [0|0] "" Vector__XXX
 SG_ CellFault_Wire_S1M3C09 m15 : 62|1@1+ (1,0) [0|0] "" Vector__XXX
 SG_ CellFault_Wire_S1M3C08 m15 : 46|1@1+ (1,0) [0|0] "" Vector__XXX
 SG_ CellFault_Wire_S1M3C07 m15 : 30|1@1+ (1,0) [0|0] "" Vector__XXX
 SG_ CellFault_Wire_S1M3C06 m14 : 62|1@1+ (1,0) [0|0] "" Vector__XXX
 SG_ CellFault_Wire_S1M3C05 m14 : 46|1@1+ (1,0) [0|0] "" Vector__XXX
 SG_ CellFault_Wire_S1M3C04 m14 : 30|1@1+ (1,0) [0|0] "" Vector__XXX
 SG_ CellFault_Wire_S1M3C03 m13 : 62|1@1+ (1,0) [0|0] "" Vector__XXX
 SG_ CellFault_Wire_S1M3C02 m13 : 46|1@1+ (1,0) [0|0] "" Vector__XXX
 SG_ CellFault_Wire_S1M3C01 m13 : 30|1@1+ (1,0) [0|0] "" Vector__XXX
 SG_ CellFault_Wire_S1M2C18 m12 : 62|1@1+ (1,0) [0|0] "" Vector__XXX
 SG_ CellFault_Wire_S1M2C17 m12 : 46|1@1+ (1,0) [0|0] "" Vector__XXX
 SG_ CellFault_Wire_S1M2C16 m12 : 30|1@1+ (1,0) [0|0] "" Vector__XXX
 SG_ CellFault_Wire_S1M2C15 m11 : 62|1@1+ (1,0) [0|0] "" Vector__XXX
 SG_ CellFault_Wire_S1M2C14 m11 : 46|1@1+ (1,0) [0|0] "" Vector__XXX
 SG_ CellFault_Wire_S1M2C13 m11 : 30|1@1+ (1,0) [0|0] "" Vector__XXX
 SG_ CellFault_Wire_S1M2C12 m10 : 62|1@1+ (1,0) [0|0] "" Vector__XXX
 SG_ CellFault_Wire_S1M2C11 m10 : 46|1@1+ (1,0) [0|0] "" Vector__XXX
 SG_ CellFault_Wire_S1M2C10 m10 : 30|1@1+ (1,0) [0|0] "" Vector__XXX
 SG_ CellFault_Wire_S1M2C09 m9 : 62|1@1+ (1,0) [0|0] "" Vector__XXX
 SG_ CellFault_Wire_S1M2C08 m9 : 46|1@1+ (1,0) [0|0] "" Vector__XXX
 SG_ CellFault_Wire_S1M2C07 m9 : 30|1@1+ (1,0) [0|0] "" Vector__XXX
 SG_ CellFault_Wire_S1M2C06 m8 : 62|1@1+ (1,0) [0|0] "" Vector__XXX
 SG_ CellFault_Wire_S1M2C05 m8 : 46|1@1+ (1,0) [0|0] "" Vector__XXX
 SG_ CellFault_Wire_S1M2C04 m8 : 30|1@1+ (1,0) [0|0] "" Vector__XXX
 SG_ CellFault_Wire_S1M2C03 m7 : 62|1@1+ (1,0) [0|0] "" Vector__XXX
 SG_ CellFault_Wire_S1M2C02 m7 : 46|1@1+ (1,0) [0|0] "" Vector__XXX
 SG_ CellFault_Wire_S1M2C01 m7 : 30|1@1+ (1,0) [0|0] "" Vector__XXX
 SG_ CellFault_Wire_S1M1C18 m6 : 62|1@1+ (1,0) [0|0] "" Vector__XXX
 SG_ CellFault_Wire_S1M1C17 m6 : 46|1@1+ (1,0) [0|0] "" Vector__XXX
 SG_ CellFault_Wire_S1M1C16 m6 : 30|1@1+ (1,0) [0|0] "" Vector__XXX
 SG_ CellFault_Wire_S1M1C15 m5 : 62|1@1+ (1,0) [0|0] "" Vector__XXX
 SG_ CellFault_Wire_S1M1C14 m5 : 46|1@1+ (1,0) [0|0] "" Vector__XXX
 SG_ CellFault_Wire_S1M1C13 m5 : 30|1@1+ (1,0) [0|0] "" Vector__XXX
 SG_ CellFault_Wire_S1M1C12 m4 : 62|1@1+ (1,0) [0|0] "" Vector__XXX
 SG_ CellFault_Wire_S1M1C11 m4 : 46|1@1+ (1,0) [0|0] "" Vector__XXX
 SG_ CellFault_Wire_S1M1C10 m4 : 30|1@1+ (1,0) [0|0] "" Vector__XXX
 SG_ CellFault_Wire_S1M1C09 m3 : 62|1@1+ (1,0) [0|0] "" Vector__XXX
 SG_ CellFault_Wire_S1M1C08 m3 : 46|1@1+ (1,0) [0|0] "" Vector__XXX
 SG_ CellFault_Wire_S1M1C07 m3 : 30|1@1+ (1,0) [0|0] "" Vector__XXX
 SG_ CellFault_Wire_S1M1C06 m2 : 62|1@1+ (1,0) [0|0] "" Vector__XXX
 SG_ CellFault_Wire_S1M1C05 m2 : 46|1@1+ (1,0) [0|0] "" Vector__XXX
 SG_ CellFault_Wire_S1M1C04 m2 : 30|1@1+ (1,0) [0|0] "" Vector__XXX
 SG_ CellFault_Wire_S1M1C03 m1 : 62|1@1+ (1,0) [0|0] "" Vector__XXX
 SG_ CellFault_Wire_S1M1C02 m1 : 46|1@1+ (1,0) [0|0] "" Vector__XXX
 SG_ CellFault_Wire_S1M1C01 m1 : 30|1@1+ (1,0) [0|0] "" Vector__XXX
 SG_ CellFault_Voltage_S1M5C18 m30 : 63|1@1+ (1,0) [0|0] "" Vector__XXX
 SG_ CellFault_Voltage_S1M5C17 m30 : 47|1@1+ (1,0) [0|0] "" Vector__XXX
 SG_ CellFault_Voltage_S1M5C16 m30 : 31|1@1+ (1,0) [0|0] "" Vector__XXX
 SG_ CellFault_Voltage_S1M5C15 m29 : 63|1@1+ (1,0) [0|0] "" Vector__XXX
 SG_ CellFault_Voltage_S1M5C14 m29 : 47|1@1+ (1,0) [0|0] "" Vector__XXX
 SG_ CellFault_Voltage_S1M5C13 m29 : 31|1@1+ (1,0) [0|0] "" Vector__XXX
 SG_ CellFault_Voltage_S1M5C12 m28 : 63|1@1+ (1,0) [0|0] "" Vector__XXX
 SG_ CellFault_Voltage_S1M5C11 m28 : 47|1@1+ (1,0) [0|0] "" Vector__XXX
 SG_ CellFault_Voltage_S1M5C10 m28 : 31|1@1+ (1,0) [0|0] "" Vector__XXX
 SG_ CellFault_Voltage_S1M5C09 m27 : 63|1@1+ (1,0) [0|0] "" Vector__XXX
 SG_ CellFault_Voltage_S1M5C08 m27 : 47|1@1+ (1,0) [0|0] "" Vector__XXX
 SG_ CellFault_Voltage_S1M5C07 m27 : 31|1@1+ (1,0) [0|0] "" Vector__XXX
 SG_ CellFault_Voltage_S1M5C06 m26 : 63|1@1+ (1,0) [0|0] "" Vector__XXX
 SG_ CellFault_Voltage_S1M5C05 m26 : 47|1@1+ (1,0) [0|0] "" Vector__XXX
 SG_ CellFault_Voltage_S1M5C04 m26 : 31|1@1+ (1,0) [0|0] "" Vector__XXX
 SG_ CellFault_Voltage_S1M5C03 m25 : 63|1@1+ (1,0) [0|0] "" Vector__XXX
 SG_ CellFault_Voltage_S1M5C02 m25 : 47|1@1+ (1,0) [0|0] "" Vector__XXX
 SG_ CellFault_Voltage_S1M5C01 m25 : 31|1@1+ (1,0) [0|0] "" Vector__XXX
 SG_ CellFault_Voltage_S1M4C18 m24 : 63|1@1+ (1,0) [0|0] "" Vector__XXX
 SG_ CellFault_Voltage_S1M4C17 m24 : 47|1@1+ (1,0) [0|0] "" Vector__XXX
 SG_ CellFault_Voltage_S1M4C16 m24 : 31|1@1+ (1,0) [0|0] "" Vector__XXX
 SG_ CellFault_Voltage_S1M4C15 m23 : 63|1@1+ (1,0) [0|0] "" Vector__XXX
 SG_ CellFault_Voltage_S1M4C14 m23 : 47|1@1+ (1,0) [0|0] "" Vector__XXX
 SG_ CellFault_Voltage_S1M4C13 m23 : 31|1@1+ (1,0) [0|0] "" Vector__XXX
 SG_ CellFault_Voltage_S1M4C12 m22 : 63|1@1+ (1,0) [0|0] "" Vector__XXX
 SG_ CellFault_Voltage_S1M4C11 m22 : 47|1@1+ (1,0) [0|0] "" Vector__XXX
 SG_ CellFault_Voltage_S1M4C10 m22 : 31|1@1+ (1,0) [0|0] "" Vector__XXX
 SG_ CellFault_Voltage_S1M4C09 m21 : 63|1@1+ (1,0) [0|0] "" Vector__XXX
 SG_ CellFault_Voltage_S1M4C08 m21 : 47|1@1+ (1,0) [0|0] "" Vector__XXX
 SG_ CellFault_Voltage_S1M4C07 m21 : 31|1@1+ (1,0) [0|0] "" Vector__XXX
 SG_ CellFault_Voltage_S1M4C06 m20 : 63|1@1+ (1,0) [0|0] "" Vector__XXX
 SG_ CellFault_Voltage_S1M4C05 m20 : 47|1@1+ (1,0) [0|0] "" Vector__XXX
 SG_ CellFault_Voltage_S1M4C04 m20 : 31|1@1+ (1,0) [0|0] "" Vector__XXX
 SG_ CellFault_Voltage_S1M4C03 m19 : 63|1@1+ (1,0) [0|0] "" Vector__XXX
 SG_ CellFault_Voltage_S1M4C02 m19 : 47|1@1+ (1,0) [0|0] "" Vector__XXX
 SG_ CellFault_Voltage_S1M4C01 m19 : 31|1@1+ (1,0) [0|0] "" Vector__XXX
 SG_ CellFault_Voltage_S1M3C18 m18 : 63|1@1+ (1,0) [0|0] "" Vector__XXX
 SG_ CellFault_Voltage_S1M3C17 m18 : 47|1@1+ (1,0) [0|0] "" Vector__XXX
 SG_ CellFault_Voltage_S1M3C16 m18 : 31|1@1+ (1,0) [0|0] "" Vector__XXX
 SG_ CellFault_Voltage_S1M3C15 m17 : 63|1@1+ (1,0) [0|0] "" Vector__XXX
 SG_ CellFault_Voltage_S1M3C14 m17 : 47|1@1+ (1,0) [0|0] "" Vector__XXX
 SG_ CellFault_Voltage_S1M3C13 m17 : 31|1@1+ (1,0) [0|0] "" Vector__XXX
 SG_ CellFault_Voltage_S1M3C12 m16 : 63|1@1+ (1,0) [0|0] "" Vector__XXX
 SG_ CellFault_Voltage_S1M3C11 m16 : 47|1@1+ (1,0) [0|0] "" Vector__XXX
 SG_ CellFault_Voltage_S1M3C10 m16 : 31|1@1+ (1,0) [0|0] "" Vector__XXX
 SG_ CellFault_Voltage_S1M3C09 m15 : 63|1@1+ (1,0) [0|0] "" Vector__XXX
 SG_ CellFault_Voltage_S1M3C08 m15 : 47|1@1+ (1,0) [0|0] "" Vector__XXX
 SG_ CellFault_Voltage_S1M3C07 m15 : 31|1@1+ (1,0) [0|0] "" Vector__XXX
 SG_ CellFault_Voltage_S1M3C06 m14 : 63|1@1+ (1,0) [0|0] "" Vector__XXX
 SG_ CellFault_Voltage_S1M3C05 m14 : 47|1@1+ (1,0) [0|0] "" Vector__XXX
 SG_ CellFault_Voltage_S1M3C04 m14 : 31|1@1+ (1,0) [0|0] "" Vector__XXX
 SG_ CellFault_Voltage_S1M3C03 m13 : 63|1@1+ (1,0) [0|0] "" Vector__XXX
 SG_ CellFault_Voltage_S1M3C02 m13 : 47|1@1+ (1,0) [0|0] "" Vector__XXX
 SG_ CellFault_Voltage_S1M3C01 m13 : 31|1@1+ (1,0) [0|0] "" Vector__XXX
 SG_ CellFault_Voltage_S1M2C18 m12 : 63|1@1+ (1,0) [0|0] "" Vector__XXX
 SG_ CellFault_Voltage_S1M2C17 m12 : 47|1@1+ (1,0) [0|0] "" Vector__XXX
 SG_ CellFault_Voltage_S1M2C16 m12 : 31|1@1+ (1,0) [0|0] "" Vector__XXX
 SG_ CellFault_Voltage_S1M2C15 m11 : 63|1@1+ (1,0) [0|0] "" Vector__XXX
 SG_ CellFault_Voltage_S1M2C14 m11 : 47|1@1+ (1,0) [0|0] "" Vector__XXX
 SG_ CellFault_Voltage_S1M2C13 m11 : 31|1@1+ (1,0) [0|0] "" Vector__XXX
 SG_ CellFault_Voltage_S1M2C12 m10 : 63|1@1+ (1,0) [0|0] "" Vector__XXX
 SG_ CellFault_Voltage_S1M2C11 m10 : 47|1@1+ (1,0) [0|0] "" Vector__XXX
 SG_ CellFault_Voltage_S1M2C10 m10 : 31|1@1+ (1,0) [0|0] "" Vector__XXX
 SG_ CellFault_Voltage_S1M2C09 m9 : 63|1@1+ (1,0) [0|0] "" Vector__XXX
 SG_ CellFault_Voltage_S1M2C08 m9 : 47|1@1+ (1,0) [0|0] "" Vector__XXX
 SG_ CellFault_Voltage_S1M2C07 m9 : 31|1@1+ (1,0) [0|0] "" Vector__XXX
 SG_ CellFault_Voltage_S1M2C06 m8 : 63|1@1+ (1,0) [0|0] "" Vector__XXX
 SG_ CellFault_Voltage_S1M2C05 m8 : 47|1@1+ (1,0) [0|0] "" Vector__XXX
 SG_ CellFault_Voltage_S1M2C04 m8 : 31|1@1+ (1,0) [0|0] "" Vector__XXX
 SG_ CellFault_Voltage_S1M2C03 m7 : 63|1@1+ (1,0) [0|0] "" Vector__XXX
 SG_ CellFault_Voltage_S1M2C02 m7 : 47|1@1+ (1,0) [0|0] "" Vector__XXX
 SG_ CellFault_Voltage_S1M2C01 m7 : 31|1@1+ (1,0) [0|0] "" Vector__XXX
 SG_ CellFault_Voltage_S1M1C18 m6 : 63|1@1+ (1,0) [0|0] "" Vector__XXX
 SG_ CellFault_Voltage_S1M1C17 m6 : 47|1@1+ (1,0) [0|0] "" Vector__XXX
 SG_ CellFault_Voltage_S1M1C16 m6 : 31|1@1+ (1,0) [0|0] "" Vector__XXX
 SG_ CellFault_Voltage_S1M1C15 m5 : 63|1@1+ (1,0) [0|0] "" Vector__XXX
 SG_ CellFault_Voltage_S1M1C14 m5 : 47|1@1+ (1,0) [0|0] "" Vector__XXX
 SG_ CellFault_Voltage_S1M1C13 m5 : 31|1@1+ (1,0) [0|0] "" Vector__XXX
 SG_ CellFault_Voltage_S1M1C12 m4 : 63|1@1+ (1,0) [0|0] "" Vector__XXX
 SG_ CellFault_Voltage_S1M1C11 m4 : 47|1@1+ (1,0) [0|0] "" Vector__XXX
 SG_ CellFault_Voltage_S1M1C10 m4 : 31|1@1+ (1,0) [0|0] "" Vector__XXX
 SG_ CellFault_Voltage_S1M1C09 m3 : 63|1@1+ (1,0) [0|0] "" Vector__XXX
 SG_ CellFault_Voltage_S1M1C08 m3 : 47|1@1+ (1,0) [0|0] "" Vector__XXX
 SG_ CellFault_Voltage_S1M1C07 m3 : 31|1@1+ (1,0) [0|0] "" Vector__XXX
 SG_ CellFault_Voltage_S1M1C06 m2 : 63|1@1+ (1,0) [0|0] "" Vector__XXX
 SG_ CellFault_Voltage_S1M1C05 m2 : 47|1@1+ (1,0) [0|0] "" Vector__XXX
 SG_ CellFault_Voltage_S1M1C04 m2 : 31|1@1+ (1,0) [0|0] "" Vector__XXX
 SG_ CellFault_Voltage_S1M1C03 m1 : 63|1@1+ (1,0) [0|0] "" Vector__XXX
 SG_ CellFault_Voltage_S1M1C02 m1 : 47|1@1+ (1,0) [0|0] "" Vector__XXX
 SG_ CellFault_Voltage_S1M1C01 m1 : 31|1@1+ (1,0) [0|0] "" Vector__XXX
 SG_ CellBalanceFET_S1M5C18 m30 : 61|1@1+ (1,0) [0|0] "" Vector__XXX
 SG_ CellBalanceFET_S1M5C17 m30 : 45|1@1+ (1,0) [0|0] "" Vector__XXX
 SG_ CellBalanceFET_S1M5C16 m30 : 29|1@1+ (1,0) [0|0] "" Vector__XXX
 SG_ CellBalanceFET_S1M5C15 m29 : 61|1@1+ (1,0) [0|0] "" Vector__XXX
 SG_ CellBalanceFET_S1M5C14 m29 : 45|1@1+ (1,0) [0|0] "" Vector__XXX
 SG_ CellBalanceFET_S1M5C13 m29 : 29|1@1+ (1,0) [0|0] "" Vector__XXX
 SG_ CellBalanceFET_S1M5C12 m28 : 61|1@1+ (1,0) [0|0] "" Vector__XXX
 SG_ CellBalanceFET_S1M5C11 m28 : 45|1@1+ (1,0) [0|0] "" Vector__XXX
 SG_ CellBalanceFET_S1M5C10 m28 : 29|1@1+ (1,0) [0|0] "" Vector__XXX
 SG_ CellBalanceFET_S1M5C09 m27 : 61|1@1+ (1,0) [0|0] "" Vector__XXX
 SG_ CellBalanceFET_S1M5C08 m27 : 45|1@1+ (1,0) [0|0] "" Vector__XXX
 SG_ CellBalanceFET_S1M5C07 m27 : 29|1@1+ (1,0) [0|0] "" Vector__XXX
 SG_ CellBalanceFET_S1M5C06 m26 : 61|1@1+ (1,0) [0|0] "" Vector__XXX
 SG_ CellBalanceFET_S1M5C05 m26 : 45|1@1+ (1,0) [0|0] "" Vector__XXX
 SG_ CellBalanceFET_S1M5C04 m26 : 29|1@1+ (1,0) [0|0] "" Vector__XXX
 SG_ CellBalanceFET_S1M5C03 m25 : 61|1@1+ (1,0) [0|0] "" Vector__XXX
 SG_ CellBalanceFET_S1M5C02 m25 : 45|1@1+ (1,0) [0|0] "" Vector__XXX
 SG_ CellBalanceFET_S1M5C01 m25 : 29|1@1+ (1,0) [0|0] "" Vector__XXX
 SG_ CellBalanceFET_S1M4C18 m24 : 61|1@1+ (1,0) [0|0] "" Vector__XXX
 SG_ CellBalanceFET_S1M4C17 m24 : 45|1@1+ (1,0) [0|0] "" Vector__XXX
 SG_ CellBalanceFET_S1M4C16 m24 : 29|1@1+ (1,0) [0|0] "" Vector__XXX
 SG_ CellBalanceFET_S1M4C15 m23 : 61|1@1+ (1,0) [0|0] "" Vector__XXX
 SG_ CellBalanceFET_S1M4C14 m23 : 45|1@1+ (1,0) [0|0] "" Vector__XXX
 SG_ CellBalanceFET_S1M4C13 m23 : 29|1@1+ (1,0) [0|0] "" Vector__XXX
 SG_ CellBalanceFET_S1M4C12 m22 : 61|1@1+ (1,0) [0|0] "" Vector__XXX
 SG_ CellBalanceFET_S1M4C11 m22 : 45|1@1+ (1,0) [0|0] "" Vector__XXX
 SG_ CellBalanceFET_S1M4C10 m22 : 29|1@1+ (1,0) [0|0] "" Vector__XXX
 SG_ CellBalanceFET_S1M4C09 m21 : 61|1@1+ (1,0) [0|0] "" Vector__XXX
 SG_ CellBalanceFET_S1M4C08 m21 : 45|1@1+ (1,0) [0|0] "" Vector__XXX
 SG_ CellBalanceFET_S1M4C07 m21 : 29|1@1+ (1,0) [0|0] "" Vector__XXX
 SG_ CellBalanceFET_S1M4C06 m20 : 61|1@1+ (1,0) [0|0] "" Vector__XXX
 SG_ CellBalanceFET_S1M4C05 m20 : 45|1@1+ (1,0) [0|0] "" Vector__XXX
 SG_ CellBalanceFET_S1M4C04 m20 : 29|1@1+ (1,0) [0|0] "" Vector__XXX
 SG_ CellBalanceFET_S1M4C03 m19 : 61|1@1+ (1,0) [0|0] "" Vector__XXX
 SG_ CellBalanceFET_S1M4C02 m19 : 45|1@1+ (1,0) [0|0] "" Vector__XXX
 SG_ CellBalanceFET_S1M4C01 m19 : 29|1@1+ (1,0) [0|0] "" Vector__XXX
 SG_ CellBalanceFET_S1M3C18 m18 : 61|1@1+ (1,0) [0|0] "" Vector__XXX
 SG_ CellBalanceFET_S1M3C17 m18 : 45|1@1+ (1,0) [0|0] "" Vector__XXX
 SG_ CellBalanceFET_S1M3C16 m18 : 29|1@1+ (1,0) [0|0] "" Vector__XXX
 SG_ CellBalanceFET_S1M3C15 m17 : 61|1@1+ (1,0) [0|0] "" Vector__XXX
 SG_ CellBalanceFET_S1M3C14 m17 : 45|1@1+ (1,0) [0|0] "" Vector__XXX
 SG_ CellBalanceFET_S1M3C13 m17 : 29|1@1+ (1,0) [0|0] "" Vector__XXX
 SG_ CellBalanceFET_S1M3C12 m16 : 61|1@1+ (1,0) [0|0] "" Vector__XXX
 SG_ CellBalanceFET_S1M3C11 m16 : 45|1@1+ (1,0) [0|0] "" Vector__XXX
 SG_ CellBalanceFET_S1M3C10 m16 : 29|1@1+ (1,0) [0|0] "" Vector__XXX
 SG_ CellBalanceFET_S1M3C09 m15 : 61|1@1+ (1,0) [0|0] "" Vector__XXX
 SG_ CellBalanceFET_S1M3C08 m15 : 45|1@1+ (1,0) [0|0] "" Vector__XXX
 SG_ CellBalanceFET_S1M3C07 m15 : 29|1@1+ (1,0) [0|0] "" Vector__XXX
 SG_ CellBalanceFET_S1M3C06 m14 : 61|1@1+ (1,0) [0|0] "" Vector__XXX
 SG_ CellBalanceFET_S1M3C05 m14 : 45|1@1+ (1,0) [0|0] "" Vector__XXX
 SG_ CellBalanceFET_S1M3C04 m14 : 29|1@1+ (1,0) [0|0] "" Vector__XXX
 SG_ CellBalanceFET_S1M3C03 m13 : 61|1@1+ (1,0) [0|0] "" Vector__XXX
 SG_ CellBalanceFET_S1M3C02 m13 : 45|1@1+ (1,0) [0|0] "" Vector__XXX
 SG_ CellBalanceFET_S1M3C01 m13 : 29|1@1+ (1,0) [0|0] "" Vector__XXX
 SG_ CellBalanceFET_S1M2C18 m12 : 61|1@1+ (1,0) [0|0] "" Vector__XXX
 SG_ CellBalanceFET_S1M2C17 m12 : 45|1@1+ (1,0) [0|0] "" Vector__XXX
 SG_ CellBalanceFET_S1M2C16 m12 : 29|1@1+ (1,0) [0|0] "" Vector__XXX
 SG_ CellBalanceFET_S1M2C15 m11 : 61|1@1+ (1,0) [0|0] "" Vector__XXX
 SG_ CellBalanceFET_S1M2C14 m11 : 45|1@1+ (1,0) [0|0] "" Vector__XXX
 SG_ CellBalanceFET_S1M2C13 m11 : 29|1@1+ (1,0) [0|0] "" Vector__XXX
 SG_ CellBalanceFET_S1M2C12 m10 : 61|1@1+ (1,0) [0|0] "" Vector__XXX
 SG_ CellBalanceFET_S1M2C11 m10 : 45|1@1+ (1,0) [0|0] "" Vector__XXX
 SG_ CellBalanceFET_S1M2C10 m10 : 29|1@1+ (1,0) [0|0] "" Vector__XXX
 SG_ CellBalanceFET_S1M2C09 m9 : 61|1@1+ (1,0) [0|0] "" Vector__XXX
 SG_ CellBalanceFET_S1M2C08 m9 : 45|1@1+ (1,0) [0|0] "" Vector__XXX
 SG_ CellBalanceFET_S1M2C07 m9 : 29|1@1+ (1,0) [0|0] "" Vector__XXX
 SG_ CellBalanceFET_S1M2C06 m8 : 61|1@1+ (1,0) [0|0] "" Vector__XXX
 SG_ CellBalanceFET_S1M2C05 m8 : 45|1@1+ (1,0) [0|0] "" Vector__XXX
 SG_ CellBalanceFET_S1M2C04 m8 : 29|1@1+ (1,0) [0|0] "" Vector__XXX
 SG_ CellBalanceFET_S1M2C03 m7 : 61|1@1+ (1,0) [0|0] "" Vector__XXX
 SG_ CellBalanceFET_S1M2C02 m7 : 45|1@1+ (1,0) [0|0] "" Vector__XXX
 SG_ CellBalanceFET_S1M2C01 m7 : 29|1@1+ (1,0) [0|0] "" Vector__XXX
 SG_ CellBalanceFET_S1M1C18 m6 : 61|1@1+ (1,0) [0|0] "" Vector__XXX
 SG_ CellBalanceFET_S1M1C17 m6 : 45|1@1+ (1,0) [0|0] "" Vector__XXX
 SG_ CellBalanceFET_S1M1C16 m6 : 29|1@1+ (1,0) [0|0] "" Vector__XXX
 SG_ CellBalanceFET_S1M1C15 m5 : 61|1@1+ (1,0) [0|0] "" Vector__XXX
 SG_ CellBalanceFET_S1M1C14 m5 : 45|1@1+ (1,0) [0|0] "" Vector__XXX
 SG_ CellBalanceFET_S1M1C13 m5 : 29|1@1+ (1,0) [0|0] "" Vector__XXX
 SG_ CellBalanceFET_S1M1C12 m4 : 61|1@1+ (1,0) [0|0] "" Vector__XXX
 SG_ CellBalanceFET_S1M1C11 m4 : 45|1@1+ (1,0) [0|0] "" Vector__XXX
 SG_ CellBalanceFET_S1M1C10 m4 : 29|1@1+ (1,0) [0|0] "" Vector__XXX
 SG_ CellBalanceFET_S1M1C09 m3 : 61|1@1+ (1,0) [0|0] "" Vector__XXX
 SG_ CellBalanceFET_S1M1C08 m3 : 45|1@1+ (1,0) [0|0] "" Vector__XXX
 SG_ CellBalanceFET_S1M1C07 m3 : 29|1@1+ (1,0) [0|0] "" Vector__XXX
 SG_ CellBalanceFET_S1M1C06 m2 : 61|1@1+ (1,0) [0|0] "" Vector__XXX
 SG_ CellBalanceFET_S1M1C05 m2 : 45|1@1+ (1,0) [0|0] "" Vector__XXX
 SG_ CellBalanceFET_S1M1C04 m2 : 29|1@1+ (1,0) [0|0] "" Vector__XXX
 SG_ CellBalanceFET_S1M1C03 m1 : 61|1@1+ (1,0) [0|0] "" Vector__XXX
 SG_ CellBalanceFET_S1M1C02 m1 : 45|1@1+ (1,0) [0|0] "" Vector__XXX
 SG_ CellBalanceFET_S1M1C01 m1 : 29|1@1+ (1,0) [0|0] "" Vector__XXX
 SG_ CellVoltage_S1M5C18 m30 : 48|13@1+ (0.000610426077402027,0) [0|2] "V" Vector__XXX
 SG_ CellVoltage_S1M5C17 m30 : 32|13@1+ (0.000610426077402027,0) [0|2] "V" Vector__XXX
 SG_ CellVoltage_S1M5C16 m30 : 16|13@1+ (0.000610426077402027,0) [0|2] "V" Vector__XXX
 SG_ CellVoltage_S1M5C15 m29 : 48|13@1+ (0.000610426077402027,0) [0|2] "V" Vector__XXX
 SG_ CellVoltage_S1M5C14 m29 : 32|13@1+ (0.000610426077402027,0) [0|2] "V" Vector__XXX
 SG_ CellVoltage_S1M5C13 m29 : 16|13@1+ (0.000610426077402027,0) [0|2] "V" Vector__XXX
 SG_ CellVoltage_S1M5C12 m28 : 48|13@1+ (0.000610426077402027,0) [0|2] "V" Vector__XXX
 SG_ CellVoltage_S1M5C11 m28 : 32|13@1+ (0.000610426077402027,0) [0|2] "V" Vector__XXX
 SG_ CellVoltage_S1M5C10 m28 : 16|13@1+ (0.000610426077402027,0) [0|2] "V" Vector__XXX
 SG_ CellVoltage_S1M5C09 m27 : 48|13@1+ (0.000610426077402027,0) [0|2] "V" Vector__XXX
 SG_ CellVoltage_S1M5C08 m27 : 32|13@1+ (0.000610426077402027,0) [0|2] "V" Vector__XXX
 SG_ CellVoltage_S1M5C07 m27 : 16|13@1+ (0.000610426077402027,0) [0|2] "V" Vector__XXX
 SG_ CellVoltage_S1M5C06 m26 : 48|13@1+ (0.000610426077402027,0) [0|2] "V" Vector__XXX
 SG_ CellVoltage_S1M5C05 m26 : 32|13@1+ (0.000610426077402027,0) [0|2] "V" Vector__XXX
 SG_ CellVoltage_S1M5C04 m26 : 16|13@1+ (0.000610426077402027,0) [0|2] "V" Vector__XXX
 SG_ CellVoltage_S1M5C03 m25 : 48|13@1+ (0.000610426077402027,0) [0|2] "V" Vector__XXX
 SG_ CellVoltage_S1M5C02 m25 : 32|13@1+ (0.000610426077402027,0) [0|2] "V" Vector__XXX
 SG_ CellVoltage_S1M5C01 m25 : 16|13@1+ (0.000610426077402027,0) [0|2] "V" Vector__XXX
 SG_ CellVoltage_S1M4C18 m24 : 48|13@1+ (0.000610426077402027,0) [0|2] "V" Vector__XXX
 SG_ CellVoltage_S1M4C17 m24 : 32|13@1+ (0.000610426077402027,0) [0|2] "V" Vector__XXX
 SG_ CellVoltage_S1M4C16 m24 : 16|13@1+ (0.000610426077402027,0) [0|2] "V" Vector__XXX
 SG_ CellVoltage_S1M4C15 m23 : 48|13@1+ (0.000610426077402027,0) [0|2] "V" Vector__XXX
 SG_ CellVoltage_S1M4C14 m23 : 32|13@1+ (0.000610426077402027,0) [0|2] "V" Vector__XXX
 SG_ CellVoltage_S1M4C13 m23 : 16|13@1+ (0.000610426077402027,0) [0|2] "V" Vector__XXX
 SG_ CellVoltage_S1M4C12 m22 : 48|13@1+ (0.000610426077402027,0) [0|2] "V" Vector__XXX
 SG_ CellVoltage_S1M4C11 m22 : 32|13@1+ (0.000610426077402027,0) [0|2] "V" Vector__XXX
 SG_ CellVoltage_S1M4C10 m22 : 16|13@1+ (0.000610426077402027,0) [0|2] "V" Vector__XXX
 SG_ CellVoltage_S1M4C09 m21 : 48|13@1+ (0.000610426077402027,0) [0|2] "V" Vector__XXX
 SG_ CellVoltage_S1M4C08 m21 : 32|13@1+ (0.000610426077402027,0) [0|2] "V" Vector__XXX
 SG_ CellVoltage_S1M4C07 m21 : 16|13@1+ (0.000610426077402027,0) [0|2] "V" Vector__XXX
 SG_ CellVoltage_S1M4C06 m20 : 48|13@1+ (0.000610426077402027,0) [0|2] "V" Vector__XXX
 SG_ CellVoltage_S1M4C05 m20 : 32|13@1+ (0.000610426077402027,0) [0|2] "V" Vector__XXX
 SG_ CellVoltage_S1M4C04 m20 : 16|13@1+ (0.000610426077402027,0) [0|2] "V" Vector__XXX
 SG_ CellVoltage_S1M4C03 m19 : 48|13@1+ (0.000610426077402027,0) [0|2] "V" Vector__XXX
 SG_ CellVoltage_S1M4C02 m19 : 32|13@1+ (0.000610426077402027,0) [0|2] "V" Vector__XXX
 SG_ CellVoltage_S1M4C01 m19 : 16|13@1+ (0.000610426077402027,0) [0|2] "V" Vector__XXX
 SG_ CellVoltage_S1M3C18 m18 : 48|13@1+ (0.000610426077402027,0) [0|2] "V" Vector__XXX
 SG_ CellVoltage_S1M3C17 m18 : 32|13@1+ (0.000610426077402027,0) [0|2] "V" Vector__XXX
 SG_ CellVoltage_S1M3C16 m18 : 16|13@1+ (0.000610426077402027,0) [0|2] "V" Vector__XXX
 SG_ CellVoltage_S1M3C15 m17 : 48|13@1+ (0.000610426077402027,0) [0|2] "V" Vector__XXX
 SG_ CellVoltage_S1M3C14 m17 : 32|13@1+ (0.000610426077402027,0) [0|2] "V" Vector__XXX
 SG_ CellVoltage_S1M3C13 m17 : 16|13@1+ (0.000610426077402027,0) [0|2] "V" Vector__XXX
 SG_ CellVoltage_S1M3C12 m16 : 48|13@1+ (0.000610426077402027,0) [0|2] "V" Vector__XXX
 SG_ CellVoltage_S1M3C11 m16 : 32|13@1+ (0.000610426077402027,0) [0|2] "V" Vector__XXX
 SG_ CellVoltage_S1M3C10 m16 : 16|13@1+ (0.000610426077402027,0) [0|2] "V" Vector__XXX
 SG_ CellVoltage_S1M3C09 m15 : 48|13@1+ (0.000610426077402027,0) [0|2] "V" Vector__XXX
 SG_ CellVoltage_S1M3C08 m15 : 32|13@1+ (0.000610426077402027,0) [0|2] "V" Vector__XXX
 SG_ CellVoltage_S1M3C07 m15 : 16|13@1+ (0.000610426077402027,0) [0|2] "V" Vector__XXX
 SG_ CellVoltage_S1M3C06 m14 : 48|13@1+ (0.000610426077402027,0) [0|2] "V" Vector__XXX
 SG_ CellVoltage_S1M3C05 m14 : 32|13@1+ (0.000610426077402027,0) [0|2] "V" Vector__XXX
 SG_ CellVoltage_S1M3C04 m14 : 16|13@1+ (0.000610426077402027,0) [0|2] "V" Vector__XXX
 SG_ CellVoltage_S1M3C03 m13 : 48|13@1+ (0.000610426077402027,0) [0|2] "V" Vector__XXX
 SG_ CellVoltage_S1M3C02 m13 : 32|13@1+ (0.000610426077402027,0) [0|2] "V" Vector__XXX
 SG_ CellVoltage_S1M3C01 m13 : 16|13@1+ (0.000610426077402027,0) [0|2] "V" Vector__XXX
 SG_ CellVoltage_S1M2C18 m12 : 48|13@1+ (0.000610426077402027,0) [0|2] "V" Vector__XXX
 SG_ CellVoltage_S1M2C17 m12 : 32|13@1+ (0.000610426077402027,0) [0|2] "V" Vector__XXX
 SG_ CellVoltage_S1M2C16 m12 : 16|13@1+ (0.000610426077402027,0) [0|2] "V" Vector__XXX
 SG_ CellVoltage_S1M2C15 m11 : 48|13@1+ (0.000610426077402027,0) [0|2] "V" Vector__XXX
 SG_ CellVoltage_S1M2C14 m11 : 32|13@1+ (0.000610426077402027,0) [0|2] "V" Vector__XXX
 SG_ CellVoltage_S1M2C13 m11 : 16|13@1+ (0.000610426077402027,0) [0|2] "V" Vector__XXX
 SG_ CellVoltage_S1M2C12 m10 : 48|13@1+ (0.000610426077402027,0) [0|2] "V" Vector__XXX
 SG_ CellVoltage_S1M2C11 m10 : 32|13@1+ (0.000610426077402027,0) [0|2] "V" Vector__XXX
 SG_ CellVoltage_S1M2C10 m10 : 16|13@1+ (0.000610426077402027,0) [0|2] "V" Vector__XXX
 SG_ CellVoltage_S1M2C09 m9 : 48|13@1+ (0.000610426077402027,0) [0|2] "V" Vector__XXX
 SG_ CellVoltage_S1M2C08 m9 : 32|13@1+ (0.000610426077402027,0) [0|2] "V" Vector__XXX
 SG_ CellVoltage_S1M2C07 m9 : 16|13@1+ (0.000610426077402027,0) [0|2] "V" Vector__XXX
 SG_ CellVoltage_S1M2C06 m8 : 48|13@1+ (0.000610426077402027,0) [0|2] "V" Vector__XXX
 SG_ CellVoltage_S1M2C05 m8 : 32|13@1+ (0.000610426077402027,0) [0|2] "V" Vector__XXX
 SG_ CellVoltage_S1M2C04 m8 : 16|13@1+ (0.000610426077402027,0) [0|2] "V" Vector__XXX
 SG_ CellVoltage_S1M2C03 m7 : 48|13@1+ (0.000610426077402027,0) [0|2] "V" Vector__XXX
 SG_ CellVoltage_S1M2C02 m7 : 32|13@1+ (0.000610426077402027,0) [0|2] "V" Vector__XXX
 SG_ CellVoltage_S1M2C01 m7 : 16|13@1+ (0.000610426077402027,0) [0|2] "V" Vector__XXX
 SG_ CellVoltage_S1M1C18 m6 : 48|13@1+ (0.000610426077402027,0) [0|2] "V" Vector__XXX
 SG_ CellVoltage_S1M1C17 m6 : 32|13@1+ (0.000610426077402027,0) [0|2] "V" Vector__XXX
 SG_ CellVoltage_S1M1C16 m6 : 16|13@1+ (0.000610426077402027,0) [0|2] "V" Vector__XXX
 SG_ CellVoltage_S1M1C15 m5 : 48|13@1+ (0.000610426077402027,0) [0|2] "V" Vector__XXX
 SG_ CellVoltage_S1M1C14 m5 : 32|13@1+ (0.000610426077402027,0) [0|2] "V" Vector__XXX
 SG_ CellVoltage_S1M1C13 m5 : 16|13@1+ (0.000610426077402027,0) [0|2] "V" Vector__XXX
 SG_ CellVoltage_S1M1C12 m4 : 48|13@1+ (0.000610426077402027,0) [0|2] "V" Vector__XXX
 SG_ CellVoltage_S1M1C11 m4 : 32|13@1+ (0.000610426077402027,0) [0|2] "V" Vector__XXX
 SG_ CellVoltage_S1M1C10 m4 : 16|13@1+ (0.000610426077402027,0) [0|2] "V" Vector__XXX
 SG_ CellVoltage_S1M1C09 m3 : 48|13@1+ (0.000610426077402027,0) [0|2] "V" Vector__XXX
 SG_ CellVoltage_S1M1C08 m3 : 32|13@1+ (0.000610426077402027,0) [0|2] "V" Vector__XXX
 SG_ CellVoltage_S1M1C07 m3 : 16|13@1+ (0.000610426077402027,0) [0|2] "V" Vector__XXX
 SG_ CellVoltage_S1M1C06 m2 : 48|13@1+ (0.000610426077402027,0) [0|2] "V" Vector__XXX
 SG_ CellVoltage_S1M1C05 m2 : 32|13@1+ (0.000610426077402027,0) [0|2] "V" Vector__XXX
 SG_ CellVoltage_S1M1C04 m2 : 16|13@1+ (0.000610426077402027,0) [0|2] "V" Vector__XXX
 SG_ CellVoltage_S1M1C03 m1 : 48|13@1+ (0.000610426077402027,0) [0|2] "V" Vector__XXX
 SG_ CellVoltage_S1M1C02 m1 : 32|13@1+ (0.000610426077402027,0) [0|2] "V" Vector__XXX
 SG_ CellVoltage_S1M1C01 m1 : 16|13@1+ (0.000610426077402027,0) [0|2] "V" Vector__XXX
 SG_ CellTemp_S1M5TE m30 : 8|8@1+ (0.5,-40) [-40|87.5] "degC" Vector__XXX
 SG_ CellTemp_S1M5TD m29 : 8|8@1+ (0.5,-40) [-40|87.5] "degC" Vector__XXX
 SG_ CellTemp_S1M5TC m28 : 8|8@1+ (0.5,-40) [-40|87.5] "degC" Vector__XXX
 SG_ CellTemp_S1M5TB m26 : 8|8@1+ (0.5,-40) [-40|87.5] "degC" Vector__XXX
 SG_ CellTemp_S1M5TA m25 : 8|8@1+ (0.5,-40) [-40|87.5] "degC" Vector__XXX
 SG_ CellTemp_S1M4TE m24 : 8|8@1+ (0.5,-40) [-40|87.5] "degC" Vector__XXX
 SG_ CellTemp_S1M4TD m23 : 8|8@1+ (0.5,-40) [-40|87.5] "degC" Vector__XXX
 SG_ CellTemp_S1M4TC m22 : 8|8@1+ (0.5,-40) [-40|87.5] "degC" Vector__XXX
 SG_ CellTemp_S1M4TB m20 : 8|8@1+ (0.5,-40) [-40|87.5] "degC" Vector__XXX
 SG_ CellTemp_S1M4TA m19 : 8|8@1+ (0.5,-40) [-40|87.5] "degC" Vector__XXX
 SG_ CellTemp_S1M3TE m18 : 8|8@1+ (0.5,-40) [-40|87.5] "degC" Vector__XXX
 SG_ CellTemp_S1M3TD m17 : 8|8@1+ (0.5,-40) [-40|87.5] "degC" Vector__XXX
 SG_ CellTemp_S1M3TC m16 : 8|8@1+ (0.5,-40) [-40|87.5] "degC" Vector__XXX
 SG_ CellTemp_S1M3TB m14 : 8|8@1+ (0.5,-40) [-40|87.5] "degC" Vector__XXX
 SG_ CellTemp_S1M3TA m13 : 8|8@1+ (0.5,-40) [-40|87.5] "degC" Vector__XXX
 SG_ CellTemp_S1M2TE m12 : 8|8@1+ (0.5,-40) [-40|87.5] "degC" Vector__XXX
 SG_ CellTemp_S1M2TD m11 : 8|8@1+ (0.5,-40) [-40|87.5] "degC" Vector__XXX
 SG_ CellTemp_S1M2TC m10 : 8|8@1+ (0.5,-40) [-40|87.5] "degC" Vector__XXX
 SG_ CellTemp_S1M2TB m8 : 8|8@1+ (0.5,-40) [-40|87.5] "degC" Vector__XXX
 SG_ CellTemp_S1M2TA m7 : 8|8@1+ (0.5,-40) [-40|87.5] "degC" Vector__XXX
 SG_ CellTemp_S1M1TE m6 : 8|8@1+ (0.5,-40) [-40|87.5] "degC" Vector__XXX
 SG_ CellTemp_S1M1TD m5 : 8|8@1+ (0.5,-40) [-40|87.5] "degC" Vector__XXX
 SG_ CellTemp_S1M1TC m4 : 8|8@1+ (0.5,-40) [-40|87.5] "degC" Vector__XXX
 SG_ CellTemp_S1M1TB m2 : 8|8@1+ (0.5,-40) [-40|87.5] "degC" Vector__XXX
 SG_ CellTemp_S1M1TA m1 : 8|8@1+ (0.5,-40) [-40|87.5] "degC" Vector__XXX
 SG_ CellMultiplexor M : 0|6@1+ (1,0) [0|42] "" Vector__XXX

BO_ 900 Shelf_Summary_Shelf4: 8 Shelf4
 SG_ Shelf_IDJumpers_S1 : 52|4@1+ (1,0) [0|15] "" Vector__XXX
 SG_ Shelf_NumTempSensorsPerModule_S1 m2 : 35|3@1+ (1,0) [0|7] "" Vector__XXX
 SG_ Shelf_NumModulesPerShelf_S1 m2 : 16|3@1+ (1,0) [0|7] "" Vector__XXX
 SG_ Shelf_NumCellsPerModule_S1 m2 : 19|5@1+ (1,0) [0|18] "" Vector__XXX
 SG_ Shelf_NumCellsInTotal_S1 m2 : 56|7@1+ (1,0) [0|126] "" Vector__XXX
 SG_ Shelf_NumCellsInFault_S1 m1 : 56|7@1+ (1,0) [0|126] "" Vector__XXX
 SG_ Shelf_CellFault_UnderTemp_S1 m1 : 38|1@1+ (1,0) [0|0] "" Vector__XXX
 SG_ Shelf_CellFault_TempSensor_S1 m2 : 38|1@1+ (1,0) [0|0] "" Vector__XXX
 SG_ Shelf_CellFault_UnderVoltage_S1 m1 : 15|1@1+ (1,0) [0|0] "" Vector__XXX
 SG_ Shelf_CellFault_OverVoltage_S1 m3 : 15|1@1+ (1,0) [0|0] "" Vector__XXX
 SG_ Shelf_CellFault_OverTemp_S1 m3 : 38|1@1+ (1,0) [0|0] "" Vector__XXX
 SG_ Shelf_CellFault_OpenWire_S1 m2 : 15|1@1+ (1,0) [0|0] "" Vector__XXX
 SG_ Shelf_BalanceMode_Top_S1 m3 : 63|1@1+ (1,0) [0|0] "" Vector__XXX
 SG_ Shelf_BalanceMode_Target_S1 : 39|1@1+ (1,0) [0|0] "" Vector__XXX
 SG_ Shelf_BalanceMode_Delta_S1 m2 : 63|1@1+ (1,0) [0|0] "" Vector__XXX
 SG_ Shelf_BalanceMode_Bottom_S1 m1 : 63|1@1+ (1,0) [0|0] "" Vector__XXX
 SG_ Shelf_ShelfVoltageNow_S1 m2 : 40|12@1+ (0.1,0) [0|215] "V" Vector__XXX
 SG_ Shelf_ShelfVoltageMin_S1 m1 : 40|12@1+ (0.1,0) [0|215] "V" Vector__XXX
 SG_ Shelf_ShelfVoltageMax_S1 m3 : 40|12@1+ (0.1,0) [0|215] "V" Vector__XXX
 SG_ Shelf_NumCellsInBalance_S1 m3 : 56|7@1+ (1,0) [0|126] "" Vector__XXX
 SG_ Shelf_Multiplexor_S1 M : 0|2@1+ (1,0) [0|3] "" Vector__XXX
 SG_ Shelf_CellVoltageMinModule_S1 m1 : 16|3@1+ (1,0) [0|7] "" Vector__XXX
 SG_ Shelf_CellVoltageMinCell_S1 m1 : 19|5@1+ (1,0) [0|18] "" Vector__XXX
 SG_ Shelf_CellVoltageMin_S1 m1 : 2|13@1+ (0.000610426077402027,0) [0|5] "V" Vector__XXX
 SG_ Shelf_CellVoltageMaxModule_S1 m3 : 16|3@1+ (1,0) [0|7] "" Vector__XXX
 SG_ Shelf_CellVoltageMaxCell_S1 m3 : 19|5@1+ (1,0) [0|18] "" Vector__XXX
 SG_ Shelf_CellVoltageMax_S1 m3 : 2|13@1+ (0.000610426077402027,0) [0|5] "V" Vector__XXX
 SG_ Shelf_CellVoltageAvg_S1 m2 : 2|13@1+ (0.000610426077402027,0) [0|5] "V" Vector__XXX
 SG_ Shelf_CellTempMinModule_S1 m1 : 32|3@1+ (1,0) [0|7] "" Vector__XXX
 SG_ Shelf_CellTempMinSensor_S1 m1 : 35|3@1+ (1,0) [0|7] "" Vector__XXX
 SG_ Shelf_CellTempMin_S1 m1 : 24|8@1+ (0.5,-40) [-40|87.5] "degC" Vector__XXX
 SG_ Shelf_CellTempMaxModule_S1 m3 : 32|3@1+ (1,0) [0|7] "" Vector__XXX
 SG_ Shelf_CellTempMaxSensor_S1 m3 : 35|3@1+ (1,0) [0|7] "" Vector__XXX
 SG_ Shelf_CellTempMax_S1 m3 : 24|8@1+ (0.5,-40) [-40|87.5] "degC" Vector__XXX
 SG_ Shelf_CellTempAvg_S1 m2 : 24|8@1+ (0.5,-40) [-40|87.5] "degC" Vector__XXX

BO_ 916 Shelf_Details_Electrical_Shelf4: 8 Shelf4
 SG_ ShelfElectrical_24VPowerLimit_S1 : 40|8@1+ (0.25,0) [0|63.75] "W" Vector__XXX
 SG_ ShelfElectrical_24VPeakPower_S1 : 32|8@1+ (0.25,0) [0|63.75] "W" Vector__XXX
 SG_ ShelfElectrical_24VAvgPower_S1 : 24|8@1+ (0.25,0) [0|63.75] "W" Vector__XXX
 SG_ ShelfElectrical_HVVoltage_S1 : 48|14@1+ (0.02,0) [0|210] "V" Vector__XXX
 SG_ ShelfElectrical_24VVoltage_S1 : 12|12@1+ (0.00862,0) [0|36.3] "V" Vector__XXX
 SG_ ShelfElectrical_24VCurrent_S1 : 0|12@1+ (0.0008,0) [0|0] "A" Vector__XXX

BO_ 964 Module_Summary_Shelf4: 8 Shelf4
 SG_ Shelf_Hysteresis_S1 m5 : 24|8@1+ (0.000610426077402027,0) [0|0.155658649737517] "V" Vector__XXX
 SG_ Shelf_Threshold_S1 m5 : 8|14@1+ (0.000610426077402027,0) [0|10.0006104260774] "V" Vector__XXX
 SG_ ModuleVoltage_S1M5 m22 : 8|14@1+ (0.002,0) [0|32.766] "V" Vector__XXX
 SG_ ModuleVoltage_S1M4 m18 : 8|14@1+ (0.002,0) [0|32.766] "V" Vector__XXX
 SG_ ModuleVoltage_S1M3 m14 : 8|14@1+ (0.002,0) [0|32.766] "V" Vector__XXX
 SG_ ModuleVoltage_S1M2 m10 : 8|14@1+ (0.002,0) [0|32.766] "V" Vector__XXX
 SG_ ModuleVoltage_S1M1 m6 : 8|14@1+ (0.002,0) [0|32.766] "V" Vector__XXX
 SG_ ModuleVoltage_CellMinLoc_S1M5 m21 : 43|5@1+ (1,0) [0|18] "" Vector__XXX
 SG_ ModuleVoltage_CellMinLoc_S1M4 m17 : 43|5@1+ (1,0) [0|18] "" Vector__XXX
 SG_ ModuleVoltage_CellMinLoc_S1M3 m13 : 43|5@1+ (1,0) [0|18] "" Vector__XXX
 SG_ ModuleVoltage_CellMinLoc_S1M2 m9 : 43|5@1+ (1,0) [0|18] "" Vector__XXX
 SG_ ModuleVoltage_CellMinLoc_S1M1 m5 : 43|5@1+ (1,0) [0|18] "" Vector__XXX
 SG_ ModuleVoltage_CellMin_S1M5 m21 : 48|13@1+ (0.000610426077402027,0) [0|2] "V" Vector__XXX
 SG_ ModuleVoltage_CellMin_S1M4 m17 : 48|13@1+ (0.000610426077402027,0) [0|2] "V" Vector__XXX
 SG_ ModuleVoltage_CellMin_S1M3 m13 : 48|13@1+ (0.000610426077402027,0) [0|2] "V" Vector__XXX
 SG_ ModuleVoltage_CellMin_S1M2 m9 : 48|13@1+ (0.000610426077402027,0) [0|2] "V" Vector__XXX
 SG_ ModuleVoltage_CellMin_S1M1 m5 : 48|13@1+ (0.000610426077402027,0) [0|2] "V" Vector__XXX
 SG_ ModuleVoltage_CellMaxLoc_S1M5 m23 : 43|5@1+ (1,0) [0|18] "" Vector__XXX
 SG_ ModuleVoltage_CellMaxLoc_S1M4 m19 : 43|5@1+ (1,0) [0|18] "" Vector__XXX
 SG_ ModuleVoltage_CellMaxLoc_S1M3 m15 : 43|5@1+ (1,0) [0|18] "" Vector__XXX
 SG_ ModuleVoltage_CellMaxLoc_S1M2 m11 : 43|5@1+ (1,0) [0|18] "" Vector__XXX
 SG_ ModuleVoltage_CellMaxLoc_S1M1 m7 : 43|5@1+ (1,0) [0|18] "" Vector__XXX
 SG_ ModuleVoltage_CellMax_S1M5 m23 : 48|13@1+ (0.000610426077402027,0) [0|2] "V" Vector__XXX
 SG_ ModuleVoltage_CellMax_S1M4 m19 : 48|13@1+ (0.000610426077402027,0) [0|2] "V" Vector__XXX
 SG_ ModuleVoltage_CellMax_S1M3 m15 : 48|13@1+ (0.000610426077402027,0) [0|2] "V" Vector__XXX
 SG_ ModuleVoltage_CellMax_S1M2 m11 : 48|13@1+ (0.000610426077402027,0) [0|2] "V" Vector__XXX
 SG_ ModuleVoltage_CellMax_S1M1 m7 : 48|13@1+ (0.000610426077402027,0) [0|2] "V" Vector__XXX
 SG_ ModuleVoltage_CellAvg_S1M5 m22 : 48|13@1+ (0.000610426077402027,0) [0|2] "V" Vector__XXX
 SG_ ModuleVoltage_CellAvg_S1M4 m18 : 48|13@1+ (0.000610426077402027,0) [0|2] "V" Vector__XXX
 SG_ ModuleVoltage_CellAvg_S1M3 m14 : 48|13@1+ (0.000610426077402027,0) [0|2] "V" Vector__XXX
 SG_ ModuleVoltage_CellAvg_S1M2 m10 : 48|13@1+ (0.000610426077402027,0) [0|2] "V" Vector__XXX
 SG_ ModuleVoltage_CellAvg_S1M1 m6 : 48|13@1+ (0.000610426077402027,0) [0|2] "V" Vector__XXX
 SG_ ModuleTemp_PCB_S1M5 m22 : 24|8@1+ (0.5,-40) [-40|87.5] "degC" Vector__XXX
 SG_ ModuleTemp_PCB_S1M4 m18 : 24|8@1+ (0.5,-40) [-40|87.5] "degC" Vector__XXX
 SG_ ModuleTemp_PCB_S1M3 m14 : 24|8@1+ (0.5,-40) [-40|87.5] "degC" Vector__XXX
 SG_ ModuleTemp_PCB_S1M2 m10 : 24|8@1+ (0.5,-40) [-40|87.5] "degC" Vector__XXX
 SG_ ModuleTemp_PCB_S1M1 m6 : 24|8@1+ (0.5,-40) [-40|87.5] "degC" Vector__XXX
 SG_ ModuleTemp_CellMinLoc_S1M5 m21 : 40|3@1+ (1,0) [0|5] "" Vector__XXX
 SG_ ModuleTemp_CellMinLoc_S1M4 m17 : 40|3@1+ (1,0) [0|5] "" Vector__XXX
 SG_ ModuleTemp_CellMinLoc_S1M3 m13 : 40|3@1+ (1,0) [0|5] "" Vector__XXX
 SG_ ModuleTemp_CellMinLoc_S1M2 m9 : 40|3@1+ (1,0) [0|5] "" Vector__XXX
 SG_ ModuleTemp_CellMinLoc_S1M1 m5 : 40|3@1+ (1,0) [0|5] "" Vector__XXX
 SG_ ModuleTemp_CellMin_S1M5 m21 : 32|8@1+ (0.5,-40) [-40|87.5] "degC" Vector__XXX
 SG_ ModuleTemp_CellMin_S1M4 m17 : 32|8@1+ (0.5,-40) [-40|87.5] "degC" Vector__XXX
 SG_ ModuleTemp_CellMin_S1M3 m13 : 32|8@1+ (0.5,-40) [-40|87.5] "degC" Vector__XXX
 SG_ ModuleTemp_CellMin_S1M2 m9 : 32|8@1+ (0.5,-40) [-40|87.5] "degC" Vector__XXX
 SG_ ModuleTemp_CellMin_S1M1 m5 : 32|8@1+ (0.5,-40) [-40|87.5] "degC" Vector__XXX
 SG_ ModuleTemp_CellMaxLoc_S1M5 m23 : 40|3@1+ (1,0) [0|5] "" Vector__XXX
 SG_ ModuleTemp_CellMaxLoc_S1M4 m19 : 40|3@1+ (1,0) [0|5] "" Vector__XXX
 SG_ ModuleTemp_CellMaxLoc_S1M3 m15 : 40|3@1+ (1,0) [0|5] "" Vector__XXX
 SG_ ModuleTemp_CellMaxLoc_S1M2 m11 : 40|3@1+ (1,0) [0|5] "" Vector__XXX
 SG_ ModuleTemp_CellMaxLoc_S1M1 m7 : 40|3@1+ (1,0) [0|5] "" Vector__XXX
 SG_ ModuleTemp_CellMax_S1M5 m23 : 32|8@1+ (0.5,-40) [-40|87.5] "degC" Vector__XXX
 SG_ ModuleTemp_CellMax_S1M4 m19 : 32|8@1+ (0.5,-40) [-40|87.5] "degC" Vector__XXX
 SG_ ModuleTemp_CellMax_S1M3 m15 : 32|8@1+ (0.5,-40) [-40|87.5] "degC" Vector__XXX
 SG_ ModuleTemp_CellMax_S1M2 m11 : 32|8@1+ (0.5,-40) [-40|87.5] "degC" Vector__XXX
 SG_ ModuleTemp_CellMax_S1M1 m7 : 32|8@1+ (0.5,-40) [-40|87.5] "degC" Vector__XXX
 SG_ ModuleTemp_CellAvg_S1M5 m22 : 32|8@1+ (0.5,-40) [-40|87.5] "degC" Vector__XXX
 SG_ ModuleTemp_CellAvg_S1M4 m18 : 32|8@1+ (0.5,-40) [-40|87.5] "degC" Vector__XXX
 SG_ ModuleTemp_CellAvg_S1M3 m14 : 32|8@1+ (0.5,-40) [-40|87.5] "degC" Vector__XXX
 SG_ ModuleTemp_CellAvg_S1M2 m10 : 32|8@1+ (0.5,-40) [-40|87.5] "degC" Vector__XXX
 SG_ ModuleTemp_CellAvg_S1M1 m6 : 32|8@1+ (0.5,-40) [-40|87.5] "degC" Vector__XXX
 SG_ ModuleMultiplexor M : 0|5@1+ (1,0) [0|21] "" Vector__XXX

BO_ 324 Debug1_Shelf4: 6 Vector__XXX
 SG_ D_Shelf_num_ISL_resets m0 : 16|8@1+ (1,0) [0|0] "" Vector__XXX
 SG_ D_Shelf_MaxMinusMin m0 : 32|16@1+ (0.000610426077402027,0) [0|0] "" Vector__XXX
 SG_ D_Shelf_Thermal_Autobal_Bypass m0 : 13|1@1+ (1,0) [0|1] "" Vector__XXX
 SG_ D_Shelf_Acutal_OCV_Autobal m0 : 10|1@1+ (1,0) [0|1] "" Vector__XXX
 SG_ D_Shelf_Acutal_Charge_Autobal m0 : 12|1@1+ (1,0) [0|1] "" Vector__XXX
 SG_ D_Shelf_Acutal_Discharge_Autobal m0 : 11|1@1+ (1,0) [0|1] "" Vector__XXX
 SG_ D_Shelf_CMD_Charge_Autobal m0 : 9|1@1+ (1,0) [0|1] "" Vector__XXX
 SG_ D_Multiplexor M : 0|5@1+ (1,0) [0|0] "" Vector__XXX
 SG_ D_Shelf_CMD_Discharge_Autobal m0 : 8|1@1+ (1,0) [0|1] "" Vector__XXX

CM_ BO_ 3221225472 "This is a message for not used signals, created by Vector CANdb++ DBC OLE DB Provider.";
BA_DEF_  "BusType" STRING ;
BA_DEF_ SG_  "SystemSignalLongSymbol" STRING ;
BA_DEF_DEF_  "BusType" "CAN";
BA_DEF_DEF_  "SystemSignalLongSymbol" "";
BA_ "SystemSignalLongSymbol" SG_ 3221225472 SetpointElec_External_WhichShelv "SetpointElec_External_WhichShelves";
BA_ "SystemSignalLongSymbol" SG_ 3221225472 SetpointElec_External_TargetBala "SetpointElec_External_TargetBalanceVolt";
BA_ "SystemSignalLongSymbol" SG_ 3221225472 SetpointElec_External_DeltaBalan "SetpointElec_External_DeltaBalanceVolt";
BA_ "SystemSignalLongSymbol" SG_ 3221225472 SetpointElec_External_BottomBala "SetpointElec_External_BottomBalanceVolt";
VAL_ 3221225472 ShelfThermal_FanStateSummary_S1 3 "Fan Locked Rotor" 2 "Fan Speed Slow" 1 "Fan Unplugged" 0 "Fan Nominal" ;
VAL_ 3221225472 ShelfThermal_FanState_S1FR 3 "Fan Locked Rotor" 2 "Fan Speed Slow" 1 "Fan Unplugged" 0 "Fan Nominal" ;
VAL_ 3221225472 ShelfThermal_FanState_S1FM 3 "Fan Locked Rotor" 2 "Fan Speed Slow" 1 "Fan Unplugged" 0 "Fan Nominal" ;
VAL_ 3221225472 ShelfThermal_FanState_S1FL 3 "Fan Locked Rotor" 2 "Fan Speed Slow" 1 "Fan Unplugged" 0 "Fan Nominal" ;
VAL_ 967 ModuleMultiplexor 31 "Module 7, Max" 30 "Module 7, Avg" 29 "Module 7, Min" 27 "Module 6, Max" 26 "Module 6, Avg" 25 "Module 6, Min" 23 "Module 5, Max" 22 "Module 5, Avg" 21 "Module 5, Min" 19 "Module 4, Max" 18 "Module 4, Avg" 17 "Module 4, Min" 15 "Module 3, Max" 14 "Module 3, Avg" 13 "Module 3, Min" 11 "Module 2, Max" 10 "Module 2, Avg" 9 "Module 2, Min" 7 "Module 1, Max" 6 "Module 1, Avg" 5 "Module 1, Min" ;
VAL_ 966 ModuleMultiplexor 31 "Module 7, Max" 30 "Module 7, Avg" 29 "Module 7, Min" 27 "Module 6, Max" 26 "Module 6, Avg" 25 "Module 6, Min" 23 "Module 5, Max" 22 "Module 5, Avg" 21 "Module 5, Min" 19 "Module 4, Max" 18 "Module 4, Avg" 17 "Module 4, Min" 15 "Module 3, Max" 14 "Module 3, Avg" 13 "Module 3, Min" 11 "Module 2, Max" 10 "Module 2, Avg" 9 "Module 2, Min" 7 "Module 1, Max" 6 "Module 1, Avg" 5 "Module 1, Min" ;
VAL_ 965 ModuleMultiplexor 31 "Module 7, Max" 30 "Module 7, Avg" 29 "Module 7, Min" 27 "Module 6, Max" 26 "Module 6, Avg" 25 "Module 6, Min" 23 "Module 5, Max" 22 "Module 5, Avg" 21 "Module 5, Min" 19 "Module 4, Max" 18 "Module 4, Avg" 17 "Module 4, Min" 15 "Module 3, Max" 14 "Module 3, Avg" 13 "Module 3, Min" 11 "Module 2, Max" 10 "Module 2, Avg" 9 "Module 2, Min" 7 "Module 1, Max" 6 "Module 1, Avg" 5 "Module 1, Min" ;
VAL_ 964 ModuleMultiplexor 31 "Module 7, Max" 30 "Module 7, Avg" 29 "Module 7, Min" 27 "Module 6, Max" 26 "Module 6, Avg" 25 "Module 6, Min" 23 "Module 5, Max" 22 "Module 5, Avg" 21 "Module 5, Min" 19 "Module 4, Max" 18 "Module 4, Avg" 17 "Module 4, Min" 15 "Module 3, Max" 14 "Module 3, Avg" 13 "Module 3, Min" 11 "Module 2, Max" 10 "Module 2, Avg" 9 "Module 2, Min" 7 "Module 1, Max" 6 "Module 1, Avg" 5 "Module 1, Min" ;
